VERSION ""

NS_ :

BS_:

BU_: R_STR IAVAS ADAS ADAS_GW ENM THM CHR BAT BEV BEV_GW LCT STA ABG EPS IPMS BST VDC C_ECU C_ECU_GW

BO_ 1370 MCA55A: 8 ADAS_GW
 SG_ MCA55A_0_0_NETWORK_STATUS : 0|64@1+ (1,0) [0|0] ""  C_ECU

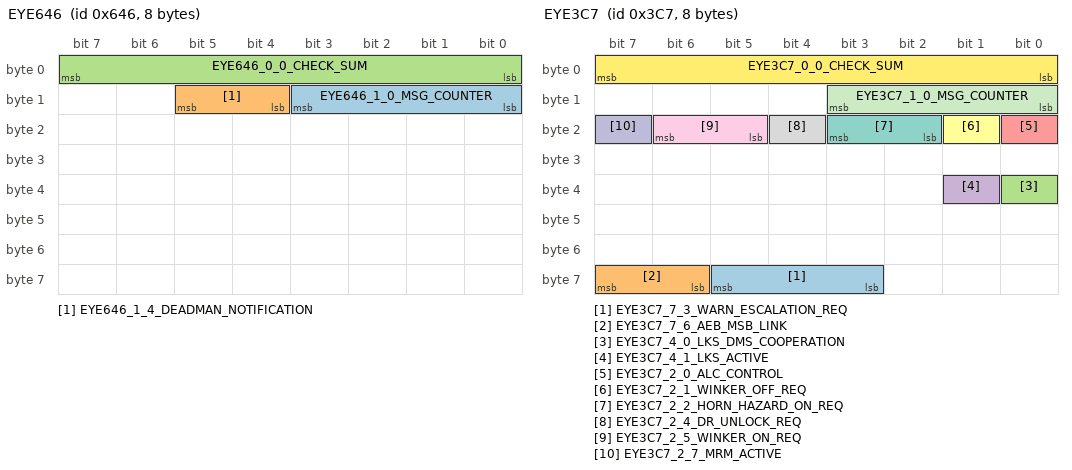
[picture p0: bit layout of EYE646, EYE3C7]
BO_ 1606 EYE646: 8 ADAS
 SG_ EYE646_1_0_MSG_COUNTER : 8|4@1+ (1,0) [0|15] ""  C_ECU_GW
 SG_ EYE646_1_4_DEADMAN_NOTIFICATION : 12|2@1+ (1,0) [0|3] ""  C_ECU_GW
 SG_ EYE646_0_0_CHECK_SUM : 0|8@1+ (1,0) [0|255] ""  C_ECU_GW

BO_ 967 EYE3C7: 8 ADAS
 SG_ EYE3C7_7_3_WARN_ESCALATION_REQ : 59|3@1+ (1,0) [0|7] ""  C_ECU_GW
 SG_ EYE3C7_7_6_AEB_MSB_LINK : 62|2@1+ (1,0) [0|3] ""  C_ECU_GW
 SG_ EYE3C7_4_0_LKS_DMS_COOPERATION : 32|1@1+ (1,0) [0|1] ""  IPMS,C_ECU_GW
 SG_ EYE3C7_4_1_LKS_ACTIVE : 33|1@1+ (1,0) [0|1] ""  IPMS,C_ECU_GW
 SG_ EYE3C7_2_0_ALC_CONTROL : 16|1@1+ (1,0) [0|1] ""  C_ECU_GW
 SG_ EYE3C7_2_1_WINKER_OFF_REQ : 17|1@1+ (1,0) [0|1] ""  C_ECU_GW
 SG_ EYE3C7_2_2_HORN_HAZARD_ON_REQ : 18|2@1+ (1,0) [0|3] ""  C_ECU_GW
 SG_ EYE3C7_2_4_DR_UNLOCK_REQ : 20|1@1+ (1,0) [0|1] ""  C_ECU_GW
 SG_ EYE3C7_2_5_WINKER_ON_REQ : 21|2@1+ (1,0) [0|3] ""  C_ECU_GW
 SG_ EYE3C7_2_7_MRM_ACTIVE : 23|1@1+ (1,0) [0|1] ""  C_ECU_GW
 SG_ EYE3C7_1_0_MSG_COUNTER : 8|4@1+ (1,0) [0|15] ""  IPMS,C_ECU_GW
 SG_ EYE3C7_0_0_CHECK_SUM : 0|8@1+ (1,0) [0|255] ""  IPMS,C_ECU_GW

BO_ 966 EYE3C6: 8 ADAS
 SG_ EYE3C6_7_0_VEHICLE_DIST_L_LANE1 : 56|7@1+ (1,0) [0|27] ""  C_ECU_GW
 SG_ EYE3C6_7_7_VEHICLE_L_LANE1 : 63|1@1+ (1,0) [0|1] ""  C_ECU_GW
 SG_ EYE3C6_6_0_VEHICLE_DIST_R_LANE1 : 48|7@1+ (1,0) [0|27] ""  C_ECU_GW
 SG_ EYE3C6_6_7_VEHICLE_R_LANE1 : 55|1@1+ (1,0) [0|1] ""  C_ECU_GW
 SG_ EYE3C6_5_0_VEHICLE_DIST_WY_WAY1 : 40|7@1+ (1,0) [0|27] ""  C_ECU_GW
 SG_ EYE3C6_5_7_VEHICLE_MY_WAY1 : 47|1@1+ (1,0) [0|1] ""  C_ECU_GW
 SG_ EYE3C6_4_0_SIDE_MOVEMENT : 32|8@1- (1,0) [-100|100] ""  C_ECU_GW
 SG_ EYE3C6_3_0_RADER_RR : 24|2@1+ (1,0) [0|3] ""  C_ECU_GW
 SG_ EYE3C6_3_2_RADER_RL : 26|2@1+ (1,0) [0|3] ""  C_ECU_GW
 SG_ EYE3C6_3_4_RADER_FR : 28|2@1+ (1,0) [0|3] ""  C_ECU_GW
 SG_ EYE3C6_3_6_RADER_FL : 30|2@1+ (1,0) [0|3] ""  C_ECU_GW
 SG_ EYE3C6_2_0_RADER_R : 16|2@1+ (1,0) [0|3] ""  C_ECU_GW
 SG_ EYE3C6_2_2_MY_WAY_LANE_CAR_COLOR : 18|2@1+ (1,0) [0|3] ""  C_ECU_GW
 SG_ EYE3C6_2_4_TARGET_CAR : 20|3@1+ (1,0) [0|7] ""  C_ECU_GW
 SG_ EYE3C6_2_7_ALC_STS : 23|1@1+ (1,0) [0|1] ""  C_ECU_GW
 SG_ EYE3C6_1_0_MSG_COUNTER : 8|4@1+ (1,0) [0|15] ""  C_ECU_GW
 SG_ EYE3C6_1_4_L_LANE_CAR_COLOR : 12|2@1+ (1,0) [0|3] ""  C_ECU_GW
 SG_ EYE3C6_1_6_R_LANE_CAR_COLOR : 14|2@1+ (1,0) [0|3] ""  C_ECU_GW
 SG_ EYE3C6_0_0_CHECK_SUM : 0|8@1+ (1,0) [0|255] ""  C_ECU_GW

BO_ 965 EYE3C5: 8 ADAS
 SG_ EYE3C5_7_0_GSR_AEBS_FUNC_INFO : 56|1@1+ (1,0) [0|1] ""  C_ECU_GW
 SG_ EYE3C5_7_1_CSTM_CRV_ADJUST : 57|2@1+ (1,0) [0|3] ""  C_ECU_GW
 SG_ EYE3C5_7_3_BRAKE_HAPTIC_CURR : 59|2@1+ (1,0) [0|3] ""  C_ECU_GW
 SG_ EYE3C5_7_5_SAFETY_MODE_FUNC_INFO : 61|1@1+ (1,0) [0|1] ""  C_ECU_GW
 SG_ EYE3C5_7_6_SAFETY_MODE_CURR : 62|1@1+ (1,0) [0|1] ""  C_ECU_GW
 SG_ EYE3C5_7_7_GSR_DDAW_FUNC_INFO : 63|1@1+ (1,0) [0|1] ""  C_ECU_GW
 SG_ EYE3C5_6_0_IND_SAFETY_MODE : 48|1@1+ (1,0) [0|1] ""  C_ECU_GW
 SG_ EYE3C5_6_1_ALC_ACTIVE_L : 49|1@1+ (1,0) [0|1] ""  C_ECU_GW
 SG_ EYE3C5_6_2_FLASHING_IND_SAFETY : 50|1@1+ (1,0) [0|1] ""  C_ECU_GW
 SG_ EYE3C5_6_3_OVERTAKE_FUNC_INFO : 51|1@1+ (1,0) [0|1] ""  C_ECU_GW
 SG_ EYE3C5_6_4_CRV_ADJUST_FUNC_INFO : 52|1@1+ (1,0) [0|1] ""  C_ECU_GW
 SG_ EYE3C5_6_5_STRG_TOUCHSENSOR_WRNG : 53|1@1+ (1,0) [0|1] ""  C_ECU_GW
 SG_ EYE3C5_6_6_ALC_ACTIVE_R : 54|1@1+ (1,0) [0|1] ""  C_ECU_GW
 SG_ EYE3C5_6_7_CSTM_GSR_ISA : 55|1@1+ (1,0) [0|1] ""  C_ECU_GW
 SG_ EYE3C5_5_0_LANE_COLOR_R : 40|2@1+ (1,0) [0|3] ""  C_ECU_GW
 SG_ EYE3C5_5_2_LINE_LANE_R : 42|2@1+ (1,0) [0|3] ""  C_ECU_GW
 SG_ EYE3C5_5_4_LANE_COLOR_L : 44|2@1+ (1,0) [0|3] ""  C_ECU_GW
 SG_ EYE3C5_5_6_LINE_LANE_L : 46|2@1+ (1,0) [0|3] ""  C_ECU_GW
 SG_ EYE3C5_4_0_ROAD_SHAPE_CURVE : 32|4@1+ (1,0) [0|15] ""  C_ECU_GW
 SG_ EYE3C5_4_4_ROAD_SHAPE_DIRECTION : 36|1@1+ (1,0) [0|1] ""  C_ECU_GW
 SG_ EYE3C5_4_5_CSTM_GSR_ELKS : 37|1@1+ (1,0) [0|1] ""  C_ECU_GW
 SG_ EYE3C5_4_6_MY_WAY_COLOR : 38|2@1+ (1,0) [0|3] ""  C_ECU_GW
 SG_ EYE3C5_3_0_AD_DRV_ICON : 24|2@1+ (1,0) [0|3] ""  C_ECU,C_ECU_GW
 SG_ EYE3C5_3_2_AUTO_HANDLE_ICON : 26|2@1+ (1,0) [0|3] ""  C_ECU_GW
 SG_ EYE3C5_3_4_WITH_HANDS_ICON : 28|1@1+ (1,0) [0|1] ""  C_ECU_GW
 SG_ EYE3C5_3_5_STRG_HAPTIC_WRNG : 29|1@1+ (1,0) [0|1] ""  C_ECU_GW
 SG_ EYE3C5_3_6_BRK_HPTC_FUNC_INFO : 30|1@1+ (1,0) [0|1] ""  C_ECU_GW
 SG_ EYE3C5_3_7_SPECIAL_DISP_INFO : 31|1@1+ (1,0) [0|1] ""  C_ECU_GW
 SG_ EYE3C5_2_0_SLOWDWN_CURVE_ICON : 16|3@1+ (1,0) [0|7] ""  C_ECU_GW
 SG_ EYE3C5_2_3_FLASHING_IND : 19|1@1+ (1,0) [0|1] ""  C_ECU_GW
 SG_ EYE3C5_2_4_ATTENTION_TOLLGATE : 20|2@1+ (1,0) [0|3] ""  C_ECU_GW
 SG_ EYE3C5_2_6_MAPLOCATOR_IND : 22|2@1+ (1,0) [0|3] ""  C_ECU_GW
 SG_ EYE3C5_1_0_MSG_COUNTER : 8|4@1+ (1,0) [0|15] ""  C_ECU_GW
 SG_ EYE3C5_1_4_ISA_FAIL_IND : 12|1@1+ (1,0) [0|1] ""  C_ECU_GW
 SG_ EYE3C5_1_5_SLWF_OFF_IND : 13|1@1+ (1,0) [0|1] ""  C_ECU_GW
 SG_ EYE3C5_1_6_CSTM_SLWF_SET : 14|1@1+ (1,0) [0|1] ""  C_ECU_GW
 SG_ EYE3C5_1_7_CSTM_TSR_SOUND_SET : 15|1@1+ (1,0) [0|1] ""  C_ECU_GW
 SG_ EYE3C5_0_0_CHECK_SUM : 0|8@1+ (1,0) [0|255] ""  C_ECU_GW

BO_ 964 EYE3C4: 8 ADAS
 SG_ EYE3C4_7_0_PCR_FAIL_OFF_IND : 56|2@1+ (1,0) [0|3] ""  C_ECU_GW
 SG_ EYE3C4_7_2_AES_FAIL_OFF_IND : 58|2@1+ (1,0) [0|3] ""  C_ECU_GW
 SG_ EYE3C4_7_4_LDP_FAIL_OFF_IND : 60|2@1+ (1,0) [0|3] ""  C_ECU_GW
 SG_ EYE3C4_7_6_ELK_FAIL_OFF_IND : 62|2@1+ (1,0) [0|3] ""  C_ECU_GW
 SG_ EYE3C4_6_0_MCAM_SYS_FAIL_HALT : 48|2@1+ (1,0) [0|3] ""  C_ECU_GW
 SG_ EYE3C4_6_2_MCAM_FUNC_INFO : 50|1@1+ (1,0) [0|1] ""  C_ECU_GW
 SG_ EYE3C4_6_3_EYE_DRV_ACTION_REQ : 51|3@1+ (1,0) [0|7] ""  C_ECU_GW
 SG_ EYE3C4_6_6_LDW_SND_OFF_FAIL_IND : 54|2@1+ (1,0) [0|3] ""  C_ECU_GW
 SG_ EYE3C4_5_0_EAM_GREEN : 40|2@1+ (1,0) [0|3] ""  C_ECU_GW
 SG_ EYE3C4_5_2_EAM_BLUE : 42|2@1+ (1,0) [0|3] ""  C_ECU_GW
 SG_ EYE3C4_5_4_EAM_GREEN_2 : 44|2@1+ (1,0) [0|3] ""  C_ECU_GW
 SG_ EYE3C4_5_6_FCW_SND_OFF_FAIL_IND : 46|2@1+ (1,0) [0|3] ""  C_ECU_GW
 SG_ EYE3C4_4_0_EAM_YELLOW : 32|4@1+ (1,0) [0|15] ""  C_ECU_GW
 SG_ EYE3C4_4_4_EAM_RED : 36|4@1+ (1,0) [0|15] ""  C_ECU_GW
 SG_ EYE3C4_3_0_CODE_NO_BUZZER : 24|8@1+ (1,0) [0|255] ""  C_ECU_GW
 SG_ EYE3C4_2_0_CODE_WARN : 16|8@1+ (1,0) [0|255] ""  C_ECU_GW
 SG_ EYE3C4_1_0_MSG_COUNTER : 8|4@1+ (1,0) [0|15] ""  C_ECU_GW
 SG_ EYE3C4_1_5_SNR_DRV_ACTION_REQ : 13|3@1+ (1,0) [0|7] ""  C_ECU_GW
 SG_ EYE3C4_0_0_CHECK_SUM : 0|8@1+ (1,0) [0|255] ""  C_ECU_GW

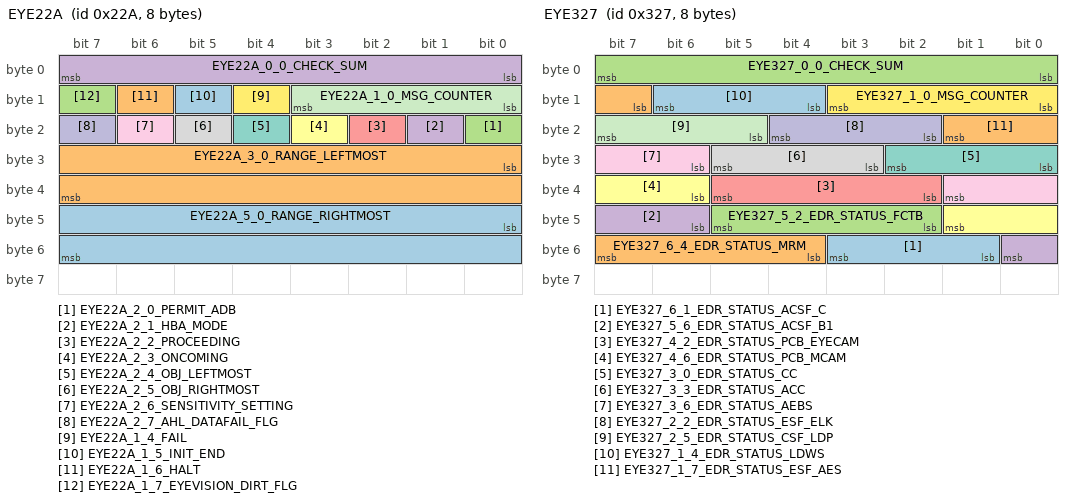
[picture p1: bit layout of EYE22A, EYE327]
BO_ 554 EYE22A: 8 ADAS
 SG_ EYE22A_5_0_RANGE_RIGHTMOST : 40|16@1- (0.1,0) [-3276.8|3276.7] "deg"  C_ECU_GW
 SG_ EYE22A_3_0_RANGE_LEFTMOST : 24|16@1- (0.1,0) [-3276.8|3276.7] "deg"  C_ECU_GW
 SG_ EYE22A_2_0_PERMIT_ADB : 16|1@1+ (1,0) [0|1] ""  C_ECU_GW
 SG_ EYE22A_2_1_HBA_MODE : 17|1@1+ (1,0) [0|1] ""  C_ECU,C_ECU_GW
 SG_ EYE22A_2_2_PROCEEDING : 18|1@1+ (1,0) [0|1] ""  C_ECU_GW
 SG_ EYE22A_2_3_ONCOMING : 19|1@1+ (1,0) [0|1] ""  C_ECU_GW
 SG_ EYE22A_2_4_OBJ_LEFTMOST : 20|1@1+ (1,0) [0|1] ""  C_ECU_GW
 SG_ EYE22A_2_5_OBJ_RIGHTMOST : 21|1@1+ (1,0) [0|1] ""  C_ECU_GW
 SG_ EYE22A_2_6_SENSITIVITY_SETTING : 22|1@1+ (1,0) [0|1] ""  C_ECU,C_ECU_GW
 SG_ EYE22A_2_7_AHL_DATAFAIL_FLG : 23|1@1+ (1,0) [0|1] ""  C_ECU_GW
 SG_ EYE22A_1_0_MSG_COUNTER : 8|4@1+ (1,0) [0|15] ""  C_ECU,C_ECU_GW
 SG_ EYE22A_1_4_FAIL : 12|1@1+ (1,0) [0|1] ""  C_ECU,C_ECU_GW
 SG_ EYE22A_1_5_INIT_END : 13|1@1+ (1,0) [0|1] ""  C_ECU,C_ECU_GW
 SG_ EYE22A_1_6_HALT : 14|1@1+ (1,0) [0|1] ""  C_ECU,C_ECU_GW
 SG_ EYE22A_1_7_EYEVISION_DIRT_FLG : 15|1@1+ (1,0) [0|1] ""  C_ECU_GW
 SG_ EYE22A_0_0_CHECK_SUM : 0|8@1+ (1,0) [0|255] ""  C_ECU,C_ECU_GW

BO_ 807 EYE327: 8 ADAS
 SG_ EYE327_6_1_EDR_STATUS_ACSF_C : 49|3@1+ (1,0) [0|7] ""  ABG
 SG_ EYE327_6_4_EDR_STATUS_MRM : 52|4@1+ (1,0) [0|15] ""  ABG
 SG_ EYE327_5_2_EDR_STATUS_FCTB : 42|4@1+ (1,0) [0|15] ""  ABG
 SG_ EYE327_5_6_EDR_STATUS_ACSF_B1 : 46|3@1+ (1,0) [0|7] ""  ABG
 SG_ EYE327_4_2_EDR_STATUS_PCB_EYECAM : 34|4@1+ (1,0) [0|15] ""  ABG
 SG_ EYE327_4_6_EDR_STATUS_PCB_MCAM : 38|4@1+ (1,0) [0|15] ""  ABG
 SG_ EYE327_3_0_EDR_STATUS_CC : 24|3@1+ (1,0) [0|7] ""  ABG
 SG_ EYE327_3_3_EDR_STATUS_ACC : 27|3@1+ (1,0) [0|7] ""  ABG
 SG_ EYE327_3_6_EDR_STATUS_AEBS : 30|4@1+ (1,0) [0|15] ""  ABG
 SG_ EYE327_2_2_EDR_STATUS_ESF_ELK : 18|3@1+ (1,0) [0|7] ""  ABG
 SG_ EYE327_2_5_EDR_STATUS_CSF_LDP : 21|3@1+ (1,0) [0|7] ""  ABG
 SG_ EYE327_1_0_MSG_COUNTER : 8|4@1+ (1,0) [0|15] ""  ABG
 SG_ EYE327_1_4_EDR_STATUS_LDWS : 12|3@1+ (1,0) [0|7] ""  ABG
 SG_ EYE327_1_7_EDR_STATUS_ESF_AES : 15|3@1+ (1,0) [0|7] ""  ABG
 SG_ EYE327_0_0_CHECK_SUM : 0|8@1+ (1,0) [0|255] ""  ABG

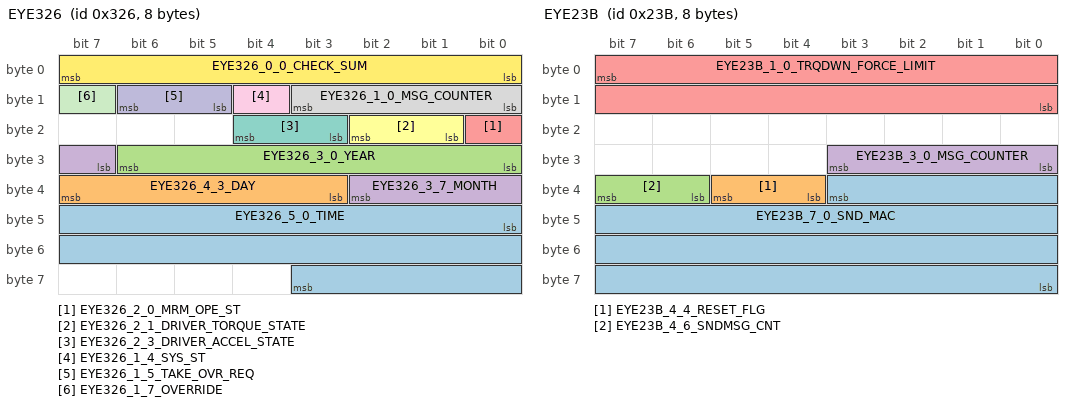
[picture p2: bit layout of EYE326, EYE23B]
BO_ 806 EYE326: 8 ADAS
 SG_ EYE326_5_0_TIME : 40|20@1+ (0.1,0) [0|86399.9] "sec"  C_ECU_GW
 SG_ EYE326_4_3_DAY : 35|5@1+ (1,0) [1|31] "日"  C_ECU_GW
 SG_ EYE326_3_0_YEAR : 24|7@1+ (1,2000) [2000|2126] "年"  C_ECU_GW
 SG_ EYE326_3_7_MONTH : 31|4@1+ (1,0) [1|12] "月"  C_ECU_GW
 SG_ EYE326_2_0_MRM_OPE_ST : 16|1@1+ (1,0) [0|1] ""  C_ECU_GW
 SG_ EYE326_2_1_DRIVER_TORQUE_STATE : 17|2@1+ (1,0) [0|3] ""  C_ECU_GW
 SG_ EYE326_2_3_DRIVER_ACCEL_STATE : 19|2@1+ (1,0) [0|3] ""  C_ECU_GW
 SG_ EYE326_1_0_MSG_COUNTER : 8|4@1+ (1,0) [0|15] ""  C_ECU_GW
 SG_ EYE326_1_4_SYS_ST : 12|1@1+ (1,0) [0|1] ""  C_ECU_GW
 SG_ EYE326_1_5_TAKE_OVR_REQ : 13|2@1+ (1,0) [0|3] ""  C_ECU_GW
 SG_ EYE326_1_7_OVERRIDE : 15|1@1+ (1,0) [0|1] ""  C_ECU_GW
 SG_ EYE326_0_0_CHECK_SUM : 0|8@1+ (1,0) [0|255] ""  C_ECU_GW

BO_ 805 EYE325: 8 ADAS
 SG_ EYE325_6_5_SONAR_DISP_INT : 53|1@1+ (1,0) [0|1] ""  C_ECU_GW
 SG_ EYE325_5_0_SONAR_R_L_CORNER_4LVL : 40|3@1+ (1,0) [0|7] ""  C_ECU_GW
 SG_ EYE325_5_3_SONAR_R_R_CORNER_4LVL : 43|3@1+ (1,0) [0|7] ""  C_ECU_GW
 SG_ EYE325_4_0_SONAR_R_CENTER : 32|3@1+ (1,0) [0|7] ""  C_ECU_GW
 SG_ EYE325_4_3_SONAR_LEVEL : 35|3@1+ (1,0) [0|7] ""  C_ECU_GW
 SG_ EYE325_4_6_RAB_WARNING : 38|2@1+ (1,0) [0|3] ""  C_ECU_GW
 SG_ EYE325_3_0_SONAR_R_L_CORNER : 24|2@1+ (1,0) [0|3] ""  C_ECU_GW
 SG_ EYE325_3_2_SONAR_R_R_CORNER : 26|2@1+ (1,0) [0|3] ""  C_ECU_GW
 SG_ EYE325_3_4_SONAR_R_L_SIDE : 28|2@1+ (1,0) [0|3] ""  C_ECU_GW
 SG_ EYE325_3_6_SONAR_R_R_SIDE : 30|2@1+ (1,0) [0|3] ""  C_ECU_GW
 SG_ EYE325_2_0_RAB_OFF : 16|1@1+ (1,0) [0|1] ""  C_ECU_GW
 SG_ EYE325_2_1_SONAR_OFF : 17|1@1+ (1,0) [0|1] ""  C_ECU_GW
 SG_ EYE325_2_2_SONAR_SYS_HALT : 18|2@1+ (1,0) [0|3] ""  C_ECU_GW
 SG_ EYE325_2_4_SONAR_SYS_FAIL : 20|2@1+ (1,0) [0|3] ""  C_ECU_GW
 SG_ EYE325_2_6_RAB_DISABLE : 22|1@1+ (1,0) [0|1] ""  C_ECU_GW
 SG_ EYE325_2_7_SONAR_DISABLE : 23|1@1+ (1,0) [0|1] ""  C_ECU_GW
 SG_ EYE325_1_0_MSG_COUNTER : 8|4@1+ (1,0) [0|15] ""  C_ECU_GW
 SG_ EYE325_1_4_CSTM_RAB_SET : 12|1@1+ (1,0) [0|1] ""  C_ECU_GW
 SG_ EYE325_1_5_CSTM_CLR_SNR_SET : 13|1@1+ (1,0) [0|1] ""  C_ECU_GW
 SG_ EYE325_1_6_RAB : 14|1@1+ (1,0) [0|1] ""  C_ECU_GW
 SG_ EYE325_1_7_SONAR_NO_DISP : 15|1@1+ (1,0) [0|1] ""  C_ECU_GW
 SG_ EYE325_0_0_CHECK_SUM : 0|8@1+ (1,0) [0|255] ""  C_ECU_GW

BO_ 804 EYE324: 8 ADAS
 SG_ EYE324_7_5_TSR_MODE_DISP : 61|2@1+ (1,0) [0|3] ""  C_ECU_GW
 SG_ EYE324_7_7_ICON_IND : 63|1@1+ (1,0) [0|1] ""  C_ECU_GW
 SG_ EYE324_6_0_COMPLEMENTARY_IND_C : 48|4@1+ (1,0) [0|15] ""  C_ECU_GW
 SG_ EYE324_6_4_COMPLEMENTARY_IND_D : 52|4@1+ (1,0) [0|15] ""  C_ECU_GW
 SG_ EYE324_5_0_SPEEDLIMIT_B : 40|8@1+ (1,0) [0|255] ""  C_ECU_GW
 SG_ EYE324_4_0_TRAFFIC_SIGN_B : 32|5@1+ (1,0) [0|31] ""  C_ECU_GW
 SG_ EYE324_4_5_FLASHING_IND_B : 37|1@1+ (1,0) [0|1] ""  C_ECU_GW
 SG_ EYE324_4_6_FRAME_COLOR_B : 38|2@1+ (1,0) [0|3] ""  C_ECU_GW
 SG_ EYE324_3_0_SPEEDLIMIT_A : 24|8@1+ (1,0) [0|255] ""  C_ECU_GW
 SG_ EYE324_2_0_TRAFFIC_SIGN_A : 16|5@1+ (1,0) [0|31] ""  C_ECU_GW
 SG_ EYE324_2_5_FLASHING_IND_A : 21|1@1+ (1,0) [0|1] ""  C_ECU_GW
 SG_ EYE324_2_6_FRAME_COLOR_A : 22|2@1+ (1,0) [0|3] ""  C_ECU_GW
 SG_ EYE324_1_0_MSG_COUNTER : 8|4@1+ (1,0) [0|15] ""  C_ECU_GW
 SG_ EYE324_1_4_FLASHING_IND_D : 12|1@1+ (1,0) [0|1] ""  C_ECU_GW
 SG_ EYE324_1_5_FLASHING_IND_C : 13|1@1+ (1,0) [0|1] ""  C_ECU_GW
 SG_ EYE324_1_6_ICON_COLOR : 14|2@1+ (1,0) [0|3] ""  C_ECU_GW
 SG_ EYE324_0_0_CHECK_SUM : 0|8@1+ (1,0) [0|255] ""  C_ECU_GW

BO_ 803 EYE323: 8 ADAS
 SG_ EYE323_7_0_ISA_OFFSET_CURR : 56|5@1+ (1,-10) [-10|10] ""  C_ECU_GW
 SG_ EYE323_7_5_SLIF_FUNC_INFO : 61|1@1+ (1,0) [0|1] ""  C_ECU_GW
 SG_ EYE323_7_6_ISA_FUNC_INFO : 62|1@1+ (1,0) [0|1] ""  C_ECU_GW
 SG_ EYE323_7_7_ISA_CUSTOMIZE_CURR : 63|1@1+ (1,0) [0|1] ""  C_ECU_GW
 SG_ EYE323_6_0_LDW_OFFSW_INFO : 48|1@1+ (1,0) [0|1] ""  C_ECU_GW
 SG_ EYE323_6_1_LDW_ON_OFF_SET : 49|1@1+ (1,0) [0|1] ""  C_ECU_GW
 SG_ EYE323_6_2_CSTM_DDAW_WARN_SET : 50|1@1+ (1,0) [0|1] ""  C_ECU_GW
 SG_ EYE323_6_3_IACC_FUNC_INFO : 51|1@1+ (1,0) [0|1] ""  C_ECU_GW
 SG_ EYE323_6_5_CSTM_LDW_TIMING_SET : 53|1@1+ (1,0) [0|1] ""  C_ECU_GW
 SG_ EYE323_6_6_CSTM_LDW_TIMING : 54|1@1+ (1,0) [0|1] ""  C_ECU_GW
 SG_ EYE323_6_7_SLOWDOWNL_FUNC_INFO : 55|1@1+ (1,0) [0|1] ""  C_ECU_GW
 SG_ EYE323_5_0_CNG_GRN_CONT_CURR : 40|1@1+ (1,0) [0|1] ""  C_ECU_GW
 SG_ EYE323_5_1_TRAFFIC_FUNC_INFO : 41|1@1+ (1,0) [0|1] ""  C_ECU_GW
 SG_ EYE323_5_2_FCW_OFFSW_INFO : 42|1@1+ (1,0) [0|1] ""  C_ECU_GW
 SG_ EYE323_5_3_FCW_ON_OFF_SET : 43|1@1+ (1,0) [0|1] ""  C_ECU_GW
 SG_ EYE323_5_4_WARNING_SEL_CURR : 44|1@1+ (1,0) [0|1] ""  C_ECU_GW
 SG_ EYE323_5_5_HAPT_FUNC_INFO : 45|1@1+ (1,0) [0|1] ""  C_ECU_GW
 SG_ EYE323_5_6_TOLLGATE_CONT_CURR : 46|1@1+ (1,0) [0|1] ""  C_ECU_GW
 SG_ EYE323_5_7_CURVE_CONT_CURR : 47|1@1+ (1,0) [0|1] ""  C_ECU_GW
 SG_ EYE323_4_0_FCTB_ICON_L : 32|2@1+ (1,0) [0|3] ""  C_ECU_GW
 SG_ EYE323_4_2_FCTB_ICON_R : 34|2@1+ (1,0) [0|3] ""  C_ECU_GW
 SG_ EYE323_4_4_FCW_CONT_CURR : 36|2@1+ (1,0) [0|3] ""  C_ECU_GW
 SG_ EYE323_4_6_FCW_DISPLAY_SEL : 38|2@1+ (1,0) [0|3] ""  C_ECU_GW
 SG_ EYE323_3_0_AES_FUNC_INFO : 24|1@1+ (1,0) [0|1] ""  C_ECU_GW
 SG_ EYE323_3_1_CSTM_TSR_NO_ENTRY_SET : 25|1@1+ (1,0) [0|1] ""  C_ECU_GW
 SG_ EYE323_3_2_CSTM_TSR_STOP_SET : 26|1@1+ (1,0) [0|1] ""  C_ECU_GW
 SG_ EYE323_3_3_CSTM_TSR_GIVE_WAY_SET : 27|1@1+ (1,0) [0|1] ""  C_ECU_GW
 SG_ EYE323_3_4_WILDERNESS : 28|1@1+ (1,0) [0|1] ""  C_ECU_GW
 SG_ EYE323_3_5_AES_OFF : 29|1@1+ (1,0) [0|1] ""  C_ECU_GW
 SG_ EYE323_3_6_FCTB_IND : 30|2@1+ (1,0) [0|3] ""  C_ECU_GW
 SG_ EYE323_2_0_CSTM_LDW_ALK_B : 16|2@1+ (1,0) [0|3] ""  C_ECU_GW
 SG_ EYE323_2_2_CSTM_P_CR : 18|1@1+ (1,0) [0|1] ""  C_ECU_GW
 SG_ EYE323_2_3_SLOWDOWN_FUNC_INFO2 : 19|1@1+ (1,0) [0|1] ""  C_ECU_GW
 SG_ EYE323_2_4_CID_CODE_WARN : 20|4@1+ (1,0) [0|15] ""  C_ECU_GW
 SG_ EYE323_1_0_MSG_COUNTER : 8|4@1+ (1,0) [0|15] ""  C_ECU_GW
 SG_ EYE323_1_4_DISP_FOLLOW_FORWARD : 12|1@1+ (1,0) [0|1] ""  C_ECU_GW
 SG_ EYE323_1_5_KEEP_LINE_SENTER_ACT : 13|1@1+ (1,0) [0|1] ""  C_ECU_GW
 SG_ EYE323_1_6_DDAW_FAIL_OFF : 14|2@1+ (1,0) [0|3] ""  C_ECU_GW
 SG_ EYE323_0_0_CHECK_SUM : 0|8@1+ (1,0) [0|255] ""  C_ECU_GW

BO_ 802 EYE322: 8 ADAS
 SG_ EYE322_7_0_CSTM_ACC_CONT_SET : 56|2@1+ (1,0) [0|3] ""  C_ECU_GW
 SG_ EYE322_7_2_ELK_OFF_IND : 58|1@1+ (1,0) [0|1] ""  C_ECU_GW
 SG_ EYE322_7_3_LIGHT_EAM_YELLOW : 59|2@1+ (1,0) [0|3] ""  C_ECU_GW
 SG_ EYE322_7_5_BROKEN_LINE_L : 61|1@1+ (1,0) [0|1] ""  C_ECU_GW
 SG_ EYE322_7_6_TJA_ACTIVE : 62|1@1+ (1,0) [0|1] ""  C_ECU_GW
 SG_ EYE322_7_7_BROKEN_LINE_R : 63|1@1+ (1,0) [0|1] ""  C_ECU_GW
 SG_ EYE322_6_0_CSTM_MIS_AT_START : 48|2@1+ (1,0) [0|3] ""  C_ECU_GW
 SG_ EYE322_6_2_CSTM_ALK_TJA_SET : 50|1@1+ (1,0) [0|1] ""  C_ECU_GW
 SG_ EYE322_6_3_CSTM_LANE_SET : 51|1@1+ (1,0) [0|1] ""  C_ECU_GW
 SG_ EYE322_6_4_LDP_OFF_IND : 52|1@1+ (1,0) [0|1] ""  C_ECU_GW
 SG_ EYE322_6_5_INDICATOR_MODE_L : 53|2@1+ (1,0) [0|3] ""  C_ECU_GW
 SG_ EYE322_6_7_CSTM_ELK_SET : 55|1@1+ (1,0) [0|1] ""  C_ECU_GW
 SG_ EYE322_5_0_CSTM_MIS_AT_BACK : 40|1@1+ (1,0) [0|1] ""  C_ECU_GW
 SG_ EYE322_5_1_CSTM_ALK_TJA : 41|1@1+ (1,0) [0|1] ""  C_ECU_GW
 SG_ EYE322_5_2_CSTM_SAS : 42|1@1+ (1,0) [0|1] ""  C_ECU_GW
 SG_ EYE322_5_3_CSTM_HBA : 43|1@1+ (1,0) [0|1] ""  C_ECU_GW
 SG_ EYE322_5_4_CSTM_ACC_CONT : 44|1@1+ (1,0) [0|1] ""  C_ECU_GW
 SG_ EYE322_5_5_CSTM_LANE : 45|1@1+ (1,0) [0|1] ""  C_ECU_GW
 SG_ EYE322_5_6_LDW_SOUND_OFF_IND : 46|1@1+ (1,0) [0|1] ""  C_ECU_GW
 SG_ EYE322_5_7_CSTM_ELK_SET : 47|1@1+ (1,0) [0|1] ""  C_ECU_GW
 SG_ EYE322_4_0_CODE_WARN : 32|5@1+ (1,0) [0|31] ""  C_ECU_GW
 SG_ EYE322_4_5_CSTM_GSR : 37|1@1+ (1,0) [0|1] ""  C_ECU_GW
 SG_ EYE322_3_0_LANE_L : 24|2@1+ (1,0) [0|3] ""  C_ECU_GW
 SG_ EYE322_3_2_LANE_R : 26|2@1+ (1,0) [0|3] ""  C_ECU_GW
 SG_ EYE322_3_4_LANE_L_COLOR : 28|2@1+ (1,0) [0|3] ""  C_ECU_GW
 SG_ EYE322_3_6_LANE_R_COLOR : 30|2@1+ (1,0) [0|3] ""  C_ECU_GW
 SG_ EYE322_2_0_FCW_OFF_IND : 16|1@1+ (1,0) [0|1] ""  C_ECU_GW
 SG_ EYE322_2_1_MOV_EYESIGHT_SCREEN : 17|1@1+ (1,0) [0|1] ""  C_ECU_GW
 SG_ EYE322_2_2_ALK_ICON : 18|2@1+ (1,0) [0|3] ""  C_ECU,C_ECU_GW
 SG_ EYE322_2_4_INDICATOR_CTRL_REQ : 20|1@1+ (1,0) [0|1] ""  C_ECU_GW
 SG_ EYE322_2_5_INDICATOR_MODE_R : 21|2@1+ (1,0) [0|3] ""  C_ECU_GW
 SG_ EYE322_2_7_LIMITER_BACK_SPEED : 23|1@1+ (1,0) [0|1] ""  C_ECU_GW
 SG_ EYE322_1_0_MSG_COUNTER : 8|4@1+ (1,0) [0|15] ""  IPMS,C_ECU_GW
 SG_ EYE322_1_4_CODE_NO_BUZZER : 12|3@1+ (1,0) [0|7] ""  C_ECU_GW
 SG_ EYE322_1_7_DISTWARN_DMS : 15|1@1+ (1,0) [0|1] ""  IPMS,C_ECU_GW
 SG_ EYE322_0_0_CHECK_SUM : 0|8@1+ (1,0) [0|255] ""  IPMS,C_ECU_GW

BO_ 801 EYE321: 8 ADAS
 SG_ EYE321_7_0_INFO_DIST_FORWARD : 56|4@1+ (1,0) [0|15] ""  C_ECU_GW
 SG_ EYE321_7_4_INFO_KEEP_STOP : 60|1@1+ (1,0) [0|1] ""  C_ECU_GW
 SG_ EYE321_7_5_INFO_READY : 61|1@1+ (1,0) [0|1] ""  C_ECU_GW
 SG_ EYE321_7_6_INFO_SET_CC : 62|1@1+ (1,0) [0|1] ""  C_ECU_GW
 SG_ EYE321_7_7_INFO_OFF : 63|1@1+ (1,0) [0|1] ""  C_ECU_GW
 SG_ EYE321_6_0_FAIL_EYESIGHT : 48|1@1+ (1,0) [0|1] ""  C_ECU_GW
 SG_ EYE321_6_1_MOV_EYESIGHT_SCREEN : 49|1@1+ (1,0) [0|1] ""  C_ECU_GW
 SG_ EYE321_6_2_IND_VEHICLE : 50|1@1+ (1,0) [0|1] ""  C_ECU_GW
 SG_ EYE321_6_3_BRAKELAMP_VEHICLE : 51|1@1+ (1,0) [0|1] ""  C_ECU_GW
 SG_ EYE321_6_4_IND_FORWARD_VECL : 52|1@1+ (1,0) [0|1] ""  C_ECU_GW
 SG_ EYE321_6_5_BRAKELAMP_FORWARD : 53|1@1+ (1,0) [0|1] ""  C_ECU_GW
 SG_ EYE321_6_6_CC_OR_LIM_SON : 54|1@1+ (1,0) [0|1] ""  C_ECU_GW
 SG_ EYE321_6_7_TEMP_OFF_STATE : 55|1@1+ (1,0) [0|1] ""  C_ECU_GW
 SG_ EYE321_5_0_INFO_SET_SPD : 40|8@1+ (1,0) [0|255] "km/h or MPH"  C_ECU_GW
 SG_ EYE321_4_0_ACC_MODE : 32|2@1+ (1,0) [0|3] ""  C_ECU,C_ECU_GW
 SG_ EYE321_4_2_SRVD_LASTMEM_ST_REQ : 34|1@1+ (1,0) [0|1] ""  C_ECU_GW
 SG_ EYE321_4_3_INFO_MAIN_CC : 35|2@1+ (1,0) [0|3] ""  C_ECU,C_ECU_GW
 SG_ EYE321_4_5_TRAFFIC_LIGHT : 37|3@1+ (1,0) [0|7] ""  C_ECU_GW
 SG_ EYE321_3_0_CODE_HALT : 24|3@1+ (1,0) [0|7] ""  C_ECU_GW
 SG_ EYE321_3_3_ELK_EQUIP : 27|1@1+ (1,0) [0|1] ""  C_ECU_GW
 SG_ EYE321_3_4_SET_DIST : 28|3@1+ (1,0) [0|7] ""  C_ECU_GW
 SG_ EYE321_3_7_TJA : 31|1@1+ (1,0) [0|1] ""  C_ECU_GW
 SG_ EYE321_2_0_ACC_CANCEL_OR_CSTM : 16|4@1+ (1,0) [0|15] ""  C_ECU_GW
 SG_ EYE321_2_4_ALK_CANCEL_OR_CSTM : 20|3@1+ (1,0) [0|7] ""  C_ECU_GW
 SG_ EYE321_2_7_ALK_CANCEL_DISP_TYPE : 23|1@1+ (1,0) [0|1] ""  C_ECU_GW
 SG_ EYE321_1_0_MSG_COUNTER : 8|4@1+ (1,0) [0|15] ""  C_ECU_GW
 SG_ EYE321_1_4_PRECRASH_BRAKE_OFF : 12|1@1+ (1,0) [0|1] ""  C_ECU_GW
 SG_ EYE321_1_5_LANE_DEPARTURE_OFF : 13|1@1+ (1,0) [0|1] ""  C_ECU_GW
 SG_ EYE321_1_6_MET_AD_DRV_ASS : 14|1@1+ (1,0) [0|1] ""  C_ECU_GW
 SG_ EYE321_1_7_ALC_EQUIP : 15|1@1+ (1,0) [0|1] ""  C_ECU_GW
 SG_ EYE321_0_0_CHECK_SUM : 0|8@1+ (1,0) [0|255] ""  C_ECU_GW

BO_ 571 EYE23B: 8 ADAS
 SG_ EYE23B_7_0_SND_MAC : 35|28@0+ (1,0) [0|268435455] "" Vector__XXX
 SG_ EYE23B_4_4_RESET_FLG : 37|2@0+ (1,0) [0|3] "" Vector__XXX
 SG_ EYE23B_4_6_SNDMSG_CNT : 39|2@0+ (1,0) [0|3] "" Vector__XXX
 SG_ EYE23B_3_0_MSG_COUNTER : 27|4@0+ (1,0) [0|15] "" Vector__XXX
 SG_ EYE23B_1_0_TRQDWN_FORCE_LIMIT : 7|16@0+ (1.6,0) [0|408] "Nm" Vector__XXX

BO_ 556 EYE22C: 8 ADAS
 SG_ EYE22C_7_0_COMMANDSW_CC : 56|3@1+ (1,0) [0|7] ""  C_ECU,C_ECU_GW
 SG_ EYE22C_7_3_MODE_CC : 59|1@1+ (1,0) [0|1] ""  C_ECU_GW
 SG_ EYE22C_7_4_CC_SETLAMP_INFO : 60|1@1+ (1,0) [0|1] ""  C_ECU_GW
 SG_ EYE22C_7_5_MSA_CNT_STS_EGI_HEV : 61|1@1+ (1,0) [0|1] ""  C_ECU_GW
 SG_ EYE22C_7_6_SET_MSA : 62|1@1+ (1,0) [0|1] ""  C_ECU_GW
 SG_ EYE22C_7_7_SET_CC : 63|1@1+ (1,0) [0|1] ""  C_ECU_GW
 SG_ EYE22C_5_0_TRQDWN_FORCE_LIMIT : 40|16@1+ (1.6,0) [0|408] "Nm"  C_ECU_GW
 SG_ EYE22C_4_0_BLIPPING_INHI : 32|1@1+ (1,0) [0|1] ""  C_ECU_GW
 SG_ EYE22C_4_4_ACTIVE_BRAKE_ACC : 36|1@1+ (1,0) [0|1] ""  C_ECU_GW
 SG_ EYE22C_4_5_REQ_FMW : 37|1@1+ (1,0) [0|1] ""  C_ECU_GW
 SG_ EYE22C_4_6_FLG_BEFORE_RESERVE : 38|1@1+ (1,0) [0|1] ""  C_ECU_GW
 SG_ EYE22C_4_7_REQ_TARGET_TORQUE : 39|1@1+ (1,0) [0|1] ""  C_ECU_GW
 SG_ EYE22C_2_0_TGT_SPD_TRQ_FORCE : 16|16@1+ (0.1,-1000) [-1000|5553.5] "Nm"  C_ECU_GW
 SG_ EYE22C_1_0_MSG_COUNTER : 8|4@1+ (1,0) [0|15] ""  C_ECU_GW
 SG_ EYE22C_1_4_FLG_ADAPTIVE_CC : 12|1@1+ (1,0) [0|1] ""  C_ECU_GW
 SG_ EYE22C_1_5_MAIN_CC : 13|1@1+ (1,0) [0|1] ""  C_ECU_GW
 SG_ EYE22C_1_6_FLG_EYESIGHT_VERSION : 14|1@1+ (1,0) [0|1] ""  C_ECU_GW
 SG_ EYE22C_1_7_FAIL_EYESIGHT : 15|1@1+ (1,0) [0|1] ""  C_ECU_GW
 SG_ EYE22C_0_0_CHECK_SUM : 0|8@1+ (1,0) [0|255] ""  C_ECU_GW

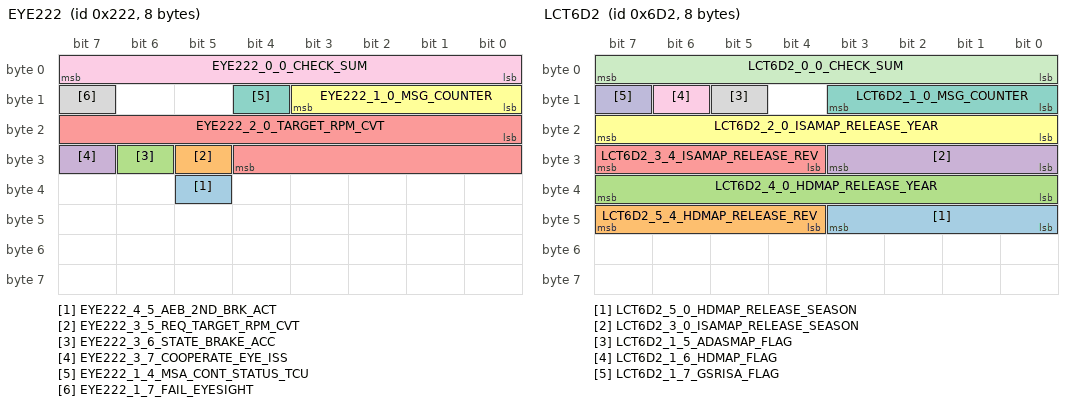
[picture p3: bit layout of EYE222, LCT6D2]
BO_ 546 EYE222: 8 ADAS
 SG_ EYE222_4_5_AEB_2ND_BRK_ACT : 37|1@1+ (1,0) [0|1] "" Vector__XXX
 SG_ EYE222_3_5_REQ_TARGET_RPM_CVT : 29|1@1+ (1,0) [0|1] "" Vector__XXX
 SG_ EYE222_3_6_STATE_BRAKE_ACC : 30|1@1+ (1,0) [0|1] "" Vector__XXX
 SG_ EYE222_3_7_COOPERATE_EYE_ISS : 31|1@1+ (1,0) [0|1] "" Vector__XXX
 SG_ EYE222_2_0_TARGET_RPM_CVT : 16|13@1+ (1,0) [0|8191] "rpm" Vector__XXX
 SG_ EYE222_1_0_MSG_COUNTER : 8|4@1+ (1,0) [0|15] "" Vector__XXX
 SG_ EYE222_1_4_MSA_CONT_STATUS_TCU : 12|1@1+ (1,0) [0|1] "" Vector__XXX
 SG_ EYE222_1_7_FAIL_EYESIGHT : 15|1@1+ (1,0) [0|1] "" Vector__XXX
 SG_ EYE222_0_0_CHECK_SUM : 0|8@1+ (1,0) [0|255] "" Vector__XXX

BO_ 545 EYE221: 8 ADAS
 SG_ EYE221_7_0_COMMANDSW_CC : 56|3@1+ (1,0) [0|7] ""  C_ECU,C_ECU_GW
 SG_ EYE221_7_3_MODE_CC : 59|1@1+ (1,0) [0|1] ""  C_ECU_GW
 SG_ EYE221_7_4_MSA_CNT_STS_EGI_HEV : 60|2@1+ (1,0) [0|2] ""  C_ECU_GW
 SG_ EYE221_7_6_EQUIP_MSA : 62|1@1+ (1,0) [0|1] ""  C_ECU_GW
 SG_ EYE221_7_7_INHIBIT_FUEL_CUT : 63|1@1+ (1,0) [0|1] ""  C_ECU_GW
 SG_ EYE221_5_0_TRQDWN_FORCE_LIMIT : 40|16@1+ (1.6,0) [0|408] "Nm"  C_ECU_GW
 SG_ EYE221_4_0_STATE_TRACKING : 32|1@1+ (1,0) [0|1] ""  C_ECU_GW
 SG_ EYE221_4_1_STATE_LSF : 33|1@1+ (1,0) [0|1] ""  C_ECU_GW
 SG_ EYE221_4_2_FORCED_CANCEL_ACC : 34|1@1+ (1,0) [0|1] ""  C_ECU_GW
 SG_ EYE221_4_3_BRAKE_TYPE : 35|1@1+ (1,0) [0|1] ""  C_ECU_GW
 SG_ EYE221_4_4_ACTIVE_BRAKE_ACC : 36|1@1+ (1,0) [0|1] ""  C_ECU_GW
 SG_ EYE221_4_5_REQ_FMW : 37|1@1+ (1,0) [0|1] ""  C_ECU_GW
 SG_ EYE221_4_6_FLG_BEFORE_RESERVE : 38|1@1+ (1,0) [0|1] ""  C_ECU_GW
 SG_ EYE221_4_7_REQ_TARGET_TORQUE : 39|1@1+ (1,0) [0|1] ""  C_ECU_GW
 SG_ EYE221_2_0_TGT_SPD_TRQ_FORCE : 16|16@1+ (0.1,-1000) [-1000|5553.5] "Nm"  C_ECU_GW
 SG_ EYE221_1_0_MSG_COUNTER : 8|4@1+ (1,0) [0|15] ""  C_ECU,C_ECU_GW
 SG_ EYE221_1_4_FLG_ADAPTIVE_CC : 12|1@1+ (1,0) [0|1] ""  C_ECU_GW
 SG_ EYE221_1_5_CANCEL_SW_INFO : 13|1@1+ (1,0) [0|1] ""  C_ECU_GW
 SG_ EYE221_1_6_FLG_EYESIGHT_VERSION : 14|1@1+ (1,0) [0|1] ""  C_ECU_GW
 SG_ EYE221_1_7_FAIL_EYESIGHT : 15|1@1+ (1,0) [0|1] ""  C_ECU_GW
 SG_ EYE221_0_0_CHECK_SUM : 0|8@1+ (1,0) [0|255] ""  C_ECU,C_ECU_GW

BO_ 1352 EYE548: 8 ADAS
 SG_ EYE548_7_0_NETWORK_STATUS : 7|64@0+ (1,0) [0|0] ""  C_ECU

BO_ 1746 LCT6D2: 8 LCT
 SG_ LCT6D2_5_0_HDMAP_RELEASE_SEASON : 40|4@1+ (1,0) [0|4] ""  C_ECU_GW
 SG_ LCT6D2_5_4_HDMAP_RELEASE_REV : 44|4@1+ (1,0) [1|14] ""  C_ECU_GW
 SG_ LCT6D2_4_0_HDMAP_RELEASE_YEAR : 32|8@1+ (1,2000) [2000|2099] "年"  C_ECU_GW
 SG_ LCT6D2_3_0_ISAMAP_RELEASE_SEASON : 24|4@1+ (1,0) [1|4] ""  C_ECU_GW
 SG_ LCT6D2_3_4_ISAMAP_RELEASE_REV : 28|4@1+ (1,0) [1|14] ""  C_ECU_GW
 SG_ LCT6D2_2_0_ISAMAP_RELEASE_YEAR : 16|8@1+ (1,2000) [0|99] "年"  C_ECU_GW
 SG_ LCT6D2_1_0_MSG_COUNTER : 8|4@1+ (1,0) [0|15] ""  C_ECU_GW
 SG_ LCT6D2_1_5_ADASMAP_FLAG : 13|1@1+ (1,0) [0|1] ""  C_ECU_GW
 SG_ LCT6D2_1_6_HDMAP_FLAG : 14|1@1+ (1,0) [0|1] ""  C_ECU_GW
 SG_ LCT6D2_1_7_GSRISA_FLAG : 15|1@1+ (1,0) [0|1] ""  C_ECU_GW
 SG_ LCT6D2_0_0_CHECK_SUM : 0|8@1+ (1,0) [0|255] ""  C_ECU_GW

BO_ 1369 LCT559: 8 LCT
 SG_ LCT559_0_0_NETWORK_STATUS : 0|64@1+ (1,0) [0|0] ""  C_ECU

BO_ 1375 FCRR55F: 8 ADAS_GW
 SG_ FCR55F_7_0_NETWORK_STATUS : 56|64@1+ (1,0) [0|0] ""  C_ECU

BO_ 1374 FCRL55E: 8 ADAS_GW
 SG_ FCR55E_7_0_NETWORK_STATUS : 56|64@1+ (1,0) [0|0] ""  C_ECU

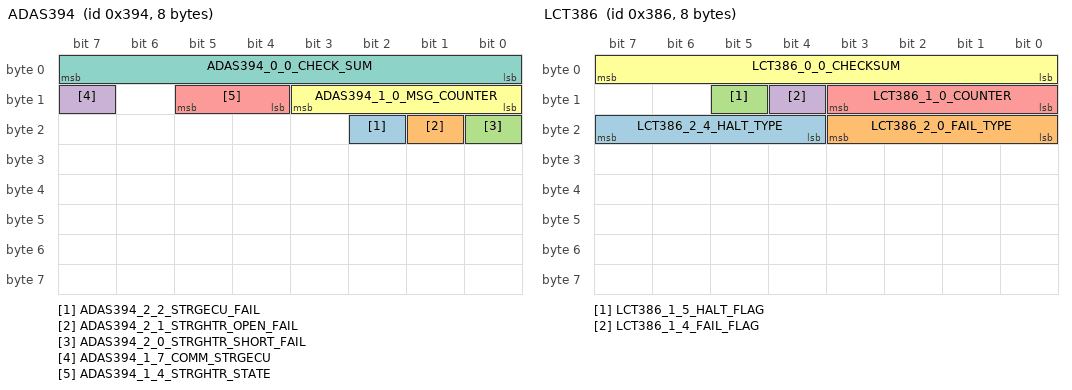
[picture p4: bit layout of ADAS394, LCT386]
BO_ 916 ADAS394: 8 ADAS
 SG_ ADAS394_2_2_STRGECU_FAIL : 18|1@1+ (1,0) [0|1] ""  C_ECU_GW
 SG_ ADAS394_2_1_STRGHTR_OPEN_FAIL : 17|1@1+ (1,0) [0|1] ""  C_ECU_GW
 SG_ ADAS394_2_0_STRGHTR_SHORT_FAIL : 16|1@1+ (1,0) [0|1] ""  C_ECU_GW
 SG_ ADAS394_1_7_COMM_STRGECU : 15|1@1+ (1,0) [0|1] ""  C_ECU_GW
 SG_ ADAS394_1_4_STRGHTR_STATE : 12|2@1+ (1,0) [0|3] ""  C_ECU_GW
 SG_ ADAS394_1_0_MSG_COUNTER : 8|4@1+ (1,0) [0|15] ""  C_ECU_GW
 SG_ ADAS394_0_0_CHECK_SUM : 0|8@1+ (1,0) [0|255] ""  C_ECU_GW

BO_ 911 LCT38F: 8 LCT

BO_ 910 LCT38E: 8 LCT

BO_ 909 LCT38D: 8 LCT

BO_ 908 LCT38C: 8 LCT

BO_ 905 LCT389: 8 LCT

BO_ 904 LCT388: 8 LCT

BO_ 903 LCT387: 8 LCT

BO_ 902 LCT386: 8 LCT
 SG_ LCT386_2_4_HALT_TYPE : 20|4@1+ (1,0) [0|0] ""  ADAS
 SG_ LCT386_2_0_FAIL_TYPE : 16|4@1+ (1,0) [0|0] ""  ADAS
 SG_ LCT386_1_5_HALT_FLAG : 13|1@1+ (1,0) [0|0] ""  ADAS
 SG_ LCT386_1_4_FAIL_FLAG : 12|1@1+ (1,0) [0|0] ""  ADAS
 SG_ LCT386_1_0_COUNTER : 8|4@1+ (1,0) [0|15] ""  ADAS
 SG_ LCT386_0_0_CHECKSUM : 0|8@1+ (1,0) [0|255] ""  ADAS

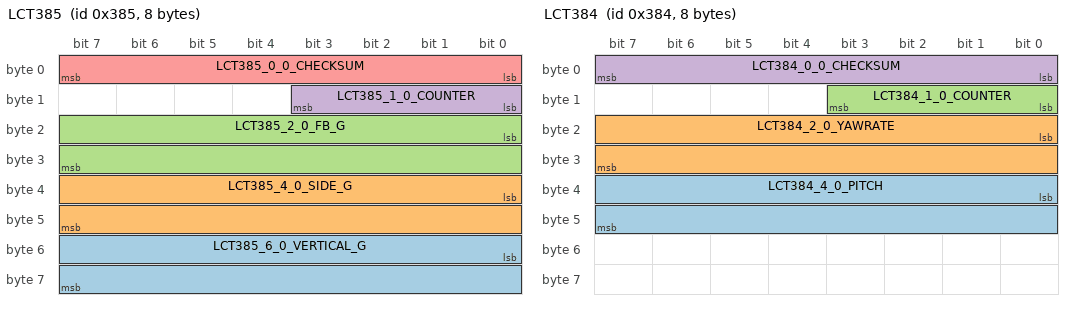
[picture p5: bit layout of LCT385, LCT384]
BO_ 901 LCT385: 8 LCT
 SG_ LCT385_6_0_VERTICAL_G : 48|16@1- (0.01,0) [0|0] "m/s^2"  ADAS
 SG_ LCT385_4_0_SIDE_G : 32|16@1- (0.01,0) [0|0] "m/s^2"  ADAS
 SG_ LCT385_2_0_FB_G : 16|16@1- (0.01,0) [0|0] "m/s^2"  ADAS
 SG_ LCT385_1_0_COUNTER : 8|4@1+ (1,0) [0|15] ""  ADAS
 SG_ LCT385_0_0_CHECKSUM : 0|8@1+ (1,0) [0|255] ""  ADAS

BO_ 900 LCT384: 8 LCT
 SG_ LCT384_4_0_PITCH : 32|16@1- (0.01,0) [0|0] "deg"  ADAS
 SG_ LCT384_2_0_YAWRATE : 16|16@1- (0.003,0) [0|0] "deg/s"  ADAS
 SG_ LCT384_1_0_COUNTER : 8|4@1+ (1,0) [0|15] ""  ADAS
 SG_ LCT384_0_0_CHECKSUM : 0|8@1+ (1,0) [0|255] ""  ADAS

BO_ 899 LCT383: 8 LCT
 SG_ LCT383_1_4_STOPSIGN : 12|1@1+ (1,0) [0|1] ""  ADAS
 SG_ LCT383_1_3_YIELDSIGN : 11|1@1+ (1,0) [0|1] ""  ADAS
 SG_ LCT383_1_2_NOENTRY : 10|1@1+ (1,0) [0|1] ""  ADAS
 SG_ LCT383_1_1_GIVEWAY : 9|1@1+ (1,0) [0|1] ""  ADAS
 SG_ LCT383_1_0_COUNTER : 8|4@1+ (1,0) [0|15] ""  ADAS
 SG_ LCT383_0_0_CHECKSUM : 0|8@1+ (1,0) [0|255] ""  ADAS

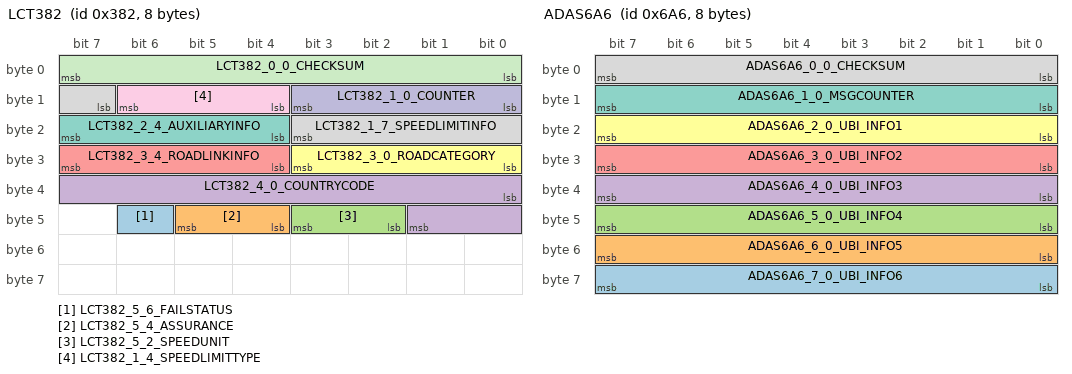
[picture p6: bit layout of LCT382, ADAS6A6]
BO_ 898 LCT382: 8 LCT
 SG_ LCT382_5_6_FAILSTATUS : 46|1@1+ (1,0) [0|1] ""  ADAS_GW,C_ECU_GW
 SG_ LCT382_5_4_ASSURANCE : 44|2@1+ (1,0) [0|3] ""  ADAS_GW,C_ECU_GW
 SG_ LCT382_5_2_SPEEDUNIT : 42|2@1+ (1,0) [0|3] ""  ADAS_GW,C_ECU_GW
 SG_ LCT382_4_0_COUNTRYCODE : 32|10@1+ (1,0) [0|1023] ""  ADAS_GW,C_ECU_GW
 SG_ LCT382_3_4_ROADLINKINFO : 28|4@1+ (1,0) [0|15] ""  ADAS_GW,C_ECU_GW
 SG_ LCT382_3_0_ROADCATEGORY : 24|4@1+ (1,0) [0|15] ""  ADAS_GW,C_ECU_GW
 SG_ LCT382_2_4_AUXILIARYINFO : 20|4@1+ (1,0) [0|15] ""  ADAS_GW,C_ECU_GW
 SG_ LCT382_1_7_SPEEDLIMITINFO : 15|5@1+ (1,0) [0|31] ""  ADAS_GW,C_ECU_GW
 SG_ LCT382_1_4_SPEEDLIMITTYPE : 12|3@1+ (1,0) [0|7] ""  ADAS_GW,C_ECU_GW
 SG_ LCT382_1_0_COUNTER : 8|4@1+ (1,0) [0|15] ""  ADAS_GW,C_ECU_GW
 SG_ LCT382_0_0_CHECKSUM : 0|8@1+ (1,0) [0|255] ""  ADAS_GW,C_ECU_GW

BO_ 2564481052 LCT18DAE01C: 8 LCT
 SG_ LCT18DAE01C_DIAG_DATA : 7|64@0+ (1,0) [0|1.844674407371E+19] ""  C_ECU_GW

BO_ 2564431072 DNT18DA1CE0: 8 C_ECU_GW
 SG_ DNT18DA1CE0_DIAG_DATA : 7|64@0+ (1,0) [0|1.844674407371E+19] ""  LCT

BO_ 1702 ADAS6A6: 8 ADAS
 SG_ ADAS6A6_7_0_UBI_INFO6 : 56|8@1+ (1,0) [0|255] ""  C_ECU
 SG_ ADAS6A6_6_0_UBI_INFO5 : 48|8@1+ (1,0) [0|255] ""  C_ECU
 SG_ ADAS6A6_5_0_UBI_INFO4 : 40|8@1+ (1,0) [0|255] ""  C_ECU
 SG_ ADAS6A6_4_0_UBI_INFO3 : 32|8@1+ (1,0) [0|255] ""  C_ECU
 SG_ ADAS6A6_3_0_UBI_INFO2 : 24|8@1+ (1,0) [0|255] ""  C_ECU
 SG_ ADAS6A6_2_0_UBI_INFO1 : 16|8@1+ (1,0) [0|255] ""  C_ECU
 SG_ ADAS6A6_1_0_MSGCOUNTER : 8|8@1+ (1,0) [0|255] ""  C_ECU
 SG_ ADAS6A6_0_0_CHECKSUM : 0|8@1+ (1,0) [0|255] ""  C_ECU

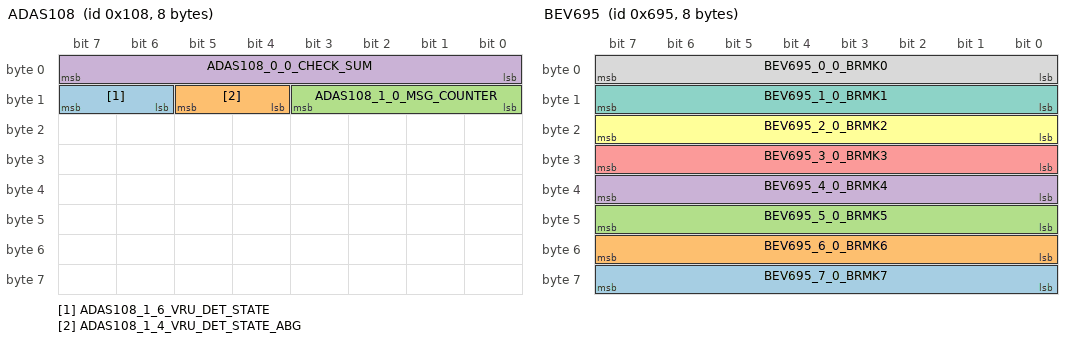
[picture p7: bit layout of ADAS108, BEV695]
BO_ 264 ADAS108: 8 ADAS
 SG_ ADAS108_1_6_VRU_DET_STATE : 14|2@1+ (1,0) [0|3] ""  ABG
 SG_ ADAS108_1_4_VRU_DET_STATE_ABG : 12|2@1+ (1,0) [0|3] "" Vector__XXX
 SG_ ADAS108_1_0_MSG_COUNTER : 8|4@1+ (1,0) [0|15] ""  ABG
 SG_ ADAS108_0_0_CHECK_SUM : 0|8@1+ (1,0) [0|255] ""  ABG

BO_ 2564481353 OBC18DAE149: 64 BEV_GW
 SG_ OBC18DAE149_DIAG_DATA_EXT7 : 455|64@0+ (1,0) [0|1.844674407371E+19] ""  C_ECU
 SG_ OBC18DAE149_DIAG_DATA_EXT6 : 391|64@0+ (1,0) [0|1.844674407371E+19] ""  C_ECU
 SG_ OBC18DAE149_DIAG_DATA_EXT5 : 327|64@0+ (1,0) [0|1.844674407371E+19] ""  C_ECU
 SG_ OBC18DAE149_DIAG_DATA_EXT4 : 263|64@0+ (1,0) [0|1.844674407371E+19] ""  C_ECU
 SG_ OBC18DAE149_DIAG_DATA_EXT3 : 199|64@0+ (1,0) [0|1.844674407371E+19] ""  C_ECU
 SG_ OBC18DAE149_DIAG_DATA_EXT2 : 135|64@0+ (1,0) [0|1.844674407371E+19] ""  C_ECU
 SG_ OBC18DAE149_DIAG_DATA_EXT1 : 71|64@0+ (1,0) [0|1.844674407371E+19] ""  C_ECU
 SG_ OBC18DAE149_DIAG_DATA : 7|64@0+ (1,0) [0|1.844674407371E+19] ""  C_ECU

BO_ 2564442593 CECU18DA49E1: 64 C_ECU
 SG_ CECU18DA49E1_DIAG_DATA_EXT7 : 455|64@0+ (1,0) [0|1.844674407371E+19] ""  BEV_GW
 SG_ CECU18DA49E1_DIAG_DATA_EXT6 : 391|64@0+ (1,0) [0|1.844674407371E+19] ""  BEV_GW
 SG_ CECU18DA49E1_DIAG_DATA_EXT5 : 327|64@0+ (1,0) [0|1.844674407371E+19] ""  BEV_GW
 SG_ CECU18DA49E1_DIAG_DATA_EXT4 : 263|64@0+ (1,0) [0|1.844674407371E+19] ""  BEV_GW
 SG_ CECU18DA49E1_DIAG_DATA_EXT3 : 199|64@0+ (1,0) [0|1.844674407371E+19] ""  BEV_GW
 SG_ CECU18DA49E1_DIAG_DATA_EXT2 : 135|64@0+ (1,0) [0|1.844674407371E+19] ""  BEV_GW
 SG_ CECU18DA49E1_DIAG_DATA_EXT1 : 71|64@0+ (1,0) [0|1.844674407371E+19] ""  BEV_GW
 SG_ CECU18DA49E1_DIAG_DATA : 7|64@0+ (1,0) [0|1.844674407371E+19] ""  BEV_GW

BO_ 1687 BEV697: 32 BEV
 SG_ BEV697_31_0_BRMK71 : 248|8@1+ (1,0) [0|255] "" Vector__XXX
 SG_ BEV697_30_0_BRMK70 : 240|8@1+ (1,0) [0|255] "" Vector__XXX
 SG_ BEV697_29_0_BRMK69 : 232|8@1+ (1,0) [0|255] "" Vector__XXX
 SG_ BEV697_28_0_BRMK68 : 224|8@1+ (1,0) [0|255] "" Vector__XXX
 SG_ BEV697_27_0_BRMK67 : 216|8@1+ (1,0) [0|255] "" Vector__XXX
 SG_ BEV697_26_0_BRMK66 : 208|8@1+ (1,0) [0|255] "" Vector__XXX
 SG_ BEV697_25_0_BRMK65 : 200|8@1+ (1,0) [0|255] "" Vector__XXX
 SG_ BEV697_24_0_BRMK64 : 192|8@1+ (1,0) [0|255] "" Vector__XXX
 SG_ BEV697_23_0_BRMK63 : 184|8@1+ (1,0) [0|255] "" Vector__XXX
 SG_ BEV697_22_0_BRMK62 : 176|8@1+ (1,0) [0|255] "" Vector__XXX
 SG_ BEV697_21_0_BRMK61 : 168|8@1+ (1,0) [0|255] "" Vector__XXX
 SG_ BEV697_20_0_BRMK60 : 160|8@1+ (1,0) [0|255] "" Vector__XXX
 SG_ BEV697_19_0_BRMK59 : 152|8@1+ (1,0) [0|255] "" Vector__XXX
 SG_ BEV697_18_0_BRMK58 : 144|8@1+ (1,0) [0|255] "" Vector__XXX
 SG_ BEV697_17_0_BRMK57 : 136|8@1+ (1,0) [0|255] "" Vector__XXX
 SG_ BEV697_16_0_BRMK56 : 128|8@1+ (1,0) [0|255] "" Vector__XXX
 SG_ BEV697_15_0_BRMK55 : 120|8@1+ (1,0) [0|255] "" Vector__XXX
 SG_ BEV697_14_0_BRMK54 : 112|8@1+ (1,0) [0|255] "" Vector__XXX
 SG_ BEV697_13_0_BRMK53 : 104|8@1+ (1,0) [0|255] "" Vector__XXX
 SG_ BEV697_12_0_BRMK52 : 96|8@1+ (1,0) [0|255] "" Vector__XXX
 SG_ BEV697_11_0_BRMK51 : 88|8@1+ (1,0) [0|255] "" Vector__XXX
 SG_ BEV697_10_0_BRMK50 : 80|8@1+ (1,0) [0|255] "" Vector__XXX
 SG_ BEV697_9_0_BRMK49 : 72|8@1+ (1,0) [0|255] "" Vector__XXX
 SG_ BEV697_8_0_BRMK48 : 64|8@1+ (1,0) [0|255] "" Vector__XXX
 SG_ BEV697_7_0_BRMK47 : 56|8@1+ (1,0) [0|255] "" Vector__XXX
 SG_ BEV697_6_0_BRMK46 : 48|8@1+ (1,0) [0|255] "" Vector__XXX
 SG_ BEV697_5_0_BRMK45 : 40|8@1+ (1,0) [0|255] "" Vector__XXX
 SG_ BEV697_4_0_BRMK44 : 32|8@1+ (1,0) [0|255] "" Vector__XXX
 SG_ BEV697_3_0_BRMK43 : 24|8@1+ (1,0) [0|255] "" Vector__XXX
 SG_ BEV697_2_0_BRMK42 : 16|8@1+ (1,0) [0|255] "" Vector__XXX
 SG_ BEV697_1_0_BRMK41 : 8|8@1+ (1,0) [0|255] "" Vector__XXX
 SG_ BEV697_0_0_BRMK40 : 0|8@1+ (1,0) [0|255] "" Vector__XXX

BO_ 1686 BEV696: 32 BEV
 SG_ BEV696_31_0_BRMK39 : 248|8@1+ (1,0) [0|255] "" Vector__XXX
 SG_ BEV696_30_0_BRMK38 : 240|8@1+ (1,0) [0|255] "" Vector__XXX
 SG_ BEV696_29_0_BRMK37 : 232|8@1+ (1,0) [0|255] "" Vector__XXX
 SG_ BEV696_28_0_BRMK36 : 224|8@1+ (1,0) [0|255] "" Vector__XXX
 SG_ BEV696_27_0_BRMK35 : 216|8@1+ (1,0) [0|255] "" Vector__XXX
 SG_ BEV696_26_0_BRMK34 : 208|8@1+ (1,0) [0|255] "" Vector__XXX
 SG_ BEV696_25_0_BRMK33 : 200|8@1+ (1,0) [0|255] "" Vector__XXX
 SG_ BEV696_24_0_BRMK32 : 192|8@1+ (1,0) [0|255] "" Vector__XXX
 SG_ BEV696_23_0_BRMK31 : 184|8@1+ (1,0) [0|255] "" Vector__XXX
 SG_ BEV696_22_0_BRMK30 : 176|8@1+ (1,0) [0|255] "" Vector__XXX
 SG_ BEV696_21_0_BRMK29 : 168|8@1+ (1,0) [0|255] "" Vector__XXX
 SG_ BEV696_20_0_BRMK28 : 160|8@1+ (1,0) [0|255] "" Vector__XXX
 SG_ BEV696_19_0_BRMK27 : 152|8@1+ (1,0) [0|255] "" Vector__XXX
 SG_ BEV696_18_0_BRMK26 : 144|8@1+ (1,0) [0|255] "" Vector__XXX
 SG_ BEV696_17_0_BRMK25 : 136|8@1+ (1,0) [0|255] "" Vector__XXX
 SG_ BEV696_16_0_BRMK24 : 128|8@1+ (1,0) [0|255] "" Vector__XXX
 SG_ BEV696_15_0_BRMK23 : 120|8@1+ (1,0) [0|255] "" Vector__XXX
 SG_ BEV696_14_0_BRMK22 : 112|8@1+ (1,0) [0|255] "" Vector__XXX
 SG_ BEV696_13_0_BRMK21 : 104|8@1+ (1,0) [0|255] "" Vector__XXX
 SG_ BEV696_12_0_BRMK20 : 96|8@1+ (1,0) [0|255] "" Vector__XXX
 SG_ BEV696_11_0_BRMK19 : 88|8@1+ (1,0) [0|255] "" Vector__XXX
 SG_ BEV696_10_0_BRMK18 : 80|8@1+ (1,0) [0|255] "" Vector__XXX
 SG_ BEV696_9_0_BRMK17 : 72|8@1+ (1,0) [0|255] "" Vector__XXX
 SG_ BEV696_8_0_BRMK16 : 64|8@1+ (1,0) [0|255] "" Vector__XXX
 SG_ BEV696_7_0_BRMK15 : 56|8@1+ (1,0) [0|255] "" Vector__XXX
 SG_ BEV696_6_0_BRMK14 : 48|8@1+ (1,0) [0|255] "" Vector__XXX
 SG_ BEV696_5_0_BRMK13 : 40|8@1+ (1,0) [0|255] "" Vector__XXX
 SG_ BEV696_4_0_BRMK12 : 32|8@1+ (1,0) [0|255] "" Vector__XXX
 SG_ BEV696_3_0_BRMK11 : 24|8@1+ (1,0) [0|255] "" Vector__XXX
 SG_ BEV696_2_0_BRMK10 : 16|8@1+ (1,0) [0|255] "" Vector__XXX
 SG_ BEV696_1_0_BRMK9 : 8|8@1+ (1,0) [0|255] "" Vector__XXX
 SG_ BEV696_0_0_BRMK8 : 0|8@1+ (1,0) [0|255] "" Vector__XXX

BO_ 1685 BEV695: 8 BEV
 SG_ BEV695_7_0_BRMK7 : 56|8@1+ (1,0) [0|255] ""  C_ECU_GW
 SG_ BEV695_6_0_BRMK6 : 48|8@1+ (1,0) [0|255] ""  C_ECU_GW
 SG_ BEV695_5_0_BRMK5 : 40|8@1+ (1,0) [0|255] ""  C_ECU_GW
 SG_ BEV695_4_0_BRMK4 : 32|8@1+ (1,0) [0|255] ""  C_ECU_GW
 SG_ BEV695_3_0_BRMK3 : 24|8@1+ (1,0) [0|255] ""  C_ECU_GW
 SG_ BEV695_2_0_BRMK2 : 16|8@1+ (1,0) [0|255] ""  C_ECU_GW
 SG_ BEV695_1_0_BRMK1 : 8|8@1+ (1,0) [0|255] ""  C_ECU_GW
 SG_ BEV695_0_0_BRMK0 : 0|8@1+ (1,0) [0|255] ""  C_ECU_GW

BO_ 1304 BEV518: 8 BEV
 SG_ BEV518_1_4_ActiveWakeUpBit : 12|1@1+ (1,0) [0|1] ""  BST,VDC,C_ECU
 SG_ BEV518_0_0_SourceNodeID : 0|8@1+ (1,0) [0|255] ""  BST,VDC,C_ECU

BO_ 1541 BEV605: 32 BEV
 SG_ BEV605_3_0_IGBHLDRQ : 24|1@1+ (1,0) [0|1] ""  C_ECU
 SG_ BEV605_3_2_ILK : 26|1@1+ (1,0) [0|1] ""  C_ECU
 SG_ BEV605_3_3_HVSYSNG : 27|1@1+ (1,0) [0|1] ""  C_ECU
 SG_ BEV605_2_0_E2E_COUNTER : 16|8@1+ (1,0) [0|255] ""  C_ECU
 SG_ BEV605_0_0_E2E_CRC : 0|16@1+ (1,0) [0|65535] ""  C_ECU

BO_ 1540 BEV604: 32 BEV
 SG_ BEV604_2_0_E2E_COUNTER : 16|8@1+ (1,0) [0|255] "" Vector__XXX
 SG_ BEV604_0_0_E2E_CRC : 0|16@1+ (1,0) [0|65535] "" Vector__XXX

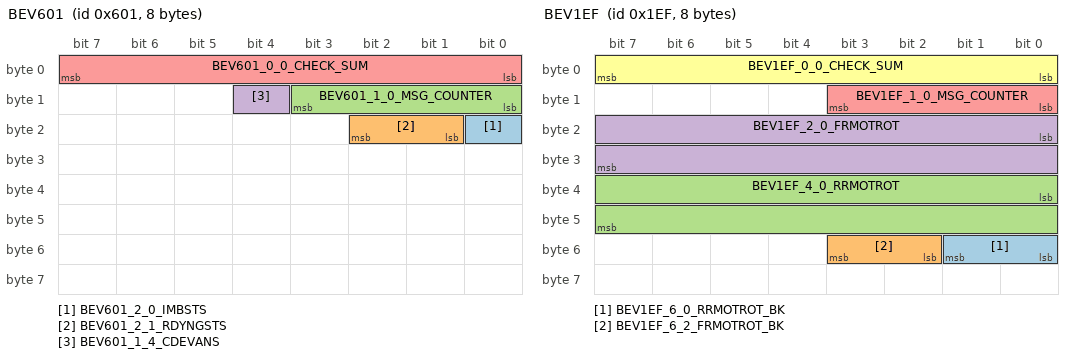
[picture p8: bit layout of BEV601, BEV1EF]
BO_ 1537 BEV601: 8 BEV
 SG_ BEV601_2_0_IMBSTS : 16|1@1+ (1,0) [0|1] ""  C_ECU_GW
 SG_ BEV601_2_1_RDYNGSTS : 17|2@1+ (1,0) [0|3] ""  C_ECU,C_ECU_GW
 SG_ BEV601_1_0_MSG_COUNTER : 8|4@1+ (1,0) [0|15] ""  ABG,C_ECU,C_ECU_GW
 SG_ BEV601_1_4_CDEVANS : 12|1@1+ (1,0) [0|1] ""  ABG,C_ECU_GW
 SG_ BEV601_0_0_CHECK_SUM : 0|8@1+ (1,0) [0|255] ""  ABG,C_ECU,C_ECU_GW

BO_ 543 BEV21F: 32 BEV
 SG_ BEV21F_2_0_E2E_COUNTER : 16|8@1+ (1,0) [0|255] "" Vector__XXX
 SG_ BEV21F_0_0_E2E_CRC : 0|16@1+ (1,0) [0|65535] "" Vector__XXX

BO_ 495 BEV1EF: 8 C_ECU_GW
 SG_ BEV1EF_6_0_RRMOTROT_BK : 48|2@1+ (1,0) [0|3] ""  ABG
 SG_ BEV1EF_6_2_FRMOTROT_BK : 50|2@1+ (1,0) [0|3] ""  ABG
 SG_ BEV1EF_4_0_RRMOTROT : 32|16@1- (1,0) [-32768|32767] "rpm"  ABG
 SG_ BEV1EF_2_0_FRMOTROT : 16|16@1- (1,0) [-32768|32767] "rpm"  ABG
 SG_ BEV1EF_1_0_MSG_COUNTER : 8|4@1+ (1,0) [0|15] ""  ABG
 SG_ BEV1EF_0_0_CHECK_SUM : 0|8@1+ (1,0) [0|255] ""  ABG

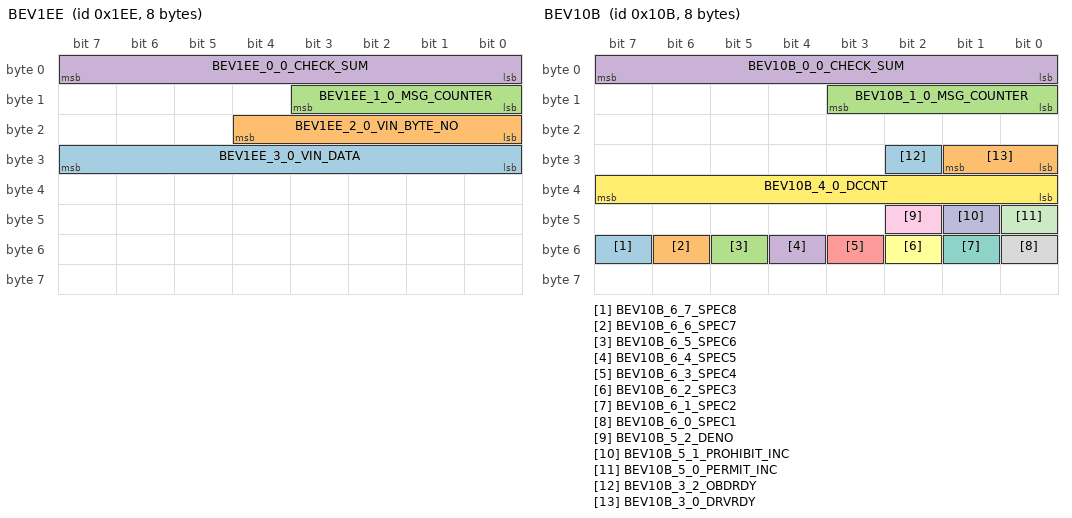
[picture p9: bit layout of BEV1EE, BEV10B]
BO_ 494 BEV1EE: 8 C_ECU_GW
 SG_ BEV1EE_3_0_VIN_DATA : 24|8@1+ (1,0) [0|255] "" Vector__XXX
 SG_ BEV1EE_2_0_VIN_BYTE_NO : 16|5@1+ (1,0) [0|17] "" Vector__XXX
 SG_ BEV1EE_1_0_MSG_COUNTER : 8|4@1+ (1,0) [0|15] "" Vector__XXX
 SG_ BEV1EE_0_0_CHECK_SUM : 0|8@1+ (1,0) [0|255] "" Vector__XXX

BO_ 267 BEV10B: 8 C_ECU_GW
 SG_ BEV10B_6_7_SPEC8 : 55|1@1+ (1,0) [0|1] "" Vector__XXX
 SG_ BEV10B_6_6_SPEC7 : 54|1@1+ (1,0) [0|1] "" Vector__XXX
 SG_ BEV10B_6_5_SPEC6 : 53|1@1+ (1,0) [0|1] "" Vector__XXX
 SG_ BEV10B_6_4_SPEC5 : 52|1@1+ (1,0) [0|1] "" Vector__XXX
 SG_ BEV10B_6_3_SPEC4 : 51|1@1+ (1,0) [0|1] "" Vector__XXX
 SG_ BEV10B_6_2_SPEC3 : 50|1@1+ (1,0) [0|1] "" Vector__XXX
 SG_ BEV10B_6_1_SPEC2 : 49|1@1+ (1,0) [0|1] "" Vector__XXX
 SG_ BEV10B_6_0_SPEC1 : 48|1@1+ (1,0) [0|1] "" Vector__XXX
 SG_ BEV10B_5_2_DENO : 42|1@1+ (1,0) [0|1] "" Vector__XXX
 SG_ BEV10B_5_1_PROHIBIT_INC : 41|1@1+ (1,0) [0|1] "" Vector__XXX
 SG_ BEV10B_5_0_PERMIT_INC : 40|1@1+ (1,0) [0|1] "" Vector__XXX
 SG_ BEV10B_4_0_DCCNT : 32|8@1+ (1,0) [0|255] ""  BST,VDC
 SG_ BEV10B_3_2_OBDRDY : 26|1@1+ (1,0) [0|1] "" Vector__XXX
 SG_ BEV10B_3_0_DRVRDY : 24|2@1+ (1,0) [0|3] "" Vector__XXX
 SG_ BEV10B_1_0_MSG_COUNTER : 8|4@1+ (1,0) [0|15] ""  BST,VDC
 SG_ BEV10B_0_0_CHECK_SUM : 0|8@1+ (1,0) [0|255] ""  BST,VDC

BO_ 117 BEV075: 8 C_ECU_GW
 SG_ BEV075_1_0_MSG_COUNTER : 8|4@1+ (1,0) [0|15] "" Vector__XXX
 SG_ BEV075_0_0_CHECK_SUM : 0|8@1+ (1,0) [0|255] "" Vector__XXX

BO_ 116 BEV074: 8 C_ECU_GW
 SG_ BEV074_7_0_LVPWRDWN : 56|6@1+ (1,0) [0|3] ""  ADAS_GW
 SG_ BEV074_7_6_CHRCONSTA : 62|1@1+ (1,0) [0|1] ""  ADAS_GW
 SG_ BEV074_7_7_VEHICLE_IGN : 63|1@1+ (1,0) [0|1] ""  ADAS_GW,ABG,VDC
 SG_ BEV074_6_0_EV_CAU : 48|2@1+ (1,0) [0|3] ""  ADAS_GW
 SG_ BEV074_6_2_BEV_OBD_CAU : 50|3@1+ (1,0) [0|7] ""  ADAS_GW
 SG_ BEV074_6_5_SIDRIVE_DISP : 53|3@1+ (1,0) [0|7] ""  ADAS_GW
 SG_ BEV074_5_0_ACCHG_STATE : 40|1@1+ (1,0) [0|1] ""  ADAS_GW
 SG_ BEV074_5_1_DCCHG_STATE : 41|1@1+ (1,0) [0|1] ""  ADAS_GW
 SG_ BEV074_5_2_RANGE_DG : 42|1@1+ (1,0) [0|1] ""  ADAS_GW,LCT,ABG
 SG_ BEV074_5_3_ACCP_DG : 43|1@1+ (1,0) [0|1] ""  ADAS_GW,ABG
 SG_ BEV074_5_4_REZ_SPD_BK : 44|2@1+ (1,0) [0|3] ""  ADAS_GW
 SG_ BEV074_5_6_OBDRDY : 46|1@1+ (1,0) [0|1] ""  ADAS_GW
 SG_ BEV074_5_7_FHVB : 47|1@1+ (1,0) [0|1] ""  ADAS_GW
 SG_ BEV074_3_0_RANGE_POS : 24|3@1+ (1,0) [0|7] ""  IAVAS,ADAS_GW,LCT,ABG,IPMS
 SG_ BEV074_3_3_DRVRDY : 27|2@1+ (1,0) [0|3] ""  ADAS_GW,ABG,EPS
 SG_ BEV074_3_5_HVSYSTS : 29|2@1+ (1,0) [0|3] ""  ADAS_GW
 SG_ BEV074_3_7_REZ_SPD_GL : 31|9@1- (1,0) [-256|255] "km/h"  ADAS_GW
 SG_ BEV074_2_0_ACCP_USR : 16|8@1+ (0.5,0) [0|127.5] "%"  ADAS_GW,ABG
 SG_ BEV074_1_0_MSG_COUNTER : 8|4@1+ (1,0) [0|15] ""  IAVAS,ADAS_GW,LCT,ABG,EPS
 SG_ BEV074_1_4_RANGE_DG2 : 12|1@1+ (1,0) [0|1] ""  ADAS_GW
 SG_ BEV074_1_5_REZ_SPD_BK : 13|3@1+ (1,0) [0|5] ""  ADAS_GW
 SG_ BEV074_0_0_CHECK_SUM : 0|8@1+ (1,0) [0|255] ""  IAVAS,ADAS_GW,LCT,ABG,EPS

BO_ 2041 ABG7F9: 8 ABG
 SG_ ABG7F9_7_0_DATA : 7|64@0+ (1,0) [0|1.844674407371E+19] ""  C_ECU_GW

BO_ 2033 ABG7F1: 8 C_ECU_GW
 SG_ ABG7F1_7_0_DATA : 7|64@0+ (1,0) [0|1.844674407371E+19] ""  ABG

BO_ 1803 VDC70B: 8 VDC
 SG_ VDC70B_7_0_DATA : 7|64@0+ (1,0) [0|1.844674407371E+19] ""  C_ECU_GW

BO_ 1802 VDC70A: 8 VDC
 SG_ VDC70A_7_0_DATA : 7|64@0+ (1,0) [0|1.844674407371E+19] ""  C_ECU_GW

BO_ 2564481410 FCRL18DAE182: 64 ADAS_GW
 SG_ FCRL18DAE182_DIAG_DATA_EXT7 : 455|64@0+ (1,0) [0|1.844674407371E+19] ""  C_ECU
 SG_ FCRL18DAE182_DIAG_DATA_EXT6 : 391|64@0+ (1,0) [0|1.844674407371E+19] ""  C_ECU
 SG_ FCRL18DAE182_DIAG_DATA_EXT5 : 327|64@0+ (1,0) [0|1.844674407371E+19] ""  C_ECU
 SG_ FCRL18DAE182_DIAG_DATA_EXT4 : 263|64@0+ (1,0) [0|1.844674407371E+19] ""  C_ECU
 SG_ FCRL18DAE182_DIAG_DATA_EXT3 : 199|64@0+ (1,0) [0|1.844674407371E+19] ""  C_ECU
 SG_ FCRL18DAE182_DIAG_DATA_EXT2 : 135|64@0+ (1,0) [0|1.844674407371E+19] ""  C_ECU
 SG_ FCRL18DAE182_DIAG_DATA_EXT1 : 71|64@0+ (1,0) [0|1.844674407371E+19] ""  C_ECU
 SG_ FCRL18DAE182_DIAG_DATA : 7|64@0+ (1,0) [0|1.844674407371E+19] ""  C_ECU

BO_ 2564457185 CECU18DA82E1: 64 C_ECU
 SG_ CECU18DA82E1_DIAG_DATA_EXT7 : 455|64@0+ (1,0) [0|1.844674407371E+19] ""  ADAS_GW
 SG_ CECU18DA82E1_DIAG_DATA_EXT6 : 391|64@0+ (1,0) [0|1.844674407371E+19] ""  ADAS_GW
 SG_ CECU18DA82E1_DIAG_DATA_EXT5 : 327|64@0+ (1,0) [0|1.844674407371E+19] ""  ADAS_GW
 SG_ CECU18DA82E1_DIAG_DATA_EXT4 : 263|64@0+ (1,0) [0|1.844674407371E+19] ""  ADAS_GW
 SG_ CECU18DA82E1_DIAG_DATA_EXT3 : 199|64@0+ (1,0) [0|1.844674407371E+19] ""  ADAS_GW
 SG_ CECU18DA82E1_DIAG_DATA_EXT2 : 135|64@0+ (1,0) [0|1.844674407371E+19] ""  ADAS_GW
 SG_ CECU18DA82E1_DIAG_DATA_EXT1 : 71|64@0+ (1,0) [0|1.844674407371E+19] ""  ADAS_GW
 SG_ CECU18DA82E1_DIAG_DATA : 7|64@0+ (1,0) [0|1.844674407371E+19] ""  ADAS_GW

BO_ 2564481411 FCRR18DAE183: 64 ADAS_GW
 SG_ FCRR18DAE183_DIAG_DATA_EXT7 : 455|64@0+ (1,0) [0|1.844674407371E+19] ""  C_ECU
 SG_ FCRR18DAE183_DIAG_DATA_EXT6 : 391|64@0+ (1,0) [0|1.844674407371E+19] ""  C_ECU
 SG_ FCRR18DAE183_DIAG_DATA_EXT5 : 327|64@0+ (1,0) [0|1.844674407371E+19] ""  C_ECU
 SG_ FCRR18DAE183_DIAG_DATA_EXT4 : 263|64@0+ (1,0) [0|1.844674407371E+19] ""  C_ECU
 SG_ FCRR18DAE183_DIAG_DATA_EXT3 : 199|64@0+ (1,0) [0|1.844674407371E+19] ""  C_ECU
 SG_ FCRR18DAE183_DIAG_DATA_EXT2 : 135|64@0+ (1,0) [0|1.844674407371E+19] ""  C_ECU
 SG_ FCRR18DAE183_DIAG_DATA_EXT1 : 71|64@0+ (1,0) [0|1.844674407371E+19] ""  C_ECU
 SG_ FCRR18DAE183_DIAG_DATA : 7|64@0+ (1,0) [0|1.844674407371E+19] ""  C_ECU

BO_ 2564457441 CECU18DA83E1: 64 C_ECU
 SG_ CECU18DA83E1_DIAG_DATA_EXT7 : 455|64@0+ (1,0) [0|1.844674407371E+19] ""  ADAS_GW
 SG_ CECU18DA83E1_DIAG_DATA_EXT6 : 391|64@0+ (1,0) [0|1.844674407371E+19] ""  ADAS_GW
 SG_ CECU18DA83E1_DIAG_DATA_EXT5 : 327|64@0+ (1,0) [0|1.844674407371E+19] ""  ADAS_GW
 SG_ CECU18DA83E1_DIAG_DATA_EXT4 : 263|64@0+ (1,0) [0|1.844674407371E+19] ""  ADAS_GW
 SG_ CECU18DA83E1_DIAG_DATA_EXT3 : 199|64@0+ (1,0) [0|1.844674407371E+19] ""  ADAS_GW
 SG_ CECU18DA83E1_DIAG_DATA_EXT2 : 135|64@0+ (1,0) [0|1.844674407371E+19] ""  ADAS_GW
 SG_ CECU18DA83E1_DIAG_DATA_EXT1 : 71|64@0+ (1,0) [0|1.844674407371E+19] ""  ADAS_GW
 SG_ CECU18DA83E1_DIAG_DATA : 7|64@0+ (1,0) [0|1.844674407371E+19] ""  ADAS_GW

BO_ 2564481286 PBW18DAE106: 64 BEV_GW
 SG_ PBW18DAE106_DIAG_DATA_EXT7 : 455|64@0+ (1,0) [0|1.844674407371E+19] ""  C_ECU
 SG_ PBW18DAE106_DIAG_DATA_EXT6 : 391|64@0+ (1,0) [0|1.844674407371E+19] ""  C_ECU
 SG_ PBW18DAE106_DIAG_DATA_EXT5 : 327|64@0+ (1,0) [0|1.844674407371E+19] ""  C_ECU
 SG_ PBW18DAE106_DIAG_DATA_EXT4 : 263|64@0+ (1,0) [0|1.844674407371E+19] ""  C_ECU
 SG_ PBW18DAE106_DIAG_DATA_EXT3 : 199|64@0+ (1,0) [0|1.844674407371E+19] ""  C_ECU
 SG_ PBW18DAE106_DIAG_DATA_EXT2 : 135|64@0+ (1,0) [0|1.844674407371E+19] ""  C_ECU
 SG_ PBW18DAE106_DIAG_DATA_EXT1 : 71|64@0+ (1,0) [0|1.844674407371E+19] ""  C_ECU
 SG_ PBW18DAE106_DIAG_DATA : 7|64@0+ (1,0) [0|1.844674407371E+19] ""  C_ECU

BO_ 2564425441 CECU18DA06E1: 64 C_ECU
 SG_ CECU18DA06E1_DIAG_DATA_EXT7 : 455|64@0+ (1,0) [0|1.844674407371E+19] ""  BEV_GW
 SG_ CECU18DA06E1_DIAG_DATA_EXT6 : 391|64@0+ (1,0) [0|1.844674407371E+19] ""  BEV_GW
 SG_ CECU18DA06E1_DIAG_DATA_EXT5 : 327|64@0+ (1,0) [0|1.844674407371E+19] ""  BEV_GW
 SG_ CECU18DA06E1_DIAG_DATA_EXT4 : 263|64@0+ (1,0) [0|1.844674407371E+19] ""  BEV_GW
 SG_ CECU18DA06E1_DIAG_DATA_EXT3 : 199|64@0+ (1,0) [0|1.844674407371E+19] ""  BEV_GW
 SG_ CECU18DA06E1_DIAG_DATA_EXT2 : 135|64@0+ (1,0) [0|1.844674407371E+19] ""  BEV_GW
 SG_ CECU18DA06E1_DIAG_DATA_EXT1 : 71|64@0+ (1,0) [0|1.844674407371E+19] ""  BEV_GW
 SG_ CECU18DA06E1_DIAG_DATA : 7|64@0+ (1,0) [0|1.844674407371E+19] ""  BEV_GW

BO_ 2564481285 SFT18DAE105: 64 BEV_GW
 SG_ SFT18DAE105_DIAG_DATA_EXT7 : 455|64@0+ (1,0) [0|1.844674407371E+19] ""  C_ECU
 SG_ SFT18DAE105_DIAG_DATA_EXT6 : 391|64@0+ (1,0) [0|1.844674407371E+19] ""  C_ECU
 SG_ SFT18DAE105_DIAG_DATA_EXT5 : 327|64@0+ (1,0) [0|1.844674407371E+19] ""  C_ECU
 SG_ SFT18DAE105_DIAG_DATA_EXT4 : 263|64@0+ (1,0) [0|1.844674407371E+19] ""  C_ECU
 SG_ SFT18DAE105_DIAG_DATA_EXT3 : 199|64@0+ (1,0) [0|1.844674407371E+19] ""  C_ECU
 SG_ SFT18DAE105_DIAG_DATA_EXT2 : 135|64@0+ (1,0) [0|1.844674407371E+19] ""  C_ECU
 SG_ SFT18DAE105_DIAG_DATA_EXT1 : 71|64@0+ (1,0) [0|1.844674407371E+19] ""  C_ECU
 SG_ SFT18DAE105_DIAG_DATA : 7|64@0+ (1,0) [0|1.844674407371E+19] ""  C_ECU

BO_ 2564425185 CECU18DA05E1: 64 C_ECU
 SG_ CECU18DA05E1_DIAG_DATA_EXT7 : 455|64@0+ (1,0) [0|1.844674407371E+19] ""  BEV_GW
 SG_ CECU18DA05E1_DIAG_DATA_EXT6 : 391|64@0+ (1,0) [0|1.844674407371E+19] ""  BEV_GW
 SG_ CECU18DA05E1_DIAG_DATA_EXT5 : 327|64@0+ (1,0) [0|1.844674407371E+19] ""  BEV_GW
 SG_ CECU18DA05E1_DIAG_DATA_EXT4 : 263|64@0+ (1,0) [0|1.844674407371E+19] ""  BEV_GW
 SG_ CECU18DA05E1_DIAG_DATA_EXT3 : 199|64@0+ (1,0) [0|1.844674407371E+19] ""  BEV_GW
 SG_ CECU18DA05E1_DIAG_DATA_EXT2 : 135|64@0+ (1,0) [0|1.844674407371E+19] ""  BEV_GW
 SG_ CECU18DA05E1_DIAG_DATA_EXT1 : 71|64@0+ (1,0) [0|1.844674407371E+19] ""  BEV_GW
 SG_ CECU18DA05E1_DIAG_DATA : 7|64@0+ (1,0) [0|1.844674407371E+19] ""  BEV_GW

BO_ 2564481372 MGR18DAE15C: 64 BEV_GW
 SG_ MGR18DAE15C_DIAG_DATA_EXT7 : 455|64@0+ (1,0) [0|1.844674407371E+19] ""  C_ECU
 SG_ MGR18DAE15C_DIAG_DATA_EXT6 : 391|64@0+ (1,0) [0|1.844674407371E+19] ""  C_ECU
 SG_ MGR18DAE15C_DIAG_DATA_EXT5 : 327|64@0+ (1,0) [0|1.844674407371E+19] ""  C_ECU
 SG_ MGR18DAE15C_DIAG_DATA_EXT4 : 263|64@0+ (1,0) [0|1.844674407371E+19] ""  C_ECU
 SG_ MGR18DAE15C_DIAG_DATA_EXT3 : 199|64@0+ (1,0) [0|1.844674407371E+19] ""  C_ECU
 SG_ MGR18DAE15C_DIAG_DATA_EXT2 : 135|64@0+ (1,0) [0|1.844674407371E+19] ""  C_ECU
 SG_ MGR18DAE15C_DIAG_DATA_EXT1 : 71|64@0+ (1,0) [0|1.844674407371E+19] ""  C_ECU
 SG_ MGR18DAE15C_DIAG_DATA : 7|64@0+ (1,0) [0|1.844674407371E+19] ""  C_ECU

BO_ 2564447457 CECU18DA5CE1: 64 C_ECU
 SG_ CECU18DA5CE1_DIAG_DATA_EXT7 : 455|64@0+ (1,0) [0|1.844674407371E+19] ""  BEV_GW
 SG_ CECU18DA5CE1_DIAG_DATA_EXT6 : 391|64@0+ (1,0) [0|1.844674407371E+19] ""  BEV_GW
 SG_ CECU18DA5CE1_DIAG_DATA_EXT5 : 327|64@0+ (1,0) [0|1.844674407371E+19] ""  BEV_GW
 SG_ CECU18DA5CE1_DIAG_DATA_EXT4 : 263|64@0+ (1,0) [0|1.844674407371E+19] ""  BEV_GW
 SG_ CECU18DA5CE1_DIAG_DATA_EXT3 : 199|64@0+ (1,0) [0|1.844674407371E+19] ""  BEV_GW
 SG_ CECU18DA5CE1_DIAG_DATA_EXT2 : 135|64@0+ (1,0) [0|1.844674407371E+19] ""  BEV_GW
 SG_ CECU18DA5CE1_DIAG_DATA_EXT1 : 71|64@0+ (1,0) [0|1.844674407371E+19] ""  BEV_GW
 SG_ CECU18DA5CE1_DIAG_DATA : 7|64@0+ (1,0) [0|1.844674407371E+19] ""  BEV_GW

BO_ 2564481371 MGF18DAE15B: 64 BEV_GW
 SG_ MGF18DAE15B_DIAG_DATA_EXT7 : 455|64@0+ (1,0) [0|1.844674407371E+19] ""  C_ECU
 SG_ MGF18DAE15B_DIAG_DATA_EXT6 : 391|64@0+ (1,0) [0|1.844674407371E+19] ""  C_ECU
 SG_ MGF18DAE15B_DIAG_DATA_EXT5 : 327|64@0+ (1,0) [0|1.844674407371E+19] ""  C_ECU
 SG_ MGF18DAE15B_DIAG_DATA_EXT4 : 263|64@0+ (1,0) [0|1.844674407371E+19] ""  C_ECU
 SG_ MGF18DAE15B_DIAG_DATA_EXT3 : 199|64@0+ (1,0) [0|1.844674407371E+19] ""  C_ECU
 SG_ MGF18DAE15B_DIAG_DATA_EXT2 : 135|64@0+ (1,0) [0|1.844674407371E+19] ""  C_ECU
 SG_ MGF18DAE15B_DIAG_DATA_EXT1 : 71|64@0+ (1,0) [0|1.844674407371E+19] ""  C_ECU
 SG_ MGF18DAE15B_DIAG_DATA : 7|64@0+ (1,0) [0|1.844674407371E+19] ""  C_ECU

BO_ 2564447201 CECU18DA5BE1: 64 C_ECU
 SG_ CECU18DA5BE1_DIAG_DATA_EXT7 : 455|64@0+ (1,0) [0|1.844674407371E+19] ""  BEV_GW
 SG_ CECU18DA5BE1_DIAG_DATA_EXT6 : 391|64@0+ (1,0) [0|1.844674407371E+19] ""  BEV_GW
 SG_ CECU18DA5BE1_DIAG_DATA_EXT5 : 327|64@0+ (1,0) [0|1.844674407371E+19] ""  BEV_GW
 SG_ CECU18DA5BE1_DIAG_DATA_EXT4 : 263|64@0+ (1,0) [0|1.844674407371E+19] ""  BEV_GW
 SG_ CECU18DA5BE1_DIAG_DATA_EXT3 : 199|64@0+ (1,0) [0|1.844674407371E+19] ""  BEV_GW
 SG_ CECU18DA5BE1_DIAG_DATA_EXT2 : 135|64@0+ (1,0) [0|1.844674407371E+19] ""  BEV_GW
 SG_ CECU18DA5BE1_DIAG_DATA_EXT1 : 71|64@0+ (1,0) [0|1.844674407371E+19] ""  BEV_GW
 SG_ CECU18DA5BE1_DIAG_DATA : 7|64@0+ (1,0) [0|1.844674407371E+19] ""  BEV_GW

BO_ 2564481476 BMU18DAE1C4: 64 BEV_GW
 SG_ BMU18DAE1C4_DIAG_DATA_EXT7 : 455|64@0+ (1,0) [0|1.844674407371E+19] ""  C_ECU
 SG_ BMU18DAE1C4_DIAG_DATA_EXT6 : 391|64@0+ (1,0) [0|1.844674407371E+19] ""  C_ECU
 SG_ BMU18DAE1C4_DIAG_DATA_EXT5 : 327|64@0+ (1,0) [0|1.844674407371E+19] ""  C_ECU
 SG_ BMU18DAE1C4_DIAG_DATA_EXT4 : 263|64@0+ (1,0) [0|1.844674407371E+19] ""  C_ECU
 SG_ BMU18DAE1C4_DIAG_DATA_EXT3 : 199|64@0+ (1,0) [0|1.844674407371E+19] ""  C_ECU
 SG_ BMU18DAE1C4_DIAG_DATA_EXT2 : 135|64@0+ (1,0) [0|1.844674407371E+19] ""  C_ECU
 SG_ BMU18DAE1C4_DIAG_DATA_EXT1 : 71|64@0+ (1,0) [0|1.844674407371E+19] ""  C_ECU
 SG_ BMU18DAE1C4_DIAG_DATA : 7|64@0+ (1,0) [0|1.844674407371E+19] ""  C_ECU

BO_ 2564474081 CECU18DAC4E1: 64 C_ECU
 SG_ CECU18DAC4E1_DIAG_DATA_EXT7 : 455|64@0+ (1,0) [0|1.844674407371E+19] ""  BEV_GW
 SG_ CECU18DAC4E1_DIAG_DATA_EXT6 : 391|64@0+ (1,0) [0|1.844674407371E+19] ""  BEV_GW
 SG_ CECU18DAC4E1_DIAG_DATA_EXT5 : 327|64@0+ (1,0) [0|1.844674407371E+19] ""  BEV_GW
 SG_ CECU18DAC4E1_DIAG_DATA_EXT4 : 263|64@0+ (1,0) [0|1.844674407371E+19] ""  BEV_GW
 SG_ CECU18DAC4E1_DIAG_DATA_EXT3 : 199|64@0+ (1,0) [0|1.844674407371E+19] ""  BEV_GW
 SG_ CECU18DAC4E1_DIAG_DATA_EXT2 : 135|64@0+ (1,0) [0|1.844674407371E+19] ""  BEV_GW
 SG_ CECU18DAC4E1_DIAG_DATA_EXT1 : 71|64@0+ (1,0) [0|1.844674407371E+19] ""  BEV_GW
 SG_ CECU18DAC4E1_DIAG_DATA : 7|64@0+ (1,0) [0|1.844674407371E+19] ""  BEV_GW

BO_ 2564481215 SCA18DAE0BF: 64 ADAS_GW
 SG_ SCA18DAE0BF_DIAG_DATA_EXT7 : 455|64@0+ (1,0) [0|1.844674407371E+19] ""  C_ECU_GW
 SG_ SCA18DAE0BF_DIAG_DATA_EXT6 : 391|64@0+ (1,0) [0|1.844674407371E+19] ""  C_ECU_GW
 SG_ SCA18DAE0BF_DIAG_DATA_EXT5 : 327|64@0+ (1,0) [0|1.844674407371E+19] ""  C_ECU_GW
 SG_ SCA18DAE0BF_DIAG_DATA_EXT4 : 263|64@0+ (1,0) [0|1.844674407371E+19] ""  C_ECU_GW
 SG_ SCA18DAE0BF_DIAG_DATA_EXT3 : 199|64@0+ (1,0) [0|1.844674407371E+19] ""  C_ECU_GW
 SG_ SCA18DAE0BF_DIAG_DATA_EXT2 : 135|64@0+ (1,0) [0|1.844674407371E+19] ""  C_ECU_GW
 SG_ SCA18DAE0BF_DIAG_DATA_EXT1 : 71|64@0+ (1,0) [0|1.844674407371E+19] ""  C_ECU_GW
 SG_ SCA18DAE0BF_DIAG_DATA : 7|64@0+ (1,0) [0|1.844674407371E+19] ""  C_ECU_GW

BO_ 2564472800 DNT18DABFE0: 64 C_ECU_GW
 SG_ DNT18DABFE0_DIAG_DATA_EXT7 : 455|64@0+ (1,0) [0|1.844674407371E+19] ""  ADAS_GW
 SG_ DNT18DABFE0_DIAG_DATA_EXT6 : 391|64@0+ (1,0) [0|1.844674407371E+19] ""  ADAS_GW
 SG_ DNT18DABFE0_DIAG_DATA_EXT5 : 327|64@0+ (1,0) [0|1.844674407371E+19] ""  ADAS_GW
 SG_ DNT18DABFE0_DIAG_DATA_EXT4 : 263|64@0+ (1,0) [0|1.844674407371E+19] ""  ADAS_GW
 SG_ DNT18DABFE0_DIAG_DATA_EXT3 : 199|64@0+ (1,0) [0|1.844674407371E+19] ""  ADAS_GW
 SG_ DNT18DABFE0_DIAG_DATA_EXT2 : 135|64@0+ (1,0) [0|1.844674407371E+19] ""  ADAS_GW
 SG_ DNT18DABFE0_DIAG_DATA_EXT1 : 71|64@0+ (1,0) [0|1.844674407371E+19] ""  ADAS_GW
 SG_ DNT18DABFE0_DIAG_DATA : 7|64@0+ (1,0) [0|1.844674407371E+19] ""  ADAS_GW

BO_ 2564481216 ADAS18DAE0C0: 64 ADAS
 SG_ ADAS18DAE0C0_DIAG_DATA_EXT7 : 455|64@0+ (1,0) [0|1.844674407371E+19] ""  C_ECU_GW
 SG_ ADAS18DAE0C0_DIAG_DATA_EXT6 : 391|64@0+ (1,0) [0|1.844674407371E+19] ""  C_ECU_GW
 SG_ ADAS18DAE0C0_DIAG_DATA_EXT5 : 327|64@0+ (1,0) [0|1.844674407371E+19] ""  C_ECU_GW
 SG_ ADAS18DAE0C0_DIAG_DATA_EXT4 : 263|64@0+ (1,0) [0|1.844674407371E+19] ""  C_ECU_GW
 SG_ ADAS18DAE0C0_DIAG_DATA_EXT3 : 199|64@0+ (1,0) [0|1.844674407371E+19] ""  C_ECU_GW
 SG_ ADAS18DAE0C0_DIAG_DATA_EXT2 : 135|64@0+ (1,0) [0|1.844674407371E+19] ""  C_ECU_GW
 SG_ ADAS18DAE0C0_DIAG_DATA_EXT1 : 71|64@0+ (1,0) [0|1.844674407371E+19] ""  C_ECU_GW
 SG_ ADAS18DAE0C0_DIAG_DATA : 7|64@0+ (1,0) [0|1.844674407371E+19] ""  C_ECU_GW

BO_ 2564473056 DNT18DAC0E0: 64 C_ECU_GW
 SG_ DNT18DAC0E0_DIAG_DATA_EXT7 : 455|64@0+ (1,0) [0|1.844674407371E+19] ""  ADAS
 SG_ DNT18DAC0E0_DIAG_DATA_EXT6 : 391|64@0+ (1,0) [0|1.844674407371E+19] ""  ADAS
 SG_ DNT18DAC0E0_DIAG_DATA_EXT5 : 327|64@0+ (1,0) [0|1.844674407371E+19] ""  ADAS
 SG_ DNT18DAC0E0_DIAG_DATA_EXT4 : 263|64@0+ (1,0) [0|1.844674407371E+19] ""  ADAS
 SG_ DNT18DAC0E0_DIAG_DATA_EXT3 : 199|64@0+ (1,0) [0|1.844674407371E+19] ""  ADAS
 SG_ DNT18DAC0E0_DIAG_DATA_EXT2 : 135|64@0+ (1,0) [0|1.844674407371E+19] ""  ADAS
 SG_ DNT18DAC0E0_DIAG_DATA_EXT1 : 71|64@0+ (1,0) [0|1.844674407371E+19] ""  ADAS
 SG_ DNT18DAC0E0_DIAG_DATA : 7|64@0+ (1,0) [0|1.844674407371E+19] ""  ADAS

BO_ 2564481472 ADAS18DAE1C0: 64 ADAS
 SG_ ADAS18DAE1C0_DIAG_DATA_EXT7 : 455|64@0+ (1,0) [0|1.844674407371E+19] ""  C_ECU
 SG_ ADAS18DAE1C0_DIAG_DATA_EXT6 : 391|64@0+ (1,0) [0|1.844674407371E+19] ""  C_ECU
 SG_ ADAS18DAE1C0_DIAG_DATA_EXT5 : 327|64@0+ (1,0) [0|1.844674407371E+19] ""  C_ECU
 SG_ ADAS18DAE1C0_DIAG_DATA_EXT4 : 263|64@0+ (1,0) [0|1.844674407371E+19] ""  C_ECU
 SG_ ADAS18DAE1C0_DIAG_DATA_EXT3 : 199|64@0+ (1,0) [0|1.844674407371E+19] ""  C_ECU
 SG_ ADAS18DAE1C0_DIAG_DATA_EXT2 : 135|64@0+ (1,0) [0|1.844674407371E+19] ""  C_ECU
 SG_ ADAS18DAE1C0_DIAG_DATA_EXT1 : 71|64@0+ (1,0) [0|1.844674407371E+19] ""  C_ECU
 SG_ ADAS18DAE1C0_DIAG_DATA : 7|64@0+ (1,0) [0|1.844674407371E+19] ""  C_ECU

BO_ 2564473057 CECU18DAC0E1: 64 C_ECU
 SG_ CECU18DAC0E1_DIAG_DATA_EXT7 : 455|64@0+ (1,0) [0|1.844674407371E+19] ""  ADAS
 SG_ CECU18DAC0E1_DIAG_DATA_EXT6 : 391|64@0+ (1,0) [0|1.844674407371E+19] ""  ADAS
 SG_ CECU18DAC0E1_DIAG_DATA_EXT5 : 327|64@0+ (1,0) [0|1.844674407371E+19] ""  ADAS
 SG_ CECU18DAC0E1_DIAG_DATA_EXT4 : 263|64@0+ (1,0) [0|1.844674407371E+19] ""  ADAS
 SG_ CECU18DAC0E1_DIAG_DATA_EXT3 : 199|64@0+ (1,0) [0|1.844674407371E+19] ""  ADAS
 SG_ CECU18DAC0E1_DIAG_DATA_EXT2 : 135|64@0+ (1,0) [0|1.844674407371E+19] ""  ADAS
 SG_ CECU18DAC0E1_DIAG_DATA_EXT1 : 71|64@0+ (1,0) [0|1.844674407371E+19] ""  ADAS
 SG_ CECU18DAC0E1_DIAG_DATA : 7|64@0+ (1,0) [0|1.844674407371E+19] ""  ADAS

BO_ 2564487618 IAVAS18DAF9C2: 8 IAVAS
 SG_ IAVAS18DAF9C2_DIAG_DATA : 7|64@0+ (1,0) [0|1.844674407371E+19] "" Vector__XXX

BO_ 2564473593 ePTI18DAC2F9: 8 Vector__XXX

BO_ 2564481474 IAVAS18DAE1C2: 64 IAVAS
 SG_ IAVAS18DAE1C2_DIAG_DATA_EXT7 : 455|64@0+ (1,0) [0|1.844674407371E+19] ""  C_ECU
 SG_ IAVAS18DAE1C2_DIAG_DATA_EXT6 : 391|64@0+ (1,0) [0|1.844674407371E+19] ""  C_ECU
 SG_ IAVAS18DAE1C2_DIAG_DATA_EXT5 : 327|64@0+ (1,0) [0|1.844674407371E+19] ""  C_ECU
 SG_ IAVAS18DAE1C2_DIAG_DATA_EXT4 : 263|64@0+ (1,0) [0|1.844674407371E+19] ""  C_ECU
 SG_ IAVAS18DAE1C2_DIAG_DATA_EXT3 : 199|64@0+ (1,0) [0|1.844674407371E+19] ""  C_ECU
 SG_ IAVAS18DAE1C2_DIAG_DATA_EXT2 : 135|64@0+ (1,0) [0|1.844674407371E+19] ""  C_ECU
 SG_ IAVAS18DAE1C2_DIAG_DATA_EXT1 : 71|64@0+ (1,0) [0|1.844674407371E+19] ""  C_ECU
 SG_ IAVAS18DAE1C2_DIAG_DATA : 7|64@0+ (1,0) [0|1.844674407371E+19] ""  C_ECU

BO_ 2564473569 CECU18DAC2E1: 64 C_ECU
 SG_ CECU18DAC2E1_DIAG_DATA_EXT7 : 455|64@0+ (1,0) [0|1.844674407371E+19] ""  IAVAS
 SG_ CECU18DAC2E1_DIAG_DATA_EXT6 : 391|64@0+ (1,0) [0|1.844674407371E+19] ""  IAVAS
 SG_ CECU18DAC2E1_DIAG_DATA_EXT5 : 327|64@0+ (1,0) [0|1.844674407371E+19] ""  IAVAS
 SG_ CECU18DAC2E1_DIAG_DATA_EXT4 : 263|64@0+ (1,0) [0|1.844674407371E+19] ""  IAVAS
 SG_ CECU18DAC2E1_DIAG_DATA_EXT3 : 199|64@0+ (1,0) [0|1.844674407371E+19] ""  IAVAS
 SG_ CECU18DAC2E1_DIAG_DATA_EXT2 : 135|64@0+ (1,0) [0|1.844674407371E+19] ""  IAVAS
 SG_ CECU18DAC2E1_DIAG_DATA_EXT1 : 71|64@0+ (1,0) [0|1.844674407371E+19] ""  IAVAS
 SG_ CECU18DAC2E1_DIAG_DATA : 7|64@0+ (1,0) [0|1.844674407371E+19] ""  IAVAS

BO_ 2564481218 IAVAS18DAE0C2: 8 IAVAS
 SG_ IAVAS18DAE0C2_DIAG_DATA : 7|64@0+ (1,0) [0|1.844674407371E+19] ""  C_ECU_GW

BO_ 2564473568 DNT18DAC2E0: 8 C_ECU_GW
 SG_ DNT18DAC2E0_DIAG_DATA : 7|64@0+ (1,0) [0|1.844674407371E+19] ""  IAVAS

BO_TX_BU_ 267 : BEV,C_ECU_GW;

CM_ SG_ 1370 MCA55A_0_0_NETWORK_STATUS "ﾈｯﾄﾜｰｸｽﾃｰﾀｽ
";
CM_ SG_ 1606 EYE646_1_0_MSG_COUNTER "ﾒｯｾｰｼﾞｶｳﾝﾀ
";
CM_ SG_ 1606 EYE646_1_4_DEADMAN_NOTIFICATION "DN要求
";
CM_ SG_ 1606 EYE646_0_0_CHECK_SUM "ﾁｪｯｸｻﾑ
";
CM_ SG_ 967 EYE3C7_7_3_WARN_ESCALATION_REQ "警報エスカレーション連動
";
CM_ SG_ 967 EYE3C7_7_6_AEB_MSB_LINK "AEB連動信号
";
CM_ SG_ 967 EYE3C7_4_0_LKS_DMS_COOPERATION "LKS_DMS連携有無
";
CM_ SG_ 967 EYE3C7_4_1_LKS_ACTIVE "LKSアクティブ状態
";
CM_ SG_ 967 EYE3C7_2_0_ALC_CONTROL "ALC制御状態
";
CM_ SG_ 967 EYE3C7_2_1_WINKER_OFF_REQ "ウィンカー消灯要求
";
CM_ SG_ 967 EYE3C7_2_2_HORN_HAZARD_ON_REQ "ホーンハザード駆動要求
";
CM_ SG_ 967 EYE3C7_2_4_DR_UNLOCK_REQ "ドアアンロック要求
";
CM_ SG_ 967 EYE3C7_2_5_WINKER_ON_REQ "ウィンカー点灯要求
";
CM_ SG_ 967 EYE3C7_2_7_MRM_ACTIVE "MRMアクティブ状態
";
CM_ SG_ 967 EYE3C7_1_0_MSG_COUNTER "ﾒｯｾｰｼﾞｶｳﾝﾀ
";
CM_ SG_ 967 EYE3C7_0_0_CHECK_SUM "ﾁｪｯｸｻﾑ
";
CM_ SG_ 966 EYE3C6_7_0_VEHICLE_DIST_L_LANE1 "左車線先行車１縦位置
";
CM_ SG_ 966 EYE3C6_7_7_VEHICLE_L_LANE1 "左車線先行車１
";
CM_ SG_ 966 EYE3C6_6_0_VEHICLE_DIST_R_LANE1 "右車線先行車１縦位置
";
CM_ SG_ 966 EYE3C6_6_7_VEHICLE_R_LANE1 "右車線先行車１
";
CM_ SG_ 966 EYE3C6_5_0_VEHICLE_DIST_WY_WAY1 "自車線先行車１縦位置
";
CM_ SG_ 966 EYE3C6_5_7_VEHICLE_MY_WAY1 "自車線先行車１
";
CM_ SG_ 966 EYE3C6_4_0_SIDE_MOVEMENT "自車表示_位置
";
CM_ SG_ 966 EYE3C6_3_0_RADER_RR "後側方レーダ-_右
";
CM_ SG_ 966 EYE3C6_3_2_RADER_RL "後側方レーダ-_左
";
CM_ SG_ 966 EYE3C6_3_4_RADER_FR "前側方レーダ-_右
";
CM_ SG_ 966 EYE3C6_3_6_RADER_FL "前側方レーダ-_左
";
CM_ SG_ 966 EYE3C6_2_0_RADER_R "後方レーダ-
";
CM_ SG_ 966 EYE3C6_2_2_MY_WAY_LANE_CAR_COLOR "自車線車両色
";
CM_ SG_ 966 EYE3C6_2_4_TARGET_CAR "先行車ターゲット
";
CM_ SG_ 966 EYE3C6_2_7_ALC_STS "ALC状態
";
CM_ SG_ 966 EYE3C6_1_0_MSG_COUNTER "ﾒｯｾｰｼﾞｶｳﾝﾀ
";
CM_ SG_ 966 EYE3C6_1_4_L_LANE_CAR_COLOR "左車線車両色
";
CM_ SG_ 966 EYE3C6_1_6_R_LANE_CAR_COLOR "右車線車両色
";
CM_ SG_ 966 EYE3C6_0_0_CHECK_SUM "ﾁｪｯｸｻﾑ
";
CM_ SG_ 965 EYE3C5_7_0_GSR_AEBS_FUNC_INFO "GSR-AEBS機能有無フラグ
";
CM_ SG_ 965 EYE3C5_7_1_CSTM_CRV_ADJUST "カスタマイズ現在値(カーブ前減速度調整機能)
";
CM_ SG_ 965 EYE3C5_7_3_BRAKE_HAPTIC_CURR "カスタマイズ現在値設定(ブレーキハプティック)
";
CM_ SG_ 965 EYE3C5_7_5_SAFETY_MODE_FUNC_INFO "障害物なし加速抑制機能有無フラグ
";
CM_ SG_ 965 EYE3C5_7_6_SAFETY_MODE_CURR "カスタマイズ現在値設定(障害物なし加速抑制)
";
CM_ SG_ 965 EYE3C5_7_7_GSR_DDAW_FUNC_INFO "GSR-DDAW機能有無フラグ
";
CM_ SG_ 965 EYE3C5_6_0_IND_SAFETY_MODE "アクセル急踏み加速抑制機能ON灯
";
CM_ SG_ 965 EYE3C5_6_1_ALC_ACTIVE_L "ALC制御中表示_左
";
CM_ SG_ 965 EYE3C5_6_2_FLASHING_IND_SAFETY "安全重視モード点滅表示指示
";
CM_ SG_ 965 EYE3C5_6_3_OVERTAKE_FUNC_INFO "追い抜き抑制制御有無フラグ
";
CM_ SG_ 965 EYE3C5_6_4_CRV_ADJUST_FUNC_INFO "カーブ前減速度調整機能有無フラグ
";
CM_ SG_ 965 EYE3C5_6_5_STRG_TOUCHSENSOR_WRNG "ステアリングタッチセンサ故障灯
";
CM_ SG_ 965 EYE3C5_6_6_ALC_ACTIVE_R "ALC制御中表示_右
";
CM_ SG_ 965 EYE3C5_6_7_CSTM_GSR_ISA "GSR-ISA有無フラグ
";
CM_ SG_ 965 EYE3C5_5_0_LANE_COLOR_R "隣レーン色_右
";
CM_ SG_ 965 EYE3C5_5_2_LINE_LANE_R "隣外側車線表示_右
";
CM_ SG_ 965 EYE3C5_5_4_LANE_COLOR_L "隣レーン色_左
";
CM_ SG_ 965 EYE3C5_5_6_LINE_LANE_L "隣外側車線表示_左
";
CM_ SG_ 965 EYE3C5_4_0_ROAD_SHAPE_CURVE "道路形状_湾曲
";
CM_ SG_ 965 EYE3C5_4_4_ROAD_SHAPE_DIRECTION "道路形状_方向
";
CM_ SG_ 965 EYE3C5_4_5_CSTM_GSR_ELKS "GSR-ELKS有無フラグ
";
CM_ SG_ 965 EYE3C5_4_6_MY_WAY_COLOR "自レーンの色
";
CM_ SG_ 965 EYE3C5_3_0_AD_DRV_ICON "高度運転支援アイコン
";
CM_ SG_ 965 EYE3C5_3_2_AUTO_HANDLE_ICON "AUTOハンドルアイコン
";
CM_ SG_ 965 EYE3C5_3_4_WITH_HANDS_ICON "ハンズオン/ハンズオフ表示
";
CM_ SG_ 965 EYE3C5_3_5_STRG_HAPTIC_WRNG "ステアリングハプティック故障灯
";
CM_ SG_ 965 EYE3C5_3_6_BRK_HPTC_FUNC_INFO "ブレーキハプティック機能有無フラグ
";
CM_ SG_ 965 EYE3C5_3_7_SPECIAL_DISP_INFO "特殊標識表示機能有無フラグ
";
CM_ SG_ 965 EYE3C5_2_0_SLOWDWN_CURVE_ICON "カーブ前減速アイコン
";
CM_ SG_ 965 EYE3C5_2_3_FLASHING_IND "自車点滅指示
";
CM_ SG_ 965 EYE3C5_2_4_ATTENTION_TOLLGATE "料金所注意アイコン
";
CM_ SG_ 965 EYE3C5_2_6_MAPLOCATOR_IND "ロケータインジケータ
";
CM_ SG_ 965 EYE3C5_1_0_MSG_COUNTER "ﾒｯｾｰｼﾞｶｳﾝﾀ
";
CM_ SG_ 965 EYE3C5_1_4_ISA_FAIL_IND "ISA故障灯
";
CM_ SG_ 965 EYE3C5_1_5_SLWF_OFF_IND "SLWFOFF灯
";
CM_ SG_ 965 EYE3C5_1_6_CSTM_SLWF_SET "カスタマイズ現在値(SLWF)
";
CM_ SG_ 965 EYE3C5_1_7_CSTM_TSR_SOUND_SET "カスタマイズ現在値(標識切り替わり警報音)
";
CM_ SG_ 965 EYE3C5_0_0_CHECK_SUM "ﾁｪｯｸｻﾑ
";
CM_ SG_ 964 EYE3C4_7_0_PCR_FAIL_OFF_IND "プリクラ故障/OFF灯指示
";
CM_ SG_ 964 EYE3C4_7_2_AES_FAIL_OFF_IND "AES故障/OFF灯指示
";
CM_ SG_ 964 EYE3C4_7_4_LDP_FAIL_OFF_IND "LDP故障/OFF灯指示
";
CM_ SG_ 964 EYE3C4_7_6_ELK_FAIL_OFF_IND "ELK故障/OFF灯指示
";
CM_ SG_ 964 EYE3C4_6_0_MCAM_SYS_FAIL_HALT "単眼故障状態通知(HALT/FAIL)
";
CM_ SG_ 964 EYE3C4_6_2_MCAM_FUNC_INFO "単眼機能有無フラグ
";
CM_ SG_ 964 EYE3C4_6_3_EYE_DRV_ACTION_REQ "アイサイトドライバアクション要求
";
CM_ SG_ 964 EYE3C4_6_6_LDW_SND_OFF_FAIL_IND "LDW音OFF灯/SW故障警告表示
";
CM_ SG_ 964 EYE3C4_5_0_EAM_GREEN "EAM点灯指示　緑
";
CM_ SG_ 964 EYE3C4_5_2_EAM_BLUE "EAM点灯指示　青
";
CM_ SG_ 964 EYE3C4_5_4_EAM_GREEN_2 "EAM点灯指示_緑2
";
CM_ SG_ 964 EYE3C4_5_6_FCW_SND_OFF_FAIL_IND "FCW音OFF灯/SW故障警告表示
";
CM_ SG_ 964 EYE3C4_4_0_EAM_YELLOW "EAM点灯指示　黄
";
CM_ SG_ 964 EYE3C4_4_4_EAM_RED "EAM点灯指示　赤
";
CM_ SG_ 964 EYE3C4_3_0_CODE_NO_BUZZER "警報コード（表示のみ）
";
CM_ SG_ 964 EYE3C4_2_0_CODE_WARN "警報コード（音有）
";
CM_ SG_ 964 EYE3C4_1_0_MSG_COUNTER "ﾒｯｾｰｼﾞｶｳﾝﾀ
";
CM_ SG_ 964 EYE3C4_1_5_SNR_DRV_ACTION_REQ "ソナードライバアクション要求
";
CM_ SG_ 964 EYE3C4_0_0_CHECK_SUM "ﾁｪｯｸｻﾑ
";
CM_ SG_ 554 EYE22A_5_0_RANGE_RIGHTMOST "検出範囲最右端
";
CM_ SG_ 554 EYE22A_3_0_RANGE_LEFTMOST "検出範囲最左端
";
CM_ SG_ 554 EYE22A_2_0_PERMIT_ADB "ADB許可ﾌﾗｸﾞ
";
CM_ SG_ 554 EYE22A_2_1_HBA_MODE "HBA許可ﾌﾗｸﾞ
";
CM_ SG_ 554 EYE22A_2_2_PROCEEDING "先行車有無ﾌﾗｸﾞ
";
CM_ SG_ 554 EYE22A_2_3_ONCOMING "対向車有無ﾌﾗｸﾞ
";
CM_ SG_ 554 EYE22A_2_4_OBJ_LEFTMOST "最左端対象種別
";
CM_ SG_ 554 EYE22A_2_5_OBJ_RIGHTMOST "最右端対象種別
";
CM_ SG_ 554 EYE22A_2_6_SENSITIVITY_SETTING "感度調整ﾌﾗｸﾞ
";
CM_ SG_ 554 EYE22A_2_7_AHL_DATAFAIL_FLG "AHL通信データ異常フラグ
";
CM_ SG_ 554 EYE22A_1_0_MSG_COUNTER "ﾒｯｾｰｼﾞｶｳﾝﾀ
";
CM_ SG_ 554 EYE22A_1_4_FAIL "ｱｲｻｲﾄﾌｪｰﾙ
";
CM_ SG_ 554 EYE22A_1_5_INIT_END "ｱｲｻｲﾄｶﾒﾗ初期化完了ﾌﾗｸﾞ
";
CM_ SG_ 554 EYE22A_1_6_HALT "ｱｲｻｲﾄHALT
";
CM_ SG_ 554 EYE22A_1_7_EYEVISION_DIRT_FLG "アイサイト汚れ状態フラグ
";
CM_ SG_ 554 EYE22A_0_0_CHECK_SUM "ﾁｪｯｸｻﾑ
";
CM_ SG_ 807 EYE327_6_1_EDR_STATUS_ACSF_C "ACSF category C　EDR用 ステータス
";
CM_ SG_ 807 EYE327_6_4_EDR_STATUS_MRM "MRM EDR用ステータス
";
CM_ SG_ 807 EYE327_5_2_EDR_STATUS_FCTB "FCTB_EDR用ステータス
";
CM_ SG_ 807 EYE327_5_6_EDR_STATUS_ACSF_B1 "ACSF category B1　EDR用 ステータス
";
CM_ SG_ 807 EYE327_4_2_EDR_STATUS_PCB_EYECAM "PCB(EYECAM)_EDR用ステータス
";
CM_ SG_ 807 EYE327_4_6_EDR_STATUS_PCB_MCAM "PCB(MCAM)_EDR用ステータス
";
CM_ SG_ 807 EYE327_3_0_EDR_STATUS_CC "CC  EDR用ステータス
";
CM_ SG_ 807 EYE327_3_3_EDR_STATUS_ACC "ACC EDR用ステータス
";
CM_ SG_ 807 EYE327_3_6_EDR_STATUS_AEBS "AEBS_EDR用ステータス
";
CM_ SG_ 807 EYE327_2_2_EDR_STATUS_ESF_ELK "ELK EDR用ステータス
";
CM_ SG_ 807 EYE327_2_5_EDR_STATUS_CSF_LDP "LDP・RE　EDR用ステータス
";
CM_ SG_ 807 EYE327_1_0_MSG_COUNTER "ﾒｯｾｰｼﾞｶｳﾝﾀ
";
CM_ SG_ 807 EYE327_1_4_EDR_STATUS_LDWS "LDW EDR用ステータス
";
CM_ SG_ 807 EYE327_1_7_EDR_STATUS_ESF_AES "AES EDR用ステータス
";
CM_ SG_ 807 EYE327_0_0_CHECK_SUM "ﾁｪｯｸｻﾑ
";
CM_ SG_ 806 EYE326_5_0_TIME "時刻情報
";
CM_ SG_ 806 EYE326_4_3_DAY "日付情報：日
";
CM_ SG_ 806 EYE326_3_0_YEAR "日付情報：年
";
CM_ SG_ 806 EYE326_3_7_MONTH "日付情報：月
";
CM_ SG_ 806 EYE326_2_0_MRM_OPE_ST "MRM動作状態
";
CM_ SG_ 806 EYE326_2_1_DRIVER_TORQUE_STATE "ドライバートルク状態
";
CM_ SG_ 806 EYE326_2_3_DRIVER_ACCEL_STATE "ドライバーアクセル状態
";
CM_ SG_ 806 EYE326_1_0_MSG_COUNTER "ﾒｯｾｰｼﾞｶｳﾝﾀ
";
CM_ SG_ 806 EYE326_1_4_SYS_ST "システム状態
";
CM_ SG_ 806 EYE326_1_5_TAKE_OVR_REQ "引継要求
";
CM_ SG_ 806 EYE326_1_7_OVERRIDE "オーバライド
";
CM_ SG_ 806 EYE326_0_0_CHECK_SUM "ﾁｪｯｸｻﾑ
";
CM_ SG_ 805 EYE325_6_5_SONAR_DISP_INT "ｸﾘｿﾅ割り込み表示ﾌﾗｸﾞ
";
CM_ SG_ 805 EYE325_5_0_SONAR_R_L_CORNER_4LVL "リアソナー距離警報情報(左コーナー4段階)
";
CM_ SG_ 805 EYE325_5_3_SONAR_R_R_CORNER_4LVL "リアソナー距離警報情報(右コーナー4段階)
";
CM_ SG_ 805 EYE325_4_0_SONAR_R_CENTER "ﾘｱｿﾅｰ距離警報情報：Rcenter（中央4段階）
";
CM_ SG_ 805 EYE325_4_3_SONAR_LEVEL "RAB/ｸﾘｿﾅ警報音ﾚﾍﾞﾙ
";
CM_ SG_ 805 EYE325_4_6_RAB_WARNING "RAB警報割込み表示指示
";
CM_ SG_ 805 EYE325_3_0_SONAR_R_L_CORNER "ﾘｱｿﾅｰ距離警報情報：RLConner（左ｺｰﾅ3段階）
";
CM_ SG_ 805 EYE325_3_2_SONAR_R_R_CORNER "ﾘｱｿﾅｰ距離警報情報：RRConner（右ｺｰﾅ3段階）
";
CM_ SG_ 805 EYE325_3_4_SONAR_R_L_SIDE "ﾘｱｿﾅｰ距離警報情報：RLSide（左ｻｲﾄﾞ3段階：予約）
";
CM_ SG_ 805 EYE325_3_6_SONAR_R_R_SIDE "ﾘｱｿﾅｰ距離警報情報：RRSide（右ｻｲﾄﾞ3段階：予約）
";
CM_ SG_ 805 EYE325_2_0_RAB_OFF "RAB 機能OFF状態通知
";
CM_ SG_ 805 EYE325_2_1_SONAR_OFF "警報音機能OFF状態通知
";
CM_ SG_ 805 EYE325_2_2_SONAR_SYS_HALT "ｿﾅｰｼｽﾃﾑ一時停止状態通知 (Fault)
";
CM_ SG_ 805 EYE325_2_4_SONAR_SYS_FAIL "ｿﾅｰｼｽﾃﾑ故障状態通知 (Fail)
";
CM_ SG_ 805 EYE325_2_6_RAB_DISABLE "RAB機能一時OFF操作不可
";
CM_ SG_ 805 EYE325_2_7_SONAR_DISABLE "警報音一時OFF操作不可
";
CM_ SG_ 805 EYE325_1_0_MSG_COUNTER "ﾒｯｾｰｼﾞｶｳﾝﾀ
";
CM_ SG_ 805 EYE325_1_4_CSTM_RAB_SET "SNRｶｽﾀﾏｲｽﾞ現在値設定(RAB機能)
";
CM_ SG_ 805 EYE325_1_5_CSTM_CLR_SNR_SET "SNRｶｽﾀﾏｲｽﾞ現在値設定(ｸﾘｱﾗﾝｽｿﾅｰ機能)
";
CM_ SG_ 805 EYE325_1_6_RAB "RAB機能設定ﾌﾗｸﾞ
";
CM_ SG_ 805 EYE325_1_7_SONAR_NO_DISP "ｿﾅｰｼｽﾃﾑ画面非表示ﾌﾗｸﾞ
";
CM_ SG_ 805 EYE325_0_0_CHECK_SUM "ﾁｪｯｸｻﾑ
";
CM_ SG_ 804 EYE324_7_5_TSR_MODE_DISP "標識連動表示
";
CM_ SG_ 804 EYE324_7_7_ICON_IND "標識アイコン表示指示
";
CM_ SG_ 804 EYE324_6_0_COMPLEMENTARY_IND_C "補助標識情報表示指示（エリアC）
";
CM_ SG_ 804 EYE324_6_4_COMPLEMENTARY_IND_D "補助標識情報表示指示（エリアD）
";
CM_ SG_ 804 EYE324_5_0_SPEEDLIMIT_B "制限車速表示（エリアB）
";
CM_ SG_ 804 EYE324_4_0_TRAFFIC_SIGN_B "制限車速背景意匠&規制標識情報表示指示（エリアB）
";
CM_ SG_ 804 EYE324_4_5_FLASHING_IND_B "点滅表示指示（エリアB）
";
CM_ SG_ 804 EYE324_4_6_FRAME_COLOR_B "標識枠色（エリアB）
";
CM_ SG_ 804 EYE324_3_0_SPEEDLIMIT_A "制限車速表示（エリアA）
";
CM_ SG_ 804 EYE324_2_0_TRAFFIC_SIGN_A "制限車速背景意匠&規制標識情報表示指示（エリアA）
";
CM_ SG_ 804 EYE324_2_5_FLASHING_IND_A "点滅表示指示（エリアA）
";
CM_ SG_ 804 EYE324_2_6_FRAME_COLOR_A "標識枠色（エリアA）
";
CM_ SG_ 804 EYE324_1_0_MSG_COUNTER "ﾒｯｾｰｼﾞｶｳﾝﾀ
";
CM_ SG_ 804 EYE324_1_4_FLASHING_IND_D "点滅表示指示（エリアD）
";
CM_ SG_ 804 EYE324_1_5_FLASHING_IND_C "点滅表示指示（エリアC）
";
CM_ SG_ 804 EYE324_1_6_ICON_COLOR "標識アイコン色
";
CM_ SG_ 804 EYE324_0_0_CHECK_SUM "ﾁｪｯｸｻﾑ
";
CM_ SG_ 803 EYE323_7_0_ISA_OFFSET_CURR "ISA制限車速オフセット値
";
CM_ SG_ 803 EYE323_7_5_SLIF_FUNC_INFO "標識認識機能有無情報
";
CM_ SG_ 803 EYE323_7_6_ISA_FUNC_INFO "ISA機能有無情報
";
CM_ SG_ 803 EYE323_7_7_ISA_CUSTOMIZE_CURR "ｱｲｻｲﾄｶｽﾀﾏｲｽﾞ現在設定値(ISA)
";
CM_ SG_ 803 EYE323_6_0_LDW_OFFSW_INFO "LDW音　OFFスイッチ有無
";
CM_ SG_ 803 EYE323_6_1_LDW_ON_OFF_SET "LDW音 ON/OFF現在設定値
";
CM_ SG_ 803 EYE323_6_2_CSTM_DDAW_WARN_SET "カスタマイズ現在値(DDAW警報)
";
CM_ SG_ 803 EYE323_6_3_IACC_FUNC_INFO "iACC機能有無フラグ
";
CM_ SG_ 803 EYE323_6_5_CSTM_LDW_TIMING_SET "LDWタイミングカスタマイズ現在設定値
";
CM_ SG_ 803 EYE323_6_6_CSTM_LDW_TIMING "LDWタイミングカスタマイズ有無
";
CM_ SG_ 803 EYE323_6_7_SLOWDOWNL_FUNC_INFO "カーブ前減速機能有無
";
CM_ SG_ 803 EYE323_5_0_CNG_GRN_CONT_CURR "カスタマイズ現在値（青信号切り替わりお知らせ）
";
CM_ SG_ 803 EYE323_5_1_TRAFFIC_FUNC_INFO "信号制御機能有無
";
CM_ SG_ 803 EYE323_5_2_FCW_OFFSW_INFO "FCW OFFスイッチ有無
";
CM_ SG_ 803 EYE323_5_3_FCW_ON_OFF_SET "FCW ON/OFF現在設定値
";
CM_ SG_ 803 EYE323_5_4_WARNING_SEL_CURR "カスタマイズ現在値（警報方法）
";
CM_ SG_ 803 EYE323_5_5_HAPT_FUNC_INFO "ステア振動（警報方法）機能有無
";
CM_ SG_ 803 EYE323_5_6_TOLLGATE_CONT_CURR "カスタマイズ現在値（料金所減速 ）
";
CM_ SG_ 803 EYE323_5_7_CURVE_CONT_CURR "カスタマイズ現在値（カーブ減速 ）
";
CM_ SG_ 803 EYE323_4_0_FCTB_ICON_L "FCTBお知らせアイコン_左
";
CM_ SG_ 803 EYE323_4_2_FCTB_ICON_R "FCTBお知らせアイコン_右
";
CM_ SG_ 803 EYE323_4_4_FCW_CONT_CURR "カスタマイズ現在値（FCW)
";
CM_ SG_ 803 EYE323_4_6_FCW_DISPLAY_SEL "FCWカスタマイズ項目表示指示
";
CM_ SG_ 803 EYE323_3_0_AES_FUNC_INFO "AES機能有無
";
CM_ SG_ 803 EYE323_3_1_CSTM_TSR_NO_ENTRY_SET "カスタマイズ現在値(進入禁止標識)
";
CM_ SG_ 803 EYE323_3_2_CSTM_TSR_STOP_SET "カスタマイズ現在値(一時停止標識)
";
CM_ SG_ 803 EYE323_3_3_CSTM_TSR_GIVE_WAY_SET "カスタマイズ現在値(前方優先道路標識)
";
CM_ SG_ 803 EYE323_3_4_WILDERNESS "Wilderness識別情報
";
CM_ SG_ 803 EYE323_3_5_AES_OFF "AES  OFFｲﾝｼﾞｹｰﾀ信号
";
CM_ SG_ 803 EYE323_3_6_FCTB_IND "FCTBインジケータ
";
CM_ SG_ 803 EYE323_2_0_CSTM_LDW_ALK_B "ｱｲｻｲﾄｶｽﾀﾏｲｽﾞ現在値設定（LDW/ALK-B）
";
CM_ SG_ 803 EYE323_2_2_CSTM_P_CR "ｱｲｻｲﾄｶｽﾀﾏｲｽﾞ現在値設定（P-CR）
";
CM_ SG_ 803 EYE323_2_3_SLOWDOWN_FUNC_INFO2 "料金所前減速機能有無
";
CM_ SG_ 803 EYE323_2_4_CID_CODE_WARN "CID警報ｺｰﾄﾞ
";
CM_ SG_ 803 EYE323_1_0_MSG_COUNTER "ﾒｯｾｰｼﾞｶｳﾝﾀ
";
CM_ SG_ 803 EYE323_1_4_DISP_FOLLOW_FORWARD "先行車追従表示フラグ
";
CM_ SG_ 803 EYE323_1_5_KEEP_LINE_SENTER_ACT "白線中央維持制御中フラグ
";
CM_ SG_ 803 EYE323_1_6_DDAW_FAIL_OFF "DDAW故障/OFF灯
";
CM_ SG_ 803 EYE323_0_0_CHECK_SUM "ﾁｪｯｸｻﾑ
";
CM_ SG_ 802 EYE322_7_0_CSTM_ACC_CONT_SET "ｱｲｻｲﾄｶｽﾀﾏｲｽﾞ現在値設定（ACC加速特性）
";
CM_ SG_ 802 EYE322_7_2_ELK_OFF_IND "ELK OFF灯表示
";
CM_ SG_ 802 EYE322_7_3_LIGHT_EAM_YELLOW "EAM(黄)点灯指示
";
CM_ SG_ 802 EYE322_7_5_BROKEN_LINE_L "車線表示切替_左
";
CM_ SG_ 802 EYE322_7_6_TJA_ACTIVE "TJA作動中フラグ
";
CM_ SG_ 802 EYE322_7_7_BROKEN_LINE_R "車線表示切替_右
";
CM_ SG_ 802 EYE322_6_0_CSTM_MIS_AT_START "ｱｲｻｲﾄｶｽﾀﾏｲｽﾞ現在設定値(AT誤後進抑制制御)
";
CM_ SG_ 802 EYE322_6_2_CSTM_ALK_TJA_SET "ｱｲｻｲﾄｶｽﾀﾏｲｽﾞ現在値設定(車線中央維持・TJA)
";
CM_ SG_ 802 EYE322_6_3_CSTM_LANE_SET "ｱｲｻｲﾄｶｽﾀﾏｲｽﾞ現在設定値（通行車線）
";
CM_ SG_ 802 EYE322_6_4_LDP_OFF_IND "LDP OFF灯表示
";
CM_ SG_ 802 EYE322_6_5_INDICATOR_MODE_L "左側ミラーインジケータ制御指示フラグ
";
CM_ SG_ 802 EYE322_6_7_CSTM_ELK_SET "ｱｲｻｲﾄｶｽﾀﾏｲｽﾞ現在設定値（ELK)
";
CM_ SG_ 802 EYE322_5_0_CSTM_MIS_AT_BACK "ｱｲｻｲﾄ機能有無情報(AT誤後進抑制制御)
";
CM_ SG_ 802 EYE322_5_1_CSTM_ALK_TJA "ｱｲｻｲﾄ機能有無情報(車線中央維持・TJA)
";
CM_ SG_ 802 EYE322_5_2_CSTM_SAS "ｱｲｻｲﾄ機能有無情報(SAS)
";
CM_ SG_ 802 EYE322_5_3_CSTM_HBA "ｱｲｻｲﾄ機能有無情報(HBA)
";
CM_ SG_ 802 EYE322_5_4_CSTM_ACC_CONT "ｱｲｻｲﾄ機能有無情報(ACC加速特性)
";
CM_ SG_ 802 EYE322_5_5_CSTM_LANE "ｱｲｻｲﾄ機能有無情報（通行車線）
";
CM_ SG_ 802 EYE322_5_6_LDW_SOUND_OFF_IND "LDW音 OFF灯表示
";
CM_ SG_ 802 EYE322_5_7_CSTM_ELK_SET "ｱｲｻｲﾄ機能有無情報（ELK）
";
CM_ SG_ 802 EYE322_4_0_CODE_WARN "警報ｺｰﾄﾞ（音有り）
";
CM_ SG_ 802 EYE322_4_5_CSTM_GSR "GSR対応有無フラグ
";
CM_ SG_ 802 EYE322_3_0_LANE_L "車線左表示
";
CM_ SG_ 802 EYE322_3_2_LANE_R "車線右表示
";
CM_ SG_ 802 EYE322_3_4_LANE_L_COLOR "車線左色
";
CM_ SG_ 802 EYE322_3_6_LANE_R_COLOR "車線右色
";
CM_ SG_ 802 EYE322_2_0_FCW_OFF_IND "FCW OFF灯表示
";
CM_ SG_ 802 EYE322_2_1_MOV_EYESIGHT_SCREEN "ｱｲｻｲﾄ画面移行ﾌﾗｸﾞ(ID322)
";
CM_ SG_ 802 EYE322_2_2_ALK_ICON "ALK表示
";
CM_ SG_ 802 EYE322_2_4_INDICATOR_CTRL_REQ "ミラーインジケータ制御フラグ
";
CM_ SG_ 802 EYE322_2_5_INDICATOR_MODE_R "右側ミラーインジケータ制御指示フラグ
";
CM_ SG_ 802 EYE322_2_7_LIMITER_BACK_SPEED "後退速度ﾘﾐｯﾀｰ設定値表示
";
CM_ SG_ 802 EYE322_1_0_MSG_COUNTER "ﾒｯｾｰｼﾞｶｳﾝﾀ
";
CM_ SG_ 802 EYE322_1_4_CODE_NO_BUZZER "警報ｺｰﾄﾞ（表示のみ）
";
CM_ SG_ 802 EYE322_1_7_DISTWARN_DMS "車間距離警報早鳴りﾌﾗｸﾞ
";
CM_ SG_ 802 EYE322_0_0_CHECK_SUM "ﾁｪｯｸｻﾑ
";
CM_ SG_ 801 EYE321_7_0_INFO_DIST_FORWARD "先行車距離
";
CM_ SG_ 801 EYE321_7_4_INFO_KEEP_STOP "停止保持中(HOLD)表示
";
CM_ SG_ 801 EYE321_7_5_INFO_READY "READY表示
";
CM_ SG_ 801 EYE321_7_6_INFO_SET_CC "ｸﾙｺﾝSET表示
";
CM_ SG_ 801 EYE321_7_7_INFO_OFF "OFF表示
";
CM_ SG_ 801 EYE321_6_0_FAIL_EYESIGHT "ｱｲｻｲﾄﾌｪｰﾙﾌﾗｸﾞ
";
CM_ SG_ 801 EYE321_6_1_MOV_EYESIGHT_SCREEN "ｱｲｻｲﾄ画面移行ﾌﾗｸﾞ(ID321)
";
CM_ SG_ 801 EYE321_6_2_IND_VEHICLE "自車表示
";
CM_ SG_ 801 EYE321_6_3_BRAKELAMP_VEHICLE "自車ﾌﾞﾚｰｷﾗﾝﾌﾟ点灯状態
";
CM_ SG_ 801 EYE321_6_4_IND_FORWARD_VECL "先行車表示
";
CM_ SG_ 801 EYE321_6_5_BRAKELAMP_FORWARD "先行車ﾌﾞﾚｰｷﾗﾝﾌﾟ点灯状態
";
CM_ SG_ 801 EYE321_6_6_CC_OR_LIM_SON "ｸﾙｺﾝ・ﾘﾐｯﾀｾｯﾄ状態
";
CM_ SG_ 801 EYE321_6_7_TEMP_OFF_STATE "一括一時OFF状態
";
CM_ SG_ 801 EYE321_5_0_INFO_SET_SPD "ｾｯﾄ車速表示
";
CM_ SG_ 801 EYE321_4_0_ACC_MODE "ACC/CC/SASﾓｰﾄﾞﾌﾗｸﾞ
";
CM_ SG_ 801 EYE321_4_2_SRVD_LASTMEM_ST_REQ "SRVDラストメモリ起動要求フラグ
";
CM_ SG_ 801 EYE321_4_3_INFO_MAIN_CC "ｸﾙｺﾝﾒｲﾝ表示
";
CM_ SG_ 801 EYE321_4_5_TRAFFIC_LIGHT "信号表示
";
CM_ SG_ 801 EYE321_3_0_CODE_HALT "ＨＡＬＴｺｰﾄﾞ
";
CM_ SG_ 801 EYE321_3_3_ELK_EQUIP "ELK機能有無
";
CM_ SG_ 801 EYE321_3_4_SET_DIST "車間距離設定表示
";
CM_ SG_ 801 EYE321_3_7_TJA "TJA機能有無
";
CM_ SG_ 801 EYE321_2_0_ACC_CANCEL_OR_CSTM "ｸﾙｺﾝｷｬﾝｾﾙ理由表示
";
CM_ SG_ 801 EYE321_2_4_ALK_CANCEL_OR_CSTM "ALKｷｬﾝｾﾙ理由表示
";
CM_ SG_ 801 EYE321_2_7_ALK_CANCEL_DISP_TYPE "ALKｷｬﾝｾﾙ表示種別
";
CM_ SG_ 801 EYE321_1_0_MSG_COUNTER "ﾒｯｾｰｼﾞｶｳﾝﾀ
";
CM_ SG_ 801 EYE321_1_4_PRECRASH_BRAKE_OFF "ﾌﾟﾘｸﾗｯｼｭﾌﾞﾚｰｷOFFｲﾝｼﾞｹｰﾀON flg
";
CM_ SG_ 801 EYE321_1_5_LANE_DEPARTURE_OFF "車線逸脱警報OFFｲﾝｼﾞｹｰﾀON flg
";
CM_ SG_ 801 EYE321_1_6_MET_AD_DRV_ASS "MET用高度運転支援有無ﾌﾗｸﾞ
";
CM_ SG_ 801 EYE321_1_7_ALC_EQUIP "ALC機能有無フラグ
";
CM_ SG_ 801 EYE321_0_0_CHECK_SUM "ﾁｪｯｸｻﾑ
";
CM_ SG_ 571 EYE23B_7_0_SND_MAC "送信用MAC
";
CM_ SG_ 571 EYE23B_4_4_RESET_FLG "ﾘｾｯﾄﾌﾗｸﾞ
";
CM_ SG_ 571 EYE23B_4_6_SNDMSG_CNT "送信用ﾒｯｾｰｼﾞｶｳﾝﾀ
";
CM_ SG_ 571 EYE23B_3_0_MSG_COUNTER "ﾒｯｾｰｼﾞｶｳﾝﾀ
";
CM_ SG_ 571 EYE23B_1_0_TRQDWN_FORCE_LIMIT "FMWｴﾝｼﾞﾝﾄﾙｸﾀﾞｳﾝ指示
";
CM_ SG_ 556 EYE22C_7_0_COMMANDSW_CC "ｸﾙｺﾝｽｲｯﾁ情報
";
CM_ SG_ 556 EYE22C_7_3_MODE_CC "ｸﾙｺﾝﾓｰﾄﾞﾌﾗｸﾞ
";
CM_ SG_ 556 EYE22C_7_4_CC_SETLAMP_INFO "ｸﾙｺﾝｾｯﾄﾗﾝﾌﾟ情報
";
CM_ SG_ 556 EYE22C_7_5_MSA_CNT_STS_EGI_HEV "MSA制御状態(EGI)
";
CM_ SG_ 556 EYE22C_7_6_SET_MSA "MSAｾｯﾄ状態(xCCSONLIM)
";
CM_ SG_ 556 EYE22C_7_7_SET_CC "ｸﾙｺﾝｾｯﾄ状態(xCCSON)
";
CM_ SG_ 556 EYE22C_5_0_TRQDWN_FORCE_LIMIT "FMWｴﾝｼﾞﾝﾄﾙｸﾀﾞｳﾝ指示 or 駆動力制限値
";
CM_ SG_ 556 EYE22C_4_0_BLIPPING_INHI "ﾌﾞﾘｯﾋﾟﾝｸﾞ禁止ﾌﾗｸﾞ
";
CM_ SG_ 556 EYE22C_4_4_ACTIVE_BRAKE_ACC "ﾌﾞﾚｰｷ制御実施ﾌﾗｸﾞ(ACCﾌﾞﾚｰｷ中のみ)
";
CM_ SG_ 556 EYE22C_4_5_REQ_FMW "FMW指示ﾌﾗｸﾞ
";
CM_ SG_ 556 EYE22C_4_6_FLG_BEFORE_RESERVE "停止保持予約前ﾌﾗｸﾞ
";
CM_ SG_ 556 EYE22C_4_7_REQ_TARGET_TORQUE "目標ﾄﾙｸ指示情報
";
CM_ SG_ 556 EYE22C_2_0_TGT_SPD_TRQ_FORCE "目標ﾄﾙｸ or 目標駆動力
";
CM_ SG_ 556 EYE22C_1_0_MSG_COUNTER "ﾒｯｾｰｼﾞｶｳﾝﾀ
";
CM_ SG_ 556 EYE22C_1_4_FLG_ADAPTIVE_CC "追従ｸﾙｺﾝﾌﾗｸﾞ
";
CM_ SG_ 556 EYE22C_1_5_MAIN_CC "ｸﾙｺﾝﾒｲﾝSW状態
";
CM_ SG_ 556 EYE22C_1_6_FLG_EYESIGHT_VERSION "ｱｲｻｲﾄﾊﾞｰｼﾞｮﾝﾌﾗｸﾞ
";
CM_ SG_ 556 EYE22C_1_7_FAIL_EYESIGHT "ｱｲｻｲﾄﾌｪｰﾙﾌﾗｸﾞ
";
CM_ SG_ 556 EYE22C_0_0_CHECK_SUM "ﾁｪｯｸｻﾑ
";
CM_ SG_ 546 EYE222_4_5_AEB_2ND_BRK_ACT "プリクラ 2次ブレーキ作動フラグ
";
CM_ SG_ 546 EYE222_3_5_REQ_TARGET_RPM_CVT "CVT目標回転数指示ﾌﾗｸﾞ
";
CM_ SG_ 546 EYE222_3_6_STATE_BRAKE_ACC "ACCﾌﾞﾚｰｷ中(ﾄﾞﾗｲﾊﾞOR制御)ﾌﾗｸﾞ(CVT用)
";
CM_ SG_ 546 EYE222_3_7_COOPERATE_EYE_ISS "ｱｲｻｲﾄ･ISS協調ﾌﾗｸﾞ
";
CM_ SG_ 546 EYE222_2_0_TARGET_RPM_CVT "CVT目標回転数
";
CM_ SG_ 546 EYE222_1_0_MSG_COUNTER "ﾒｯｾｰｼﾞｶｳﾝﾀ
";
CM_ SG_ 546 EYE222_1_4_MSA_CONT_STATUS_TCU "MSA制御状態(TCU)
";
CM_ SG_ 546 EYE222_1_7_FAIL_EYESIGHT "ｱｲｻｲﾄﾌｪｰﾙﾌﾗｸﾞ
";
CM_ SG_ 546 EYE222_0_0_CHECK_SUM "ﾁｪｯｸｻﾑ
";
CM_ SG_ 545 EYE221_7_0_COMMANDSW_CC "ｸﾙｺﾝｽｲｯﾁ情報
";
CM_ SG_ 545 EYE221_7_3_MODE_CC "ｸﾙｺﾝﾓｰﾄﾞﾌﾗｸﾞ
";
CM_ SG_ 545 EYE221_7_4_MSA_CNT_STS_EGI_HEV "MSA制御状態(EGI・HEV)
";
CM_ SG_ 545 EYE221_7_6_EQUIP_MSA "MSA有無フラグ
";
CM_ SG_ 545 EYE221_7_7_INHIBIT_FUEL_CUT "燃料ｶｯﾄ禁止要求ﾌﾗｸﾞ
";
CM_ SG_ 545 EYE221_5_0_TRQDWN_FORCE_LIMIT "FMWｴﾝｼﾞﾝﾄﾙｸﾀﾞｳﾝ指示 or 駆動力制限値
";
CM_ SG_ 545 EYE221_4_0_STATE_TRACKING "追尾ﾌﾗｸﾞ
";
CM_ SG_ 545 EYE221_4_1_STATE_LSF "LSFﾌﾗｸﾞ
";
CM_ SG_ 545 EYE221_4_2_FORCED_CANCEL_ACC "ACC強制ｷｬﾝｾﾙﾌﾗｸﾞ
";
CM_ SG_ 545 EYE221_4_3_BRAKE_TYPE "ﾌﾞﾚｰｷｼｽﾃﾑﾌﾗｸﾞ
";
CM_ SG_ 545 EYE221_4_4_ACTIVE_BRAKE_ACC "ﾌﾞﾚｰｷ制御実施ﾌﾗｸﾞ(ACCﾌﾞﾚｰｷ中のみ)
";
CM_ SG_ 545 EYE221_4_5_REQ_FMW "FMW指示ﾌﾗｸﾞ
";
CM_ SG_ 545 EYE221_4_6_FLG_BEFORE_RESERVE "停止保持予約前ﾌﾗｸﾞ
";
CM_ SG_ 545 EYE221_4_7_REQ_TARGET_TORQUE "目標ﾄﾙｸ指示情報
";
CM_ SG_ 545 EYE221_2_0_TGT_SPD_TRQ_FORCE "目標ﾄﾙｸ or 目標駆動力
";
CM_ SG_ 545 EYE221_1_0_MSG_COUNTER "ﾒｯｾｰｼﾞｶｳﾝﾀ
";
CM_ SG_ 545 EYE221_1_4_FLG_ADAPTIVE_CC "追従ｸﾙｺﾝﾌﾗｸﾞ
";
CM_ SG_ 545 EYE221_1_5_CANCEL_SW_INFO "ｸﾙｺﾝｷｬﾝｾﾙSW有無情報
";
CM_ SG_ 545 EYE221_1_6_FLG_EYESIGHT_VERSION "ｱｲｻｲﾄﾊﾞｰｼﾞｮﾝﾌﾗｸﾞ
";
CM_ SG_ 545 EYE221_1_7_FAIL_EYESIGHT "ｱｲｻｲﾄﾌｪｰﾙﾌﾗｸﾞ
";
CM_ SG_ 545 EYE221_0_0_CHECK_SUM "ﾁｪｯｸｻﾑ
";
CM_ SG_ 1352 EYE548_7_0_NETWORK_STATUS "ﾈｯﾄﾜｰｸｽﾃｰﾀｽ
";
CM_ SG_ 1746 LCT6D2_5_0_HDMAP_RELEASE_SEASON "3D高精度地図データリリース時期_季節
";
CM_ SG_ 1746 LCT6D2_5_4_HDMAP_RELEASE_REV "3D高精度地図データ改訂番号
";
CM_ SG_ 1746 LCT6D2_4_0_HDMAP_RELEASE_YEAR "3D高精度地図データリリース時期_西暦
";
CM_ SG_ 1746 LCT6D2_3_0_ISAMAP_RELEASE_SEASON "ISA地図データリリース時期（季節）
";
CM_ SG_ 1746 LCT6D2_3_4_ISAMAP_RELEASE_REV "ISA地図データリリース改定番号
";
CM_ SG_ 1746 LCT6D2_2_0_ISAMAP_RELEASE_YEAR "ISA地図データリリース時期（西暦）
";
CM_ SG_ 1746 LCT6D2_1_0_MSG_COUNTER "ﾒｯｾｰｼﾞｶｳﾝﾀ
";
CM_ SG_ 1746 LCT6D2_1_5_ADASMAP_FLAG "ADAS地図装備対象判定フラグ
";
CM_ SG_ 1746 LCT6D2_1_6_HDMAP_FLAG "3D高精度地図装備対象判定フラグ
";
CM_ SG_ 1746 LCT6D2_1_7_GSRISA_FLAG "GSRISA適用対象判定フラグ
";
CM_ SG_ 1746 LCT6D2_0_0_CHECK_SUM "ﾁｪｯｸｻﾑ
";
CM_ SG_ 1369 LCT559_0_0_NETWORK_STATUS "ﾈｯﾄﾜｰｸｽﾃｰﾀｽ
";
CM_ SG_ 1375 FCR55F_7_0_NETWORK_STATUS "ﾈｯﾄﾜｰｸｽﾃｰﾀｽ
";
CM_ SG_ 1374 FCR55E_7_0_NETWORK_STATUS "ﾈｯﾄﾜｰｸｽﾃｰﾀｽ
";
CM_ SG_ 916 ADAS394_2_2_STRGECU_FAIL "ステアリングヒータ 内部素子異常
";
CM_ SG_ 916 ADAS394_2_1_STRGHTR_OPEN_FAIL "ステアリングヒータ サーミスタ断線
";
CM_ SG_ 916 ADAS394_2_0_STRGHTR_SHORT_FAIL "ステアリングヒータ サーミスタ短絡
";
CM_ SG_ 916 ADAS394_1_7_COMM_STRGECU "統合ECU⇔STRG ECU通信状態
";
CM_ SG_ 916 ADAS394_1_4_STRGHTR_STATE "ステアリングヒータ作動状態
";
CM_ SG_ 916 ADAS394_1_0_MSG_COUNTER "ﾒｯｾｰｼﾞｶｳﾝﾀ
";
CM_ SG_ 916 ADAS394_0_0_CHECK_SUM "ﾁｪｯｸｻﾑ
";
CM_ SG_ 902 LCT386_2_4_HALT_TYPE "HALT要因コード
";
CM_ SG_ 902 LCT386_2_0_FAIL_TYPE "FAIL要因コード
";
CM_ SG_ 902 LCT386_1_5_HALT_FLAG "HALT（一時停止）フラグ
";
CM_ SG_ 902 LCT386_1_4_FAIL_FLAG "FAIL（故障）フラグ
";
CM_ SG_ 902 LCT386_1_0_COUNTER "メッセージカウンタ
";
CM_ SG_ 902 LCT386_0_0_CHECKSUM "チェックサム
";
CM_ SG_ 901 LCT385_6_0_VERTICAL_G "垂直G
";
CM_ SG_ 901 LCT385_4_0_SIDE_G "横G
";
CM_ SG_ 901 LCT385_2_0_FB_G "前後G
";
CM_ SG_ 901 LCT385_1_0_COUNTER "メッセージカウンタ
";
CM_ SG_ 901 LCT385_0_0_CHECKSUM "チェックサム
";
CM_ SG_ 900 LCT384_4_0_PITCH "ピッチ角
";
CM_ SG_ 900 LCT384_2_0_YAWRATE "ヨーレート
";
CM_ SG_ 900 LCT384_1_0_COUNTER "メッセージカウンタ
";
CM_ SG_ 900 LCT384_0_0_CHECKSUM "チェックサム
";
CM_ SG_ 899 LCT383_1_4_STOPSIGN "STOP標識フラグ
";
CM_ SG_ 899 LCT383_1_3_YIELDSIGN "YIELD標識フラグ
";
CM_ SG_ 899 LCT383_1_2_NOENTRY "NoEntryフラグ
";
CM_ SG_ 899 LCT383_1_1_GIVEWAY "GiveWay標識フラグ
";
CM_ SG_ 899 LCT383_1_0_COUNTER "メッセージカウンタ
";
CM_ SG_ 899 LCT383_0_0_CHECKSUM "チェックサム
";
CM_ SG_ 898 LCT382_5_6_FAILSTATUS "ナビの作動状態
";
CM_ SG_ 898 LCT382_5_4_ASSURANCE "自車位置信頼度
";
CM_ SG_ 898 LCT382_5_2_SPEEDUNIT "国速度単位
";
CM_ SG_ 898 LCT382_4_0_COUNTRYCODE "国情報
";
CM_ SG_ 898 LCT382_3_4_ROADLINKINFO "道路リンク情報
";
CM_ SG_ 898 LCT382_3_0_ROADCATEGORY "道路種別
";
CM_ SG_ 898 LCT382_2_4_AUXILIARYINFO "補助標識情報
";
CM_ SG_ 898 LCT382_1_7_SPEEDLIMITINFO "制限速度情報
";
CM_ SG_ 898 LCT382_1_4_SPEEDLIMITTYPE "制限速度タイプ
";
CM_ SG_ 898 LCT382_1_0_COUNTER "メッセージカウンタ
";
CM_ SG_ 898 LCT382_0_0_CHECKSUM "チェックサム
";
CM_ SG_ 2564481052 LCT18DAE01C_DIAG_DATA "ﾃﾞｰﾀ
";
CM_ SG_ 2564431072 DNT18DA1CE0_DIAG_DATA "ﾃﾞｰﾀ
";
CM_ SG_ 1702 ADAS6A6_7_0_UBI_INFO6 "テレマ保険情報6
";
CM_ SG_ 1702 ADAS6A6_6_0_UBI_INFO5 "テレマ保険情報5
";
CM_ SG_ 1702 ADAS6A6_5_0_UBI_INFO4 "テレマ保険情報4
";
CM_ SG_ 1702 ADAS6A6_4_0_UBI_INFO3 "テレマ保険情報3
";
CM_ SG_ 1702 ADAS6A6_3_0_UBI_INFO2 "テレマ保険情報2
";
CM_ SG_ 1702 ADAS6A6_2_0_UBI_INFO1 "テレマ保険情報1
";
CM_ SG_ 1702 ADAS6A6_1_0_MSGCOUNTER "メッセージカウンタ
";
CM_ SG_ 1702 ADAS6A6_0_0_CHECKSUM "チェックサム
";
CM_ SG_ 264 ADAS108_1_6_VRU_DET_STATE "VRU検知状態（歩行者ABG以外用)
";
CM_ SG_ 264 ADAS108_1_4_VRU_DET_STATE_ABG "VRU検知状態(歩行者ABG連携用）
";
CM_ SG_ 264 ADAS108_1_0_MSG_COUNTER "ﾒｯｾｰｼﾞｶｳﾝﾀ
";
CM_ SG_ 264 ADAS108_0_0_CHECK_SUM "ﾁｪｯｸｻﾑ
";
CM_ SG_ 2564481353 OBC18DAE149_DIAG_DATA_EXT7 "ﾃﾞｰﾀ
";
CM_ SG_ 2564481353 OBC18DAE149_DIAG_DATA_EXT6 "ﾃﾞｰﾀ
";
CM_ SG_ 2564481353 OBC18DAE149_DIAG_DATA_EXT5 "ﾃﾞｰﾀ
";
CM_ SG_ 2564481353 OBC18DAE149_DIAG_DATA_EXT4 "ﾃﾞｰﾀ
";
CM_ SG_ 2564481353 OBC18DAE149_DIAG_DATA_EXT3 "ﾃﾞｰﾀ
";
CM_ SG_ 2564481353 OBC18DAE149_DIAG_DATA_EXT2 "ﾃﾞｰﾀ
";
CM_ SG_ 2564481353 OBC18DAE149_DIAG_DATA_EXT1 "ﾃﾞｰﾀ
";
CM_ SG_ 2564481353 OBC18DAE149_DIAG_DATA "ﾃﾞｰﾀ
";
CM_ SG_ 2564442593 CECU18DA49E1_DIAG_DATA_EXT7 "ﾃﾞｰﾀ
";
CM_ SG_ 2564442593 CECU18DA49E1_DIAG_DATA_EXT6 "ﾃﾞｰﾀ
";
CM_ SG_ 2564442593 CECU18DA49E1_DIAG_DATA_EXT5 "ﾃﾞｰﾀ
";
CM_ SG_ 2564442593 CECU18DA49E1_DIAG_DATA_EXT4 "ﾃﾞｰﾀ
";
CM_ SG_ 2564442593 CECU18DA49E1_DIAG_DATA_EXT3 "ﾃﾞｰﾀ
";
CM_ SG_ 2564442593 CECU18DA49E1_DIAG_DATA_EXT2 "ﾃﾞｰﾀ
";
CM_ SG_ 2564442593 CECU18DA49E1_DIAG_DATA_EXT1 "ﾃﾞｰﾀ
";
CM_ SG_ 2564442593 CECU18DA49E1_DIAG_DATA "ﾃﾞｰﾀ
";
CM_ SG_ 1687 BEV697_31_0_BRMK71 "トラシュ用データ71
";
CM_ SG_ 1687 BEV697_30_0_BRMK70 "トラシュ用データ70
";
CM_ SG_ 1687 BEV697_29_0_BRMK69 "トラシュ用データ69
";
CM_ SG_ 1687 BEV697_28_0_BRMK68 "トラシュ用データ68
";
CM_ SG_ 1687 BEV697_27_0_BRMK67 "トラシュ用データ67
";
CM_ SG_ 1687 BEV697_26_0_BRMK66 "トラシュ用データ66
";
CM_ SG_ 1687 BEV697_25_0_BRMK65 "トラシュ用データ65
";
CM_ SG_ 1687 BEV697_24_0_BRMK64 "トラシュ用データ64
";
CM_ SG_ 1687 BEV697_23_0_BRMK63 "トラシュ用データ63
";
CM_ SG_ 1687 BEV697_22_0_BRMK62 "トラシュ用データ62
";
CM_ SG_ 1687 BEV697_21_0_BRMK61 "トラシュ用データ61
";
CM_ SG_ 1687 BEV697_20_0_BRMK60 "トラシュ用データ60
";
CM_ SG_ 1687 BEV697_19_0_BRMK59 "トラシュ用データ59
";
CM_ SG_ 1687 BEV697_18_0_BRMK58 "トラシュ用データ58
";
CM_ SG_ 1687 BEV697_17_0_BRMK57 "トラシュ用データ57
";
CM_ SG_ 1687 BEV697_16_0_BRMK56 "トラシュ用データ56
";
CM_ SG_ 1687 BEV697_15_0_BRMK55 "トラシュ用データ55
";
CM_ SG_ 1687 BEV697_14_0_BRMK54 "トラシュ用データ54
";
CM_ SG_ 1687 BEV697_13_0_BRMK53 "トラシュ用データ53
";
CM_ SG_ 1687 BEV697_12_0_BRMK52 "トラシュ用データ52
";
CM_ SG_ 1687 BEV697_11_0_BRMK51 "トラシュ用データ51
";
CM_ SG_ 1687 BEV697_10_0_BRMK50 "トラシュ用データ50
";
CM_ SG_ 1687 BEV697_9_0_BRMK49 "トラシュ用データ49
";
CM_ SG_ 1687 BEV697_8_0_BRMK48 "トラシュ用データ48
";
CM_ SG_ 1687 BEV697_7_0_BRMK47 "トラシュ用データ47
";
CM_ SG_ 1687 BEV697_6_0_BRMK46 "トラシュ用データ46
";
CM_ SG_ 1687 BEV697_5_0_BRMK45 "トラシュ用データ45
";
CM_ SG_ 1687 BEV697_4_0_BRMK44 "トラシュ用データ44
";
CM_ SG_ 1687 BEV697_3_0_BRMK43 "トラシュ用データ43
";
CM_ SG_ 1687 BEV697_2_0_BRMK42 "トラシュ用データ42
";
CM_ SG_ 1687 BEV697_1_0_BRMK41 "トラシュ用データ41
";
CM_ SG_ 1687 BEV697_0_0_BRMK40 "トラシュ用データ40
";
CM_ SG_ 1686 BEV696_31_0_BRMK39 "トラシュ用データ39
";
CM_ SG_ 1686 BEV696_30_0_BRMK38 "トラシュ用データ38
";
CM_ SG_ 1686 BEV696_29_0_BRMK37 "トラシュ用データ37
";
CM_ SG_ 1686 BEV696_28_0_BRMK36 "トラシュ用データ36
";
CM_ SG_ 1686 BEV696_27_0_BRMK35 "トラシュ用データ35
";
CM_ SG_ 1686 BEV696_26_0_BRMK34 "トラシュ用データ34
";
CM_ SG_ 1686 BEV696_25_0_BRMK33 "トラシュ用データ33
";
CM_ SG_ 1686 BEV696_24_0_BRMK32 "トラシュ用データ32
";
CM_ SG_ 1686 BEV696_23_0_BRMK31 "トラシュ用データ31
";
CM_ SG_ 1686 BEV696_22_0_BRMK30 "トラシュ用データ30
";
CM_ SG_ 1686 BEV696_21_0_BRMK29 "トラシュ用データ29
";
CM_ SG_ 1686 BEV696_20_0_BRMK28 "トラシュ用データ28
";
CM_ SG_ 1686 BEV696_19_0_BRMK27 "トラシュ用データ27
";
CM_ SG_ 1686 BEV696_18_0_BRMK26 "トラシュ用データ26
";
CM_ SG_ 1686 BEV696_17_0_BRMK25 "トラシュ用データ25
";
CM_ SG_ 1686 BEV696_16_0_BRMK24 "トラシュ用データ24
";
CM_ SG_ 1686 BEV696_15_0_BRMK23 "トラシュ用データ23
";
CM_ SG_ 1686 BEV696_14_0_BRMK22 "トラシュ用データ22
";
CM_ SG_ 1686 BEV696_13_0_BRMK21 "トラシュ用データ21
";
CM_ SG_ 1686 BEV696_12_0_BRMK20 "トラシュ用データ20
";
CM_ SG_ 1686 BEV696_11_0_BRMK19 "トラシュ用データ19
";
CM_ SG_ 1686 BEV696_10_0_BRMK18 "トラシュ用データ18
";
CM_ SG_ 1686 BEV696_9_0_BRMK17 "トラシュ用データ17
";
CM_ SG_ 1686 BEV696_8_0_BRMK16 "トラシュ用データ16
";
CM_ SG_ 1686 BEV696_7_0_BRMK15 "トラシュ用データ15
";
CM_ SG_ 1686 BEV696_6_0_BRMK14 "トラシュ用データ14
";
CM_ SG_ 1686 BEV696_5_0_BRMK13 "トラシュ用データ13
";
CM_ SG_ 1686 BEV696_4_0_BRMK12 "トラシュ用データ12
";
CM_ SG_ 1686 BEV696_3_0_BRMK11 "トラシュ用データ11
";
CM_ SG_ 1686 BEV696_2_0_BRMK10 "トラシュ用データ10
";
CM_ SG_ 1686 BEV696_1_0_BRMK9 "トラシュ用データ9
";
CM_ SG_ 1686 BEV696_0_0_BRMK8 "トラシュ用データ8
";
CM_ SG_ 1685 BEV695_7_0_BRMK7 "トラシュ用データ7
";
CM_ SG_ 1685 BEV695_6_0_BRMK6 "トラシュ用データ6
";
CM_ SG_ 1685 BEV695_5_0_BRMK5 "トラシュ用データ5
";
CM_ SG_ 1685 BEV695_4_0_BRMK4 "トラシュ用データ4
";
CM_ SG_ 1685 BEV695_3_0_BRMK3 "トラシュ用データ3
";
CM_ SG_ 1685 BEV695_2_0_BRMK2 "トラシュ用データ2
";
CM_ SG_ 1685 BEV695_1_0_BRMK1 "トラシュ用データ1
";
CM_ SG_ 1685 BEV695_0_0_BRMK0 "トラシュ用データ0
";
CM_ SG_ 1304 BEV518_1_4_ActiveWakeUpBit "Active Wakeup ﾌﾗｸﾞ
";
CM_ SG_ 1304 BEV518_0_0_SourceNodeID "送信元ID
";
CM_ SG_ 1541 BEV605_3_0_IGBHLDRQ "IGb保持要求
";
CM_ SG_ 1541 BEV605_3_2_ILK "インターロック検知信号
";
CM_ SG_ 1541 BEV605_3_3_HVSYSNG "高電圧システム使用不可
";
CM_ SG_ 1541 BEV605_2_0_E2E_COUNTER "E2Eカウンタ
";
CM_ SG_ 1541 BEV605_0_0_E2E_CRC "CRC
";
CM_ SG_ 1540 BEV604_2_0_E2E_COUNTER "E2Eカウンタ
";
CM_ SG_ 1540 BEV604_0_0_E2E_CRC "CRC
";
CM_ SG_ 1537 BEV601_2_0_IMBSTS "イモビ状態
";
CM_ SG_ 1537 BEV601_2_1_RDYNGSTS "ReadyON不可
";
CM_ SG_ 1537 BEV601_1_0_MSG_COUNTER "ﾒｯｾｰｼﾞｶｳﾝﾀ
";
CM_ SG_ 1537 BEV601_1_4_CDEVANS "衝突検知信号(EV用)アンサーバック
";
CM_ SG_ 1537 BEV601_0_0_CHECK_SUM "ﾁｪｯｸｻﾑ
";
CM_ SG_ 543 BEV21F_2_0_E2E_COUNTER "E2Eカウンタ
";
CM_ SG_ 543 BEV21F_0_0_E2E_CRC "CRC
";
CM_ SG_ 495 BEV1EF_6_0_RRMOTROT_BK "リアモータ回転数バックアップ状態
";
CM_ SG_ 495 BEV1EF_6_2_FRMOTROT_BK "フロントモータ回転数バックアップ状態
";
CM_ SG_ 495 BEV1EF_4_0_RRMOTROT "リアモータ回転数
";
CM_ SG_ 495 BEV1EF_2_0_FRMOTROT "フロントモータ回転数
";
CM_ SG_ 495 BEV1EF_1_0_MSG_COUNTER "ﾒｯｾｰｼﾞｶｳﾝﾀ
";
CM_ SG_ 495 BEV1EF_0_0_CHECK_SUM "ﾁｪｯｸｻﾑ
";
CM_ SG_ 494 BEV1EE_3_0_VIN_DATA "VIN Data
";
CM_ SG_ 494 BEV1EE_2_0_VIN_BYTE_NO "VIN ByteNo
";
CM_ SG_ 494 BEV1EE_1_0_MSG_COUNTER "ﾒｯｾｰｼﾞｶｳﾝﾀ
";
CM_ SG_ 494 BEV1EE_0_0_CHECK_SUM "ﾁｪｯｸｻﾑ
";
CM_ SG_ 267 BEV10B_6_7_SPEC8 "特殊分母8
";
CM_ SG_ 267 BEV10B_6_6_SPEC7 "特殊分母7
";
CM_ SG_ 267 BEV10B_6_5_SPEC6 "特殊分母6
";
CM_ SG_ 267 BEV10B_6_4_SPEC5 "特殊分母5
";
CM_ SG_ 267 BEV10B_6_3_SPEC4 "特殊分母4
";
CM_ SG_ 267 BEV10B_6_2_SPEC3 "特殊分母3
";
CM_ SG_ 267 BEV10B_6_1_SPEC2 "特殊分母2
";
CM_ SG_ 267 BEV10B_6_0_SPEC1 "特殊分母1
";
CM_ SG_ 267 BEV10B_5_2_DENO "一般分母
";
CM_ SG_ 267 BEV10B_5_1_PROHIBIT_INC "分子分母インクリメント禁止フラグ
";
CM_ SG_ 267 BEV10B_5_0_PERMIT_INC "一般分母インクリメント許可フラグ
";
CM_ SG_ 267 BEV10B_4_0_DCCNT "ドライビングサイクルカウンタ
";
CM_ SG_ 267 BEV10B_3_2_OBDRDY "OBD Ready状態
";
CM_ SG_ 267 BEV10B_3_0_DRVRDY "運転可能表示状態
";
CM_ SG_ 267 BEV10B_1_0_MSG_COUNTER "ﾒｯｾｰｼﾞｶｳﾝﾀ
";
CM_ SG_ 267 BEV10B_0_0_CHECK_SUM "ﾁｪｯｸｻﾑ
";
CM_ SG_ 117 BEV075_1_0_MSG_COUNTER "ﾒｯｾｰｼﾞｶｳﾝﾀ
";
CM_ SG_ 117 BEV075_0_0_CHECK_SUM "ﾁｪｯｸｻﾑ
";
CM_ SG_ 116 BEV074_7_0_LVPWRDWN "12V電力抑制信号
";
CM_ SG_ 116 BEV074_7_6_CHRCONSTA "充電コネクタ接続状態
";
CM_ SG_ 116 BEV074_7_7_VEHICLE_IGN "車両イグニッション情報
";
CM_ SG_ 116 BEV074_6_0_EV_CAU "EVコーション点灯要求
";
CM_ SG_ 116 BEV074_6_2_BEV_OBD_CAU "BEV_OBD警告灯点灯要求
";
CM_ SG_ 116 BEV074_6_5_SIDRIVE_DISP "SIドライブモード表示情報
";
CM_ SG_ 116 BEV074_5_0_ACCHG_STATE "AC充電状態
";
CM_ SG_ 116 BEV074_5_1_DCCHG_STATE "DC充電状態
";
CM_ SG_ 116 BEV074_5_2_RANGE_DG "シフト故障状態
";
CM_ SG_ 116 BEV074_5_3_ACCP_DG "アクセル故障状態
";
CM_ SG_ 116 BEV074_5_4_REZ_SPD_BK "レゾルバ車速バックアップ状態
";
CM_ SG_ 116 BEV074_5_6_OBDRDY "OBD Ready状態
";
CM_ SG_ 116 BEV074_5_7_FHVB "高電圧バッテリ異常
";
CM_ SG_ 116 BEV074_3_0_RANGE_POS "現在レンジ位置情報
";
CM_ SG_ 116 BEV074_3_3_DRVRDY "運転可能表示状態
";
CM_ SG_ 116 BEV074_3_5_HVSYSTS "高電圧システムステータス
";
CM_ SG_ 116 BEV074_3_7_REZ_SPD_GL "レゾルバ車速_GL
";
CM_ SG_ 116 BEV074_2_0_ACCP_USR "アクセル開度(ユーザー)
";
CM_ SG_ 116 BEV074_1_0_MSG_COUNTER "ﾒｯｾｰｼﾞｶｳﾝﾀ
";
CM_ SG_ 116 BEV074_1_4_RANGE_DG2 "シフト故障状態2
";
CM_ SG_ 116 BEV074_1_5_REZ_SPD_BK "レゾルバ車速バックアップ状態
";
CM_ SG_ 116 BEV074_0_0_CHECK_SUM "ﾁｪｯｸｻﾑ
";
CM_ SG_ 2041 ABG7F9_7_0_DATA "ﾃﾞｰﾀ
";
CM_ SG_ 2033 ABG7F1_7_0_DATA "ﾃﾞｰﾀ
";
CM_ SG_ 1803 VDC70B_7_0_DATA "ﾃﾞｰﾀ
";
CM_ SG_ 1802 VDC70A_7_0_DATA "ﾃﾞｰﾀ
";
CM_ SG_ 2564481410 FCRL18DAE182_DIAG_DATA_EXT7 "ﾃﾞｰﾀ
";
CM_ SG_ 2564481410 FCRL18DAE182_DIAG_DATA_EXT6 "ﾃﾞｰﾀ
";
CM_ SG_ 2564481410 FCRL18DAE182_DIAG_DATA_EXT5 "ﾃﾞｰﾀ
";
CM_ SG_ 2564481410 FCRL18DAE182_DIAG_DATA_EXT4 "ﾃﾞｰﾀ
";
CM_ SG_ 2564481410 FCRL18DAE182_DIAG_DATA_EXT3 "ﾃﾞｰﾀ
";
CM_ SG_ 2564481410 FCRL18DAE182_DIAG_DATA_EXT2 "ﾃﾞｰﾀ
";
CM_ SG_ 2564481410 FCRL18DAE182_DIAG_DATA_EXT1 "ﾃﾞｰﾀ
";
CM_ SG_ 2564481410 FCRL18DAE182_DIAG_DATA "ﾃﾞｰﾀ
";
CM_ SG_ 2564457185 CECU18DA82E1_DIAG_DATA_EXT7 "ﾃﾞｰﾀ
";
CM_ SG_ 2564457185 CECU18DA82E1_DIAG_DATA_EXT6 "ﾃﾞｰﾀ
";
CM_ SG_ 2564457185 CECU18DA82E1_DIAG_DATA_EXT5 "ﾃﾞｰﾀ
";
CM_ SG_ 2564457185 CECU18DA82E1_DIAG_DATA_EXT4 "ﾃﾞｰﾀ
";
CM_ SG_ 2564457185 CECU18DA82E1_DIAG_DATA_EXT3 "ﾃﾞｰﾀ
";
CM_ SG_ 2564457185 CECU18DA82E1_DIAG_DATA_EXT2 "ﾃﾞｰﾀ
";
CM_ SG_ 2564457185 CECU18DA82E1_DIAG_DATA_EXT1 "ﾃﾞｰﾀ
";
CM_ SG_ 2564457185 CECU18DA82E1_DIAG_DATA "ﾃﾞｰﾀ
";
CM_ SG_ 2564481411 FCRR18DAE183_DIAG_DATA_EXT7 "ﾃﾞｰﾀ
";
CM_ SG_ 2564481411 FCRR18DAE183_DIAG_DATA_EXT6 "ﾃﾞｰﾀ
";
CM_ SG_ 2564481411 FCRR18DAE183_DIAG_DATA_EXT5 "ﾃﾞｰﾀ
";
CM_ SG_ 2564481411 FCRR18DAE183_DIAG_DATA_EXT4 "ﾃﾞｰﾀ
";
CM_ SG_ 2564481411 FCRR18DAE183_DIAG_DATA_EXT3 "ﾃﾞｰﾀ
";
CM_ SG_ 2564481411 FCRR18DAE183_DIAG_DATA_EXT2 "ﾃﾞｰﾀ
";
CM_ SG_ 2564481411 FCRR18DAE183_DIAG_DATA_EXT1 "ﾃﾞｰﾀ
";
CM_ SG_ 2564481411 FCRR18DAE183_DIAG_DATA "ﾃﾞｰﾀ
";
CM_ SG_ 2564457441 CECU18DA83E1_DIAG_DATA_EXT7 "ﾃﾞｰﾀ
";
CM_ SG_ 2564457441 CECU18DA83E1_DIAG_DATA_EXT6 "ﾃﾞｰﾀ
";
CM_ SG_ 2564457441 CECU18DA83E1_DIAG_DATA_EXT5 "ﾃﾞｰﾀ
";
CM_ SG_ 2564457441 CECU18DA83E1_DIAG_DATA_EXT4 "ﾃﾞｰﾀ
";
CM_ SG_ 2564457441 CECU18DA83E1_DIAG_DATA_EXT3 "ﾃﾞｰﾀ
";
CM_ SG_ 2564457441 CECU18DA83E1_DIAG_DATA_EXT2 "ﾃﾞｰﾀ
";
CM_ SG_ 2564457441 CECU18DA83E1_DIAG_DATA_EXT1 "ﾃﾞｰﾀ
";
CM_ SG_ 2564457441 CECU18DA83E1_DIAG_DATA "ﾃﾞｰﾀ
";
CM_ SG_ 2564481286 PBW18DAE106_DIAG_DATA_EXT7 "ﾃﾞｰﾀ
";
CM_ SG_ 2564481286 PBW18DAE106_DIAG_DATA_EXT6 "ﾃﾞｰﾀ
";
CM_ SG_ 2564481286 PBW18DAE106_DIAG_DATA_EXT5 "ﾃﾞｰﾀ
";
CM_ SG_ 2564481286 PBW18DAE106_DIAG_DATA_EXT4 "ﾃﾞｰﾀ
";
CM_ SG_ 2564481286 PBW18DAE106_DIAG_DATA_EXT3 "ﾃﾞｰﾀ
";
CM_ SG_ 2564481286 PBW18DAE106_DIAG_DATA_EXT2 "ﾃﾞｰﾀ
";
CM_ SG_ 2564481286 PBW18DAE106_DIAG_DATA_EXT1 "ﾃﾞｰﾀ
";
CM_ SG_ 2564481286 PBW18DAE106_DIAG_DATA "ﾃﾞｰﾀ
";
CM_ SG_ 2564425441 CECU18DA06E1_DIAG_DATA_EXT7 "ﾃﾞｰﾀ
";
CM_ SG_ 2564425441 CECU18DA06E1_DIAG_DATA_EXT6 "ﾃﾞｰﾀ
";
CM_ SG_ 2564425441 CECU18DA06E1_DIAG_DATA_EXT5 "ﾃﾞｰﾀ
";
CM_ SG_ 2564425441 CECU18DA06E1_DIAG_DATA_EXT4 "ﾃﾞｰﾀ
";
CM_ SG_ 2564425441 CECU18DA06E1_DIAG_DATA_EXT3 "ﾃﾞｰﾀ
";
CM_ SG_ 2564425441 CECU18DA06E1_DIAG_DATA_EXT2 "ﾃﾞｰﾀ
";
CM_ SG_ 2564425441 CECU18DA06E1_DIAG_DATA_EXT1 "ﾃﾞｰﾀ
";
CM_ SG_ 2564425441 CECU18DA06E1_DIAG_DATA "ﾃﾞｰﾀ
";
CM_ SG_ 2564481285 SFT18DAE105_DIAG_DATA_EXT7 "ﾃﾞｰﾀ
";
CM_ SG_ 2564481285 SFT18DAE105_DIAG_DATA_EXT6 "ﾃﾞｰﾀ
";
CM_ SG_ 2564481285 SFT18DAE105_DIAG_DATA_EXT5 "ﾃﾞｰﾀ
";
CM_ SG_ 2564481285 SFT18DAE105_DIAG_DATA_EXT4 "ﾃﾞｰﾀ
";
CM_ SG_ 2564481285 SFT18DAE105_DIAG_DATA_EXT3 "ﾃﾞｰﾀ
";
CM_ SG_ 2564481285 SFT18DAE105_DIAG_DATA_EXT2 "ﾃﾞｰﾀ
";
CM_ SG_ 2564481285 SFT18DAE105_DIAG_DATA_EXT1 "ﾃﾞｰﾀ
";
CM_ SG_ 2564481285 SFT18DAE105_DIAG_DATA "ﾃﾞｰﾀ
";
CM_ SG_ 2564425185 CECU18DA05E1_DIAG_DATA_EXT7 "ﾃﾞｰﾀ
";
CM_ SG_ 2564425185 CECU18DA05E1_DIAG_DATA_EXT6 "ﾃﾞｰﾀ
";
CM_ SG_ 2564425185 CECU18DA05E1_DIAG_DATA_EXT5 "ﾃﾞｰﾀ
";
CM_ SG_ 2564425185 CECU18DA05E1_DIAG_DATA_EXT4 "ﾃﾞｰﾀ
";
CM_ SG_ 2564425185 CECU18DA05E1_DIAG_DATA_EXT3 "ﾃﾞｰﾀ
";
CM_ SG_ 2564425185 CECU18DA05E1_DIAG_DATA_EXT2 "ﾃﾞｰﾀ
";
CM_ SG_ 2564425185 CECU18DA05E1_DIAG_DATA_EXT1 "ﾃﾞｰﾀ
";
CM_ SG_ 2564425185 CECU18DA05E1_DIAG_DATA "ﾃﾞｰﾀ
";
CM_ SG_ 2564481372 MGR18DAE15C_DIAG_DATA_EXT7 "ﾃﾞｰﾀ
";
CM_ SG_ 2564481372 MGR18DAE15C_DIAG_DATA_EXT6 "ﾃﾞｰﾀ
";
CM_ SG_ 2564481372 MGR18DAE15C_DIAG_DATA_EXT5 "ﾃﾞｰﾀ
";
CM_ SG_ 2564481372 MGR18DAE15C_DIAG_DATA_EXT4 "ﾃﾞｰﾀ
";
CM_ SG_ 2564481372 MGR18DAE15C_DIAG_DATA_EXT3 "ﾃﾞｰﾀ
";
CM_ SG_ 2564481372 MGR18DAE15C_DIAG_DATA_EXT2 "ﾃﾞｰﾀ
";
CM_ SG_ 2564481372 MGR18DAE15C_DIAG_DATA_EXT1 "ﾃﾞｰﾀ
";
CM_ SG_ 2564481372 MGR18DAE15C_DIAG_DATA "ﾃﾞｰﾀ
";
CM_ SG_ 2564447457 CECU18DA5CE1_DIAG_DATA_EXT7 "ﾃﾞｰﾀ
";
CM_ SG_ 2564447457 CECU18DA5CE1_DIAG_DATA_EXT6 "ﾃﾞｰﾀ
";
CM_ SG_ 2564447457 CECU18DA5CE1_DIAG_DATA_EXT5 "ﾃﾞｰﾀ
";
CM_ SG_ 2564447457 CECU18DA5CE1_DIAG_DATA_EXT4 "ﾃﾞｰﾀ
";
CM_ SG_ 2564447457 CECU18DA5CE1_DIAG_DATA_EXT3 "ﾃﾞｰﾀ
";
CM_ SG_ 2564447457 CECU18DA5CE1_DIAG_DATA_EXT2 "ﾃﾞｰﾀ
";
CM_ SG_ 2564447457 CECU18DA5CE1_DIAG_DATA_EXT1 "ﾃﾞｰﾀ
";
CM_ SG_ 2564447457 CECU18DA5CE1_DIAG_DATA "ﾃﾞｰﾀ
";
CM_ SG_ 2564481371 MGF18DAE15B_DIAG_DATA_EXT7 "ﾃﾞｰﾀ
";
CM_ SG_ 2564481371 MGF18DAE15B_DIAG_DATA_EXT6 "ﾃﾞｰﾀ
";
CM_ SG_ 2564481371 MGF18DAE15B_DIAG_DATA_EXT5 "ﾃﾞｰﾀ
";
CM_ SG_ 2564481371 MGF18DAE15B_DIAG_DATA_EXT4 "ﾃﾞｰﾀ
";
CM_ SG_ 2564481371 MGF18DAE15B_DIAG_DATA_EXT3 "ﾃﾞｰﾀ
";
CM_ SG_ 2564481371 MGF18DAE15B_DIAG_DATA_EXT2 "ﾃﾞｰﾀ
";
CM_ SG_ 2564481371 MGF18DAE15B_DIAG_DATA_EXT1 "ﾃﾞｰﾀ
";
CM_ SG_ 2564481371 MGF18DAE15B_DIAG_DATA "ﾃﾞｰﾀ
";
CM_ SG_ 2564447201 CECU18DA5BE1_DIAG_DATA_EXT7 "ﾃﾞｰﾀ
";
CM_ SG_ 2564447201 CECU18DA5BE1_DIAG_DATA_EXT6 "ﾃﾞｰﾀ
";
CM_ SG_ 2564447201 CECU18DA5BE1_DIAG_DATA_EXT5 "ﾃﾞｰﾀ
";
CM_ SG_ 2564447201 CECU18DA5BE1_DIAG_DATA_EXT4 "ﾃﾞｰﾀ
";
CM_ SG_ 2564447201 CECU18DA5BE1_DIAG_DATA_EXT3 "ﾃﾞｰﾀ
";
CM_ SG_ 2564447201 CECU18DA5BE1_DIAG_DATA_EXT2 "ﾃﾞｰﾀ
";
CM_ SG_ 2564447201 CECU18DA5BE1_DIAG_DATA_EXT1 "ﾃﾞｰﾀ
";
CM_ SG_ 2564447201 CECU18DA5BE1_DIAG_DATA "ﾃﾞｰﾀ
";
CM_ SG_ 2564481476 BMU18DAE1C4_DIAG_DATA_EXT7 "ﾃﾞｰﾀ
";
CM_ SG_ 2564481476 BMU18DAE1C4_DIAG_DATA_EXT6 "ﾃﾞｰﾀ
";
CM_ SG_ 2564481476 BMU18DAE1C4_DIAG_DATA_EXT5 "ﾃﾞｰﾀ
";
CM_ SG_ 2564481476 BMU18DAE1C4_DIAG_DATA_EXT4 "ﾃﾞｰﾀ
";
CM_ SG_ 2564481476 BMU18DAE1C4_DIAG_DATA_EXT3 "ﾃﾞｰﾀ
";
CM_ SG_ 2564481476 BMU18DAE1C4_DIAG_DATA_EXT2 "ﾃﾞｰﾀ
";
CM_ SG_ 2564481476 BMU18DAE1C4_DIAG_DATA_EXT1 "ﾃﾞｰﾀ
";
CM_ SG_ 2564481476 BMU18DAE1C4_DIAG_DATA "ﾃﾞｰﾀ
";
CM_ SG_ 2564474081 CECU18DAC4E1_DIAG_DATA_EXT7 "ﾃﾞｰﾀ
";
CM_ SG_ 2564474081 CECU18DAC4E1_DIAG_DATA_EXT6 "ﾃﾞｰﾀ
";
CM_ SG_ 2564474081 CECU18DAC4E1_DIAG_DATA_EXT5 "ﾃﾞｰﾀ
";
CM_ SG_ 2564474081 CECU18DAC4E1_DIAG_DATA_EXT4 "ﾃﾞｰﾀ
";
CM_ SG_ 2564474081 CECU18DAC4E1_DIAG_DATA_EXT3 "ﾃﾞｰﾀ
";
CM_ SG_ 2564474081 CECU18DAC4E1_DIAG_DATA_EXT2 "ﾃﾞｰﾀ
";
CM_ SG_ 2564474081 CECU18DAC4E1_DIAG_DATA_EXT1 "ﾃﾞｰﾀ
";
CM_ SG_ 2564474081 CECU18DAC4E1_DIAG_DATA "ﾃﾞｰﾀ
";
CM_ SG_ 2564481215 SCA18DAE0BF_DIAG_DATA_EXT7 "ﾃﾞｰﾀ
";
CM_ SG_ 2564481215 SCA18DAE0BF_DIAG_DATA_EXT6 "ﾃﾞｰﾀ
";
CM_ SG_ 2564481215 SCA18DAE0BF_DIAG_DATA_EXT5 "ﾃﾞｰﾀ
";
CM_ SG_ 2564481215 SCA18DAE0BF_DIAG_DATA_EXT4 "ﾃﾞｰﾀ
";
CM_ SG_ 2564481215 SCA18DAE0BF_DIAG_DATA_EXT3 "ﾃﾞｰﾀ
";
CM_ SG_ 2564481215 SCA18DAE0BF_DIAG_DATA_EXT2 "ﾃﾞｰﾀ
";
CM_ SG_ 2564481215 SCA18DAE0BF_DIAG_DATA_EXT1 "ﾃﾞｰﾀ
";
CM_ SG_ 2564481215 SCA18DAE0BF_DIAG_DATA "ﾃﾞｰﾀ
";
CM_ SG_ 2564472800 DNT18DABFE0_DIAG_DATA_EXT7 "ﾃﾞｰﾀ
";
CM_ SG_ 2564472800 DNT18DABFE0_DIAG_DATA_EXT6 "ﾃﾞｰﾀ
";
CM_ SG_ 2564472800 DNT18DABFE0_DIAG_DATA_EXT5 "ﾃﾞｰﾀ
";
CM_ SG_ 2564472800 DNT18DABFE0_DIAG_DATA_EXT4 "ﾃﾞｰﾀ
";
CM_ SG_ 2564472800 DNT18DABFE0_DIAG_DATA_EXT3 "ﾃﾞｰﾀ
";
CM_ SG_ 2564472800 DNT18DABFE0_DIAG_DATA_EXT2 "ﾃﾞｰﾀ
";
CM_ SG_ 2564472800 DNT18DABFE0_DIAG_DATA_EXT1 "ﾃﾞｰﾀ
";
CM_ SG_ 2564472800 DNT18DABFE0_DIAG_DATA "ﾃﾞｰﾀ
";
CM_ SG_ 2564481216 ADAS18DAE0C0_DIAG_DATA_EXT7 "ﾃﾞｰﾀ
";
CM_ SG_ 2564481216 ADAS18DAE0C0_DIAG_DATA_EXT6 "ﾃﾞｰﾀ
";
CM_ SG_ 2564481216 ADAS18DAE0C0_DIAG_DATA_EXT5 "ﾃﾞｰﾀ
";
CM_ SG_ 2564481216 ADAS18DAE0C0_DIAG_DATA_EXT4 "ﾃﾞｰﾀ
";
CM_ SG_ 2564481216 ADAS18DAE0C0_DIAG_DATA_EXT3 "ﾃﾞｰﾀ
";
CM_ SG_ 2564481216 ADAS18DAE0C0_DIAG_DATA_EXT2 "ﾃﾞｰﾀ
";
CM_ SG_ 2564481216 ADAS18DAE0C0_DIAG_DATA_EXT1 "ﾃﾞｰﾀ
";
CM_ SG_ 2564481216 ADAS18DAE0C0_DIAG_DATA "ﾃﾞｰﾀ
";
CM_ SG_ 2564473056 DNT18DAC0E0_DIAG_DATA_EXT7 "ﾃﾞｰﾀ
";
CM_ SG_ 2564473056 DNT18DAC0E0_DIAG_DATA_EXT6 "ﾃﾞｰﾀ
";
CM_ SG_ 2564473056 DNT18DAC0E0_DIAG_DATA_EXT5 "ﾃﾞｰﾀ
";
CM_ SG_ 2564473056 DNT18DAC0E0_DIAG_DATA_EXT4 "ﾃﾞｰﾀ
";
CM_ SG_ 2564473056 DNT18DAC0E0_DIAG_DATA_EXT3 "ﾃﾞｰﾀ
";
CM_ SG_ 2564473056 DNT18DAC0E0_DIAG_DATA_EXT2 "ﾃﾞｰﾀ
";
CM_ SG_ 2564473056 DNT18DAC0E0_DIAG_DATA_EXT1 "ﾃﾞｰﾀ
";
CM_ SG_ 2564473056 DNT18DAC0E0_DIAG_DATA "ﾃﾞｰﾀ
";
CM_ SG_ 2564481472 ADAS18DAE1C0_DIAG_DATA_EXT7 "ﾃﾞｰﾀ
";
CM_ SG_ 2564481472 ADAS18DAE1C0_DIAG_DATA_EXT6 "ﾃﾞｰﾀ
";
CM_ SG_ 2564481472 ADAS18DAE1C0_DIAG_DATA_EXT5 "ﾃﾞｰﾀ
";
CM_ SG_ 2564481472 ADAS18DAE1C0_DIAG_DATA_EXT4 "ﾃﾞｰﾀ
";
CM_ SG_ 2564481472 ADAS18DAE1C0_DIAG_DATA_EXT3 "ﾃﾞｰﾀ
";
CM_ SG_ 2564481472 ADAS18DAE1C0_DIAG_DATA_EXT2 "ﾃﾞｰﾀ
";
CM_ SG_ 2564481472 ADAS18DAE1C0_DIAG_DATA_EXT1 "ﾃﾞｰﾀ
";
CM_ SG_ 2564481472 ADAS18DAE1C0_DIAG_DATA "ﾃﾞｰﾀ
";
CM_ SG_ 2564473057 CECU18DAC0E1_DIAG_DATA_EXT7 "ﾃﾞｰﾀ
";
CM_ SG_ 2564473057 CECU18DAC0E1_DIAG_DATA_EXT6 "ﾃﾞｰﾀ
";
CM_ SG_ 2564473057 CECU18DAC0E1_DIAG_DATA_EXT5 "ﾃﾞｰﾀ
";
CM_ SG_ 2564473057 CECU18DAC0E1_DIAG_DATA_EXT4 "ﾃﾞｰﾀ
";
CM_ SG_ 2564473057 CECU18DAC0E1_DIAG_DATA_EXT3 "ﾃﾞｰﾀ
";
CM_ SG_ 2564473057 CECU18DAC0E1_DIAG_DATA_EXT2 "ﾃﾞｰﾀ
";
CM_ SG_ 2564473057 CECU18DAC0E1_DIAG_DATA_EXT1 "ﾃﾞｰﾀ
";
CM_ SG_ 2564473057 CECU18DAC0E1_DIAG_DATA "ﾃﾞｰﾀ
";
CM_ SG_ 2564487618 IAVAS18DAF9C2_DIAG_DATA "ﾃﾞｰﾀ
";
CM_ SG_ 2564481474 IAVAS18DAE1C2_DIAG_DATA_EXT7 "ﾃﾞｰﾀ
";
CM_ SG_ 2564481474 IAVAS18DAE1C2_DIAG_DATA_EXT6 "ﾃﾞｰﾀ
";
CM_ SG_ 2564481474 IAVAS18DAE1C2_DIAG_DATA_EXT5 "ﾃﾞｰﾀ
";
CM_ SG_ 2564481474 IAVAS18DAE1C2_DIAG_DATA_EXT4 "ﾃﾞｰﾀ
";
CM_ SG_ 2564481474 IAVAS18DAE1C2_DIAG_DATA_EXT3 "ﾃﾞｰﾀ
";
CM_ SG_ 2564481474 IAVAS18DAE1C2_DIAG_DATA_EXT2 "ﾃﾞｰﾀ
";
CM_ SG_ 2564481474 IAVAS18DAE1C2_DIAG_DATA_EXT1 "ﾃﾞｰﾀ
";
CM_ SG_ 2564481474 IAVAS18DAE1C2_DIAG_DATA "ﾃﾞｰﾀ
";
CM_ SG_ 2564473569 CECU18DAC2E1_DIAG_DATA_EXT7 "ﾃﾞｰﾀ
";
CM_ SG_ 2564473569 CECU18DAC2E1_DIAG_DATA_EXT6 "ﾃﾞｰﾀ
";
CM_ SG_ 2564473569 CECU18DAC2E1_DIAG_DATA_EXT5 "ﾃﾞｰﾀ
";
CM_ SG_ 2564473569 CECU18DAC2E1_DIAG_DATA_EXT4 "ﾃﾞｰﾀ
";
CM_ SG_ 2564473569 CECU18DAC2E1_DIAG_DATA_EXT3 "ﾃﾞｰﾀ
";
CM_ SG_ 2564473569 CECU18DAC2E1_DIAG_DATA_EXT2 "ﾃﾞｰﾀ
";
CM_ SG_ 2564473569 CECU18DAC2E1_DIAG_DATA_EXT1 "ﾃﾞｰﾀ
";
CM_ SG_ 2564473569 CECU18DAC2E1_DIAG_DATA "ﾃﾞｰﾀ
";
CM_ SG_ 2564481218 IAVAS18DAE0C2_DIAG_DATA "ﾃﾞｰﾀ
";
CM_ SG_ 2564473568 DNT18DAC2E0_DIAG_DATA "ﾃﾞｰﾀ
";
BA_DEF_  "DBCConverterVersion" STRING ;
BA_DEF_  "Manufacturer" STRING ;
BA_DEF_  "BusType" STRING ;
BA_DEF_ BU_  "DiagNode" ENUM  "No","Yes";
BA_DEF_ BU_  "ILUsed" ENUM  "No","Yes";
BA_DEF_ BU_  "NodeLayerModules" STRING ;
BA_DEF_ SG_  "Fhi_SignalComment" STRING ;
BA_DEF_ SG_  "GenSigInactiveValue" INT 0 10000;
BA_DEF_ SG_  "GenSigStartValue" FLOAT 0 100000000000;
BA_DEF_ SG_  "GenSigSendType" ENUM  "Cyclic","OnWrite","OnWriteWithRepetition","OnChange","OnChangeWithRepetition","IfActive","IfActiveWithRepetition","NoSigSendType";
BA_DEF_ BO_  "MsgRoutingId" STRING ;
BA_DEF_ BO_  "DiagResponse" ENUM  "No","Yes";
BA_DEF_ BO_  "DiagRequest" ENUM  "No","Yes";
BA_DEF_ BO_  "DiagState" ENUM  "No","Yes";
BA_DEF_ BO_  "GenMsgILSupport" ENUM  "No","Yes";
BA_DEF_ BO_  "GenMsgNrOfRepetition" INT 0 999999;
BA_DEF_ BO_  "GenMsgDelayTime" INT 0 1000;
BA_DEF_ BO_  "GenMsgCycleTimeFast" INT 0 10000;
BA_DEF_ BO_  "GenMsgCycleTime" INT 0 10000;
BA_DEF_ BO_  "GenMsgSendType" ENUM  "Cyclic","NotUsed","NotUsed","NotUsed","NotUsed","Cyclic","NotUsed","IfActive","NoMsgSendType";
BA_DEF_ BO_  "CANFD_BRS" ENUM  "0","1";
BA_DEF_ BO_  "VFrameFormat" ENUM  "StandardCAN","ExtendedCAN","reserved","reserved","reserved","reserved","reserved","reserved","reserved","reserved","reserved","reserved","reserved","reserved","StandardCAN_FD","ExtendedCAN_FD";
BA_DEF_DEF_  "DBCConverterVersion" "2.0";
BA_DEF_DEF_  "Manufacturer" "FHI";
BA_DEF_DEF_  "BusType" "";
BA_DEF_DEF_  "DiagNode" "No";
BA_DEF_DEF_  "ILUsed" "Yes";
BA_DEF_DEF_  "NodeLayerModules" "CANoeILNLSubaru.dll";
BA_DEF_DEF_  "Fhi_SignalComment" "";
BA_DEF_DEF_  "GenSigInactiveValue" 0;
BA_DEF_DEF_  "GenSigStartValue" 0;
BA_DEF_DEF_  "GenSigSendType" "NoSigSendType";
BA_DEF_DEF_  "MsgRoutingId" "";
BA_DEF_DEF_  "DiagResponse" "No";
BA_DEF_DEF_  "DiagRequest" "No";
BA_DEF_DEF_  "DiagState" "No";
BA_DEF_DEF_  "GenMsgILSupport" "Yes";
BA_DEF_DEF_  "GenMsgNrOfRepetition" 0;
BA_DEF_DEF_  "GenMsgDelayTime" 0;
BA_DEF_DEF_  "GenMsgCycleTimeFast" 0;
BA_DEF_DEF_  "GenMsgCycleTime" 0;
BA_DEF_DEF_  "GenMsgSendType" "Cyclic";
BA_DEF_DEF_  "CANFD_BRS" "1";
BA_DEF_DEF_  "VFrameFormat" "StandardCAN";
BA_ "BusType" "CAN FD";
BA_ "DiagNode" BU_ IAVAS 1;
BA_ "DiagNode" BU_ ADAS 1;
BA_ "DiagNode" BU_ ADAS_GW 1;
BA_ "DiagNode" BU_ BEV 1;
BA_ "DiagNode" BU_ BEV_GW 1;
BA_ "DiagNode" BU_ LCT 1;
BA_ "DiagNode" BU_ STA 1;
BA_ "DiagNode" BU_ ABG 1;
BA_ "DiagNode" BU_ EPS 1;
BA_ "DiagNode" BU_ IPMS 1;
BA_ "DiagNode" BU_ BST 1;
BA_ "DiagNode" BU_ VDC 1;
BA_ "DiagNode" BU_ C_ECU 1;
BA_ "DiagNode" BU_ C_ECU_GW 1;
BA_ "GenMsgCycleTime" BO_ 1370 1000;
BA_ "VFrameFormat" BO_ 1370 14;
BA_ "GenMsgCycleTime" BO_ 1606 1000;
BA_ "GenMsgDelayTime" BO_ 1606 50;
BA_ "GenMsgCycleTimeFast" BO_ 1606 50;
BA_ "GenMsgNrOfRepetition" BO_ 1606 2;
BA_ "MsgRoutingId" BO_ 1606 "278 ";
BA_ "VFrameFormat" BO_ 1606 14;
BA_ "GenMsgCycleTime" BO_ 967 100;
BA_ "GenMsgDelayTime" BO_ 967 50;
BA_ "GenMsgCycleTimeFast" BO_ 967 50;
BA_ "GenMsgNrOfRepetition" BO_ 967 2;
BA_ "MsgRoutingId" BO_ 967 "277 ";
BA_ "VFrameFormat" BO_ 967 14;
BA_ "GenMsgCycleTime" BO_ 966 100;
BA_ "GenMsgDelayTime" BO_ 966 50;
BA_ "GenMsgCycleTimeFast" BO_ 966 50;
BA_ "GenMsgNrOfRepetition" BO_ 966 2;
BA_ "MsgRoutingId" BO_ 966 "276 ";
BA_ "VFrameFormat" BO_ 966 14;
BA_ "GenMsgCycleTime" BO_ 965 100;
BA_ "GenMsgDelayTime" BO_ 965 50;
BA_ "GenMsgCycleTimeFast" BO_ 965 50;
BA_ "GenMsgNrOfRepetition" BO_ 965 2;
BA_ "MsgRoutingId" BO_ 965 "275 ";
BA_ "VFrameFormat" BO_ 965 14;
BA_ "GenMsgCycleTime" BO_ 964 100;
BA_ "GenMsgDelayTime" BO_ 964 50;
BA_ "GenMsgCycleTimeFast" BO_ 964 50;
BA_ "GenMsgNrOfRepetition" BO_ 964 2;
BA_ "MsgRoutingId" BO_ 964 "274 ";
BA_ "VFrameFormat" BO_ 964 14;
BA_ "GenMsgCycleTime" BO_ 554 50;
BA_ "MsgRoutingId" BO_ 554 "273 ";
BA_ "VFrameFormat" BO_ 554 14;
BA_ "GenMsgCycleTime" BO_ 807 100;
BA_ "GenMsgDelayTime" BO_ 807 50;
BA_ "GenMsgCycleTimeFast" BO_ 807 50;
BA_ "GenMsgNrOfRepetition" BO_ 807 2;
BA_ "VFrameFormat" BO_ 807 14;
BA_ "GenMsgCycleTime" BO_ 806 100;
BA_ "GenMsgDelayTime" BO_ 806 50;
BA_ "GenMsgCycleTimeFast" BO_ 806 50;
BA_ "GenMsgNrOfRepetition" BO_ 806 2;
BA_ "MsgRoutingId" BO_ 806 "272 ";
BA_ "VFrameFormat" BO_ 806 14;
BA_ "GenMsgCycleTime" BO_ 805 100;
BA_ "GenMsgDelayTime" BO_ 805 20;
BA_ "GenMsgCycleTimeFast" BO_ 805 50;
BA_ "GenMsgNrOfRepetition" BO_ 805 2;
BA_ "MsgRoutingId" BO_ 805 "271 ";
BA_ "VFrameFormat" BO_ 805 14;
BA_ "GenMsgCycleTime" BO_ 804 100;
BA_ "GenMsgDelayTime" BO_ 804 50;
BA_ "GenMsgCycleTimeFast" BO_ 804 50;
BA_ "GenMsgNrOfRepetition" BO_ 804 2;
BA_ "MsgRoutingId" BO_ 804 "270 ";
BA_ "VFrameFormat" BO_ 804 14;
BA_ "GenMsgCycleTime" BO_ 803 100;
BA_ "GenMsgDelayTime" BO_ 803 50;
BA_ "GenMsgCycleTimeFast" BO_ 803 50;
BA_ "GenMsgNrOfRepetition" BO_ 803 2;
BA_ "MsgRoutingId" BO_ 803 "269 ";
BA_ "VFrameFormat" BO_ 803 14;
BA_ "GenMsgCycleTime" BO_ 802 100;
BA_ "GenMsgDelayTime" BO_ 802 50;
BA_ "GenMsgCycleTimeFast" BO_ 802 50;
BA_ "GenMsgNrOfRepetition" BO_ 802 2;
BA_ "MsgRoutingId" BO_ 802 "268 ";
BA_ "VFrameFormat" BO_ 802 14;
BA_ "GenMsgCycleTime" BO_ 801 100;
BA_ "GenMsgDelayTime" BO_ 801 50;
BA_ "GenMsgCycleTimeFast" BO_ 801 50;
BA_ "GenMsgNrOfRepetition" BO_ 801 2;
BA_ "MsgRoutingId" BO_ 801 "267 ";
BA_ "VFrameFormat" BO_ 801 14;
BA_ "GenMsgCycleTime" BO_ 571 50;
BA_ "VFrameFormat" BO_ 571 14;
BA_ "GenMsgCycleTime" BO_ 556 50;
BA_ "MsgRoutingId" BO_ 556 "266 ";
BA_ "VFrameFormat" BO_ 556 14;
BA_ "GenMsgCycleTime" BO_ 546 50;
BA_ "VFrameFormat" BO_ 546 14;
BA_ "GenMsgCycleTime" BO_ 545 50;
BA_ "MsgRoutingId" BO_ 545 "265 ";
BA_ "VFrameFormat" BO_ 545 14;
BA_ "GenMsgCycleTime" BO_ 1352 1000;
BA_ "VFrameFormat" BO_ 1352 14;
BA_ "GenMsgCycleTime" BO_ 1746 1000;
BA_ "MsgRoutingId" BO_ 1746 "264 ";
BA_ "VFrameFormat" BO_ 1746 14;
BA_ "GenMsgCycleTime" BO_ 1369 1000;
BA_ "VFrameFormat" BO_ 1369 14;
BA_ "GenMsgCycleTime" BO_ 1375 1000;
BA_ "VFrameFormat" BO_ 1375 14;
BA_ "GenMsgCycleTime" BO_ 1374 1000;
BA_ "VFrameFormat" BO_ 1374 14;
BA_ "GenMsgCycleTime" BO_ 916 100;
BA_ "GenMsgDelayTime" BO_ 916 10;
BA_ "GenMsgCycleTimeFast" BO_ 916 20;
BA_ "GenMsgNrOfRepetition" BO_ 916 3;
BA_ "MsgRoutingId" BO_ 916 "260 ";
BA_ "VFrameFormat" BO_ 916 14;
BA_ "GenMsgCycleTime" BO_ 911 100;
BA_ "VFrameFormat" BO_ 911 14;
BA_ "GenMsgCycleTime" BO_ 910 100;
BA_ "VFrameFormat" BO_ 910 14;
BA_ "GenMsgCycleTime" BO_ 909 100;
BA_ "VFrameFormat" BO_ 909 14;
BA_ "GenMsgCycleTime" BO_ 908 100;
BA_ "VFrameFormat" BO_ 908 14;
BA_ "GenMsgCycleTime" BO_ 905 100;
BA_ "VFrameFormat" BO_ 905 14;
BA_ "GenMsgCycleTime" BO_ 904 100;
BA_ "VFrameFormat" BO_ 904 14;
BA_ "GenMsgCycleTime" BO_ 903 100;
BA_ "VFrameFormat" BO_ 903 14;
BA_ "GenMsgCycleTime" BO_ 902 100;
BA_ "VFrameFormat" BO_ 902 14;
BA_ "GenMsgCycleTime" BO_ 901 100;
BA_ "VFrameFormat" BO_ 901 14;
BA_ "GenMsgCycleTime" BO_ 900 100;
BA_ "VFrameFormat" BO_ 900 14;
BA_ "GenMsgCycleTime" BO_ 899 100;
BA_ "VFrameFormat" BO_ 899 14;
BA_ "GenMsgCycleTime" BO_ 898 100;
BA_ "VFrameFormat" BO_ 898 14;
BA_ "GenMsgSendType" BO_ 2564481052 8;
BA_ "GenMsgNrOfRepetition" BO_ 2564481052 1;
BA_ "DiagRequest" BO_ 2564481052 1;
BA_ "GenMsgILSupport" BO_ 2564481052 0;
BA_ "MsgRoutingId" BO_ 2564481052 "255 ";
BA_ "VFrameFormat" BO_ 2564481052 1;
BA_ "GenMsgSendType" BO_ 2564431072 8;
BA_ "GenMsgNrOfRepetition" BO_ 2564431072 1;
BA_ "DiagRequest" BO_ 2564431072 1;
BA_ "GenMsgILSupport" BO_ 2564431072 0;
BA_ "MsgRoutingId" BO_ 2564431072 "254 ";
BA_ "VFrameFormat" BO_ 2564431072 1;
BA_ "GenMsgCycleTime" BO_ 1702 1000;
BA_ "VFrameFormat" BO_ 1702 14;
BA_ "GenMsgCycleTime" BO_ 264 20;
BA_ "VFrameFormat" BO_ 264 14;
BA_ "GenMsgSendType" BO_ 2564481353 8;
BA_ "GenMsgNrOfRepetition" BO_ 2564481353 1;
BA_ "DiagResponse" BO_ 2564481353 1;
BA_ "GenMsgILSupport" BO_ 2564481353 0;
BA_ "VFrameFormat" BO_ 2564481353 15;
BA_ "GenMsgSendType" BO_ 2564442593 8;
BA_ "GenMsgNrOfRepetition" BO_ 2564442593 1;
BA_ "DiagRequest" BO_ 2564442593 1;
BA_ "GenMsgILSupport" BO_ 2564442593 0;
BA_ "VFrameFormat" BO_ 2564442593 15;
BA_ "GenMsgCycleTime" BO_ 1687 1000;
BA_ "GenMsgDelayTime" BO_ 1687 10;
BA_ "GenMsgCycleTimeFast" BO_ 1687 20;
BA_ "GenMsgNrOfRepetition" BO_ 1687 50;
BA_ "VFrameFormat" BO_ 1687 14;
BA_ "GenMsgCycleTime" BO_ 1686 1000;
BA_ "VFrameFormat" BO_ 1686 14;
BA_ "GenMsgCycleTime" BO_ 1685 1000;
BA_ "MsgRoutingId" BO_ 1685 "219 ";
BA_ "VFrameFormat" BO_ 1685 14;
BA_ "GenMsgCycleTime" BO_ 1304 1000;
BA_ "GenMsgDelayTime" BO_ 1304 10;
BA_ "GenMsgNrOfRepetition" BO_ 1304 1;
BA_ "VFrameFormat" BO_ 1304 14;
BA_ "GenMsgCycleTime" BO_ 1541 1000;
BA_ "GenMsgDelayTime" BO_ 1541 10;
BA_ "GenMsgNrOfRepetition" BO_ 1541 1;
BA_ "VFrameFormat" BO_ 1541 14;
BA_ "GenMsgCycleTime" BO_ 1540 1000;
BA_ "VFrameFormat" BO_ 1540 14;
BA_ "GenMsgCycleTime" BO_ 1537 1000;
BA_ "GenMsgCycleTimeFast" BO_ 1537 10;
BA_ "GenMsgNrOfRepetition" BO_ 1537 5;
BA_ "MsgRoutingId" BO_ 1537 "214 ";
BA_ "VFrameFormat" BO_ 1537 14;
BA_ "GenMsgCycleTime" BO_ 543 50;
BA_ "VFrameFormat" BO_ 543 14;
BA_ "GenMsgCycleTime" BO_ 495 30;
BA_ "MsgRoutingId" BO_ 495 "213 ";
BA_ "GenMsgILSupport" BO_ 495 0;
BA_ "VFrameFormat" BO_ 495 14;
BA_ "GenMsgCycleTime" BO_ 494 30;
BA_ "MsgRoutingId" BO_ 494 "212 ";
BA_ "GenMsgILSupport" BO_ 494 0;
BA_ "VFrameFormat" BO_ 494 14;
BA_ "GenMsgCycleTime" BO_ 267 20;
BA_ "MsgRoutingId" BO_ 267 "211 ";
BA_ "GenMsgILSupport" BO_ 267 0;
BA_ "VFrameFormat" BO_ 267 14;
BA_ "GenMsgCycleTime" BO_ 117 10;
BA_ "MsgRoutingId" BO_ 117 "210 ";
BA_ "GenMsgILSupport" BO_ 117 0;
BA_ "VFrameFormat" BO_ 117 14;
BA_ "GenMsgCycleTime" BO_ 116 10;
BA_ "MsgRoutingId" BO_ 116 "209 ";
BA_ "GenMsgILSupport" BO_ 116 0;
BA_ "VFrameFormat" BO_ 116 14;
BA_ "GenMsgSendType" BO_ 2041 8;
BA_ "GenMsgNrOfRepetition" BO_ 2041 1;
BA_ "MsgRoutingId" BO_ 2041 "208 ";
BA_ "GenMsgSendType" BO_ 2033 8;
BA_ "GenMsgNrOfRepetition" BO_ 2033 1;
BA_ "MsgRoutingId" BO_ 2033 "207 ";
BA_ "GenMsgILSupport" BO_ 2033 0;
BA_ "GenMsgSendType" BO_ 1803 8;
BA_ "GenMsgNrOfRepetition" BO_ 1803 1;
BA_ "MsgRoutingId" BO_ 1803 "206 ";
BA_ "GenMsgSendType" BO_ 1802 8;
BA_ "GenMsgNrOfRepetition" BO_ 1802 1;
BA_ "MsgRoutingId" BO_ 1802 "205 ";
BA_ "GenMsgSendType" BO_ 2564481410 8;
BA_ "GenMsgNrOfRepetition" BO_ 2564481410 1;
BA_ "DiagResponse" BO_ 2564481410 1;
BA_ "GenMsgILSupport" BO_ 2564481410 0;
BA_ "VFrameFormat" BO_ 2564481410 15;
BA_ "GenMsgSendType" BO_ 2564457185 8;
BA_ "GenMsgNrOfRepetition" BO_ 2564457185 1;
BA_ "DiagRequest" BO_ 2564457185 1;
BA_ "GenMsgILSupport" BO_ 2564457185 0;
BA_ "VFrameFormat" BO_ 2564457185 15;
BA_ "GenMsgSendType" BO_ 2564481411 8;
BA_ "GenMsgNrOfRepetition" BO_ 2564481411 1;
BA_ "DiagResponse" BO_ 2564481411 1;
BA_ "GenMsgILSupport" BO_ 2564481411 0;
BA_ "VFrameFormat" BO_ 2564481411 15;
BA_ "GenMsgSendType" BO_ 2564457441 8;
BA_ "GenMsgNrOfRepetition" BO_ 2564457441 1;
BA_ "DiagRequest" BO_ 2564457441 1;
BA_ "GenMsgILSupport" BO_ 2564457441 0;
BA_ "VFrameFormat" BO_ 2564457441 15;
BA_ "GenMsgSendType" BO_ 2564481286 8;
BA_ "GenMsgNrOfRepetition" BO_ 2564481286 1;
BA_ "DiagResponse" BO_ 2564481286 1;
BA_ "GenMsgILSupport" BO_ 2564481286 0;
BA_ "VFrameFormat" BO_ 2564481286 15;
BA_ "GenMsgSendType" BO_ 2564425441 8;
BA_ "GenMsgNrOfRepetition" BO_ 2564425441 1;
BA_ "DiagRequest" BO_ 2564425441 1;
BA_ "GenMsgILSupport" BO_ 2564425441 0;
BA_ "VFrameFormat" BO_ 2564425441 15;
BA_ "GenMsgSendType" BO_ 2564481285 8;
BA_ "GenMsgNrOfRepetition" BO_ 2564481285 1;
BA_ "DiagResponse" BO_ 2564481285 1;
BA_ "GenMsgILSupport" BO_ 2564481285 0;
BA_ "VFrameFormat" BO_ 2564481285 15;
BA_ "GenMsgSendType" BO_ 2564425185 8;
BA_ "GenMsgNrOfRepetition" BO_ 2564425185 1;
BA_ "DiagRequest" BO_ 2564425185 1;
BA_ "GenMsgILSupport" BO_ 2564425185 0;
BA_ "VFrameFormat" BO_ 2564425185 15;
BA_ "GenMsgSendType" BO_ 2564481372 8;
BA_ "GenMsgNrOfRepetition" BO_ 2564481372 1;
BA_ "DiagResponse" BO_ 2564481372 1;
BA_ "GenMsgILSupport" BO_ 2564481372 0;
BA_ "VFrameFormat" BO_ 2564481372 15;
BA_ "GenMsgSendType" BO_ 2564447457 8;
BA_ "GenMsgNrOfRepetition" BO_ 2564447457 1;
BA_ "DiagRequest" BO_ 2564447457 1;
BA_ "GenMsgILSupport" BO_ 2564447457 0;
BA_ "VFrameFormat" BO_ 2564447457 15;
BA_ "GenMsgSendType" BO_ 2564481371 8;
BA_ "GenMsgNrOfRepetition" BO_ 2564481371 1;
BA_ "DiagResponse" BO_ 2564481371 1;
BA_ "GenMsgILSupport" BO_ 2564481371 0;
BA_ "VFrameFormat" BO_ 2564481371 15;
BA_ "GenMsgSendType" BO_ 2564447201 8;
BA_ "GenMsgNrOfRepetition" BO_ 2564447201 1;
BA_ "DiagRequest" BO_ 2564447201 1;
BA_ "GenMsgILSupport" BO_ 2564447201 0;
BA_ "VFrameFormat" BO_ 2564447201 15;
BA_ "GenMsgSendType" BO_ 2564481476 8;
BA_ "GenMsgNrOfRepetition" BO_ 2564481476 1;
BA_ "DiagResponse" BO_ 2564481476 1;
BA_ "GenMsgILSupport" BO_ 2564481476 0;
BA_ "VFrameFormat" BO_ 2564481476 15;
BA_ "GenMsgSendType" BO_ 2564474081 8;
BA_ "GenMsgNrOfRepetition" BO_ 2564474081 1;
BA_ "DiagRequest" BO_ 2564474081 1;
BA_ "GenMsgILSupport" BO_ 2564474081 0;
BA_ "VFrameFormat" BO_ 2564474081 15;
BA_ "GenMsgSendType" BO_ 2564481215 8;
BA_ "GenMsgNrOfRepetition" BO_ 2564481215 1;
BA_ "DiagResponse" BO_ 2564481215 1;
BA_ "GenMsgILSupport" BO_ 2564481215 0;
BA_ "MsgRoutingId" BO_ 2564481215 "202 ";
BA_ "VFrameFormat" BO_ 2564481215 15;
BA_ "GenMsgSendType" BO_ 2564472800 8;
BA_ "GenMsgNrOfRepetition" BO_ 2564472800 1;
BA_ "DiagRequest" BO_ 2564472800 1;
BA_ "GenMsgILSupport" BO_ 2564472800 0;
BA_ "MsgRoutingId" BO_ 2564472800 "201 ";
BA_ "VFrameFormat" BO_ 2564472800 15;
BA_ "GenMsgSendType" BO_ 2564481216 8;
BA_ "GenMsgNrOfRepetition" BO_ 2564481216 1;
BA_ "DiagResponse" BO_ 2564481216 1;
BA_ "GenMsgILSupport" BO_ 2564481216 0;
BA_ "MsgRoutingId" BO_ 2564481216 "200 ";
BA_ "VFrameFormat" BO_ 2564481216 15;
BA_ "GenMsgSendType" BO_ 2564473056 8;
BA_ "GenMsgNrOfRepetition" BO_ 2564473056 1;
BA_ "DiagResponse" BO_ 2564473056 1;
BA_ "GenMsgILSupport" BO_ 2564473056 0;
BA_ "MsgRoutingId" BO_ 2564473056 "199 ";
BA_ "VFrameFormat" BO_ 2564473056 15;
BA_ "GenMsgSendType" BO_ 2564481472 8;
BA_ "GenMsgNrOfRepetition" BO_ 2564481472 1;
BA_ "DiagResponse" BO_ 2564481472 1;
BA_ "GenMsgILSupport" BO_ 2564481472 0;
BA_ "VFrameFormat" BO_ 2564481472 15;
BA_ "GenMsgSendType" BO_ 2564473057 8;
BA_ "GenMsgNrOfRepetition" BO_ 2564473057 1;
BA_ "DiagRequest" BO_ 2564473057 1;
BA_ "GenMsgILSupport" BO_ 2564473057 0;
BA_ "VFrameFormat" BO_ 2564473057 15;
BA_ "GenMsgSendType" BO_ 2564487618 8;
BA_ "GenMsgNrOfRepetition" BO_ 2564487618 1;
BA_ "DiagResponse" BO_ 2564487618 1;
BA_ "GenMsgILSupport" BO_ 2564487618 0;
BA_ "VFrameFormat" BO_ 2564487618 1;
BA_ "GenMsgSendType" BO_ 2564473593 8;
BA_ "GenMsgNrOfRepetition" BO_ 2564473593 1;
BA_ "DiagRequest" BO_ 2564473593 1;
BA_ "GenMsgILSupport" BO_ 2564473593 0;
BA_ "VFrameFormat" BO_ 2564473593 1;
BA_ "GenMsgSendType" BO_ 2564481474 8;
BA_ "GenMsgNrOfRepetition" BO_ 2564481474 1;
BA_ "DiagResponse" BO_ 2564481474 1;
BA_ "GenMsgILSupport" BO_ 2564481474 0;
BA_ "VFrameFormat" BO_ 2564481474 15;
BA_ "GenMsgSendType" BO_ 2564473569 8;
BA_ "GenMsgNrOfRepetition" BO_ 2564473569 1;
BA_ "DiagRequest" BO_ 2564473569 1;
BA_ "GenMsgILSupport" BO_ 2564473569 0;
BA_ "VFrameFormat" BO_ 2564473569 15;
BA_ "VFrameFormat" BO_ 2564481218 1;
BA_ "GenMsgSendType" BO_ 2564481218 8;
BA_ "GenMsgNrOfRepetition" BO_ 2564481218 1;
BA_ "DiagResponse" BO_ 2564481218 1;
BA_ "GenMsgILSupport" BO_ 2564481218 0;
BA_ "MsgRoutingId" BO_ 2564481218 "198 ";
BA_ "VFrameFormat" BO_ 2564473568 1;
BA_ "GenMsgSendType" BO_ 2564473568 8;
BA_ "GenMsgNrOfRepetition" BO_ 2564473568 1;
BA_ "DiagRequest" BO_ 2564473568 1;
BA_ "GenMsgILSupport" BO_ 2564473568 0;
BA_ "MsgRoutingId" BO_ 2564473568 "197 ";
BA_ "GenSigStartValue" SG_ 807 EYE327_6_1_EDR_STATUS_ACSF_C 5;
BA_ "GenSigStartValue" SG_ 807 EYE327_6_4_EDR_STATUS_MRM 5;
BA_ "GenSigStartValue" SG_ 807 EYE327_5_2_EDR_STATUS_FCTB 6;
BA_ "GenSigStartValue" SG_ 807 EYE327_5_6_EDR_STATUS_ACSF_B1 4;
BA_ "GenSigStartValue" SG_ 807 EYE327_4_2_EDR_STATUS_PCB_EYECAM 4;
BA_ "GenSigStartValue" SG_ 807 EYE327_4_6_EDR_STATUS_PCB_MCAM 4;
BA_ "GenSigStartValue" SG_ 807 EYE327_3_0_EDR_STATUS_CC 4;
BA_ "GenSigStartValue" SG_ 807 EYE327_3_3_EDR_STATUS_ACC 4;
BA_ "GenSigStartValue" SG_ 807 EYE327_3_6_EDR_STATUS_AEBS 4;
BA_ "GenSigStartValue" SG_ 807 EYE327_2_2_EDR_STATUS_ESF_ELK 5;
BA_ "GenSigStartValue" SG_ 807 EYE327_2_5_EDR_STATUS_CSF_LDP 5;
BA_ "GenSigStartValue" SG_ 807 EYE327_1_4_EDR_STATUS_LDWS 5;
BA_ "GenSigStartValue" SG_ 807 EYE327_1_7_EDR_STATUS_ESF_AES 5;
BA_ "GenSigStartValue" SG_ 806 EYE326_5_0_TIME 16777215;
BA_ "GenSigStartValue" SG_ 806 EYE326_3_0_YEAR 127;
BA_ "GenSigStartValue" SG_ 806 EYE326_3_7_MONTH 15;
BA_ "GenSigStartValue" SG_ 805 EYE325_2_0_RAB_OFF 1;
BA_ "GenSigStartValue" SG_ 805 EYE325_2_1_SONAR_OFF 1;
BA_ "GenSigStartValue" SG_ 805 EYE325_2_6_RAB_DISABLE 1;
BA_ "GenSigStartValue" SG_ 805 EYE325_2_7_SONAR_DISABLE 1;
BA_ "GenSigStartValue" SG_ 805 EYE325_1_7_SONAR_NO_DISP 1;
BA_ "GenSigStartValue" SG_ 803 EYE323_7_0_ISA_OFFSET_CURR 10;
BA_ "GenSigStartValue" SG_ 803 EYE323_6_1_LDW_ON_OFF_SET 1;
BA_ "GenSigStartValue" SG_ 803 EYE323_5_3_FCW_ON_OFF_SET 1;
BA_ "GenSigStartValue" SG_ 801 EYE321_4_2_SRVD_LASTMEM_ST_REQ 1;
BA_ "GenSigStartValue" SG_ 801 EYE321_1_4_PRECRASH_BRAKE_OFF 1;
BA_ "GenSigStartValue" SG_ 801 EYE321_1_5_LANE_DEPARTURE_OFF 1;
BA_ "GenSigStartValue" SG_ 571 EYE23B_1_0_TRQDWN_FORCE_LIMIT 255;
BA_ "GenSigStartValue" SG_ 556 EYE22C_5_0_TRQDWN_FORCE_LIMIT 255;
BA_ "Fhi_SignalComment" SG_ 556 EYE22C_5_0_TRQDWN_FORCE_LIMIT "※

ｶﾞｿﾘﾝ車＝“トルクダウン指示”を送信

HEV車＝“駆動力制限値指示”を送信

";
BA_ "Fhi_SignalComment" SG_ 556 EYE22C_2_0_TGT_SPD_TRQ_FORCE "※

ｶﾞｿﾘﾝ車：“目標トルク”を送信

HEV車：“目標駆動力”を送信

";
BA_ "GenSigStartValue" SG_ 545 EYE221_5_0_TRQDWN_FORCE_LIMIT 255;
BA_ "Fhi_SignalComment" SG_ 545 EYE221_5_0_TRQDWN_FORCE_LIMIT "※

ｶﾞｿﾘﾝ車＝“トルクダウン指示”を送信

HEV車＝“駆動力制限値指示”を送信

";
BA_ "GenSigStartValue" SG_ 545 EYE221_4_2_FORCED_CANCEL_ACC 1;
BA_ "Fhi_SignalComment" SG_ 545 EYE221_2_0_TGT_SPD_TRQ_FORCE "※

ｶﾞｿﾘﾝ車：“目標トルク”を送信

HEV車：“目標駆動力”を送信

";
BA_ "GenSigStartValue" SG_ 1746 LCT6D2_5_0_HDMAP_RELEASE_SEASON 15;
BA_ "GenSigStartValue" SG_ 1746 LCT6D2_5_4_HDMAP_RELEASE_REV 15;
BA_ "GenSigStartValue" SG_ 1746 LCT6D2_4_0_HDMAP_RELEASE_YEAR 255;
BA_ "GenSigStartValue" SG_ 1746 LCT6D2_3_0_ISAMAP_RELEASE_SEASON 15;
BA_ "GenSigStartValue" SG_ 1746 LCT6D2_3_4_ISAMAP_RELEASE_REV 15;
BA_ "GenSigStartValue" SG_ 1746 LCT6D2_2_0_ISAMAP_RELEASE_YEAR 255;
BA_ "GenSigSendType" SG_ 2564481052 LCT18DAE01C_DIAG_DATA 2;
BA_ "GenSigSendType" SG_ 2564431072 DNT18DA1CE0_DIAG_DATA 2;
BA_ "Fhi_SignalComment" SG_ 264 ADAS108_1_6_VRU_DET_STATE "-

";
BA_ "Fhi_SignalComment" SG_ 264 ADAS108_1_4_VRU_DET_STATE_ABG "-

";
BA_ "GenSigSendType" SG_ 2564481353 OBC18DAE149_DIAG_DATA_EXT7 2;
BA_ "GenSigSendType" SG_ 2564481353 OBC18DAE149_DIAG_DATA_EXT6 2;
BA_ "GenSigSendType" SG_ 2564481353 OBC18DAE149_DIAG_DATA_EXT5 2;
BA_ "GenSigSendType" SG_ 2564481353 OBC18DAE149_DIAG_DATA_EXT4 2;
BA_ "GenSigSendType" SG_ 2564481353 OBC18DAE149_DIAG_DATA_EXT3 2;
BA_ "GenSigSendType" SG_ 2564481353 OBC18DAE149_DIAG_DATA_EXT2 2;
BA_ "GenSigSendType" SG_ 2564481353 OBC18DAE149_DIAG_DATA_EXT1 2;
BA_ "GenSigSendType" SG_ 2564481353 OBC18DAE149_DIAG_DATA 2;
BA_ "GenSigSendType" SG_ 2564442593 CECU18DA49E1_DIAG_DATA_EXT7 2;
BA_ "GenSigSendType" SG_ 2564442593 CECU18DA49E1_DIAG_DATA_EXT6 2;
BA_ "GenSigSendType" SG_ 2564442593 CECU18DA49E1_DIAG_DATA_EXT5 2;
BA_ "GenSigSendType" SG_ 2564442593 CECU18DA49E1_DIAG_DATA_EXT4 2;
BA_ "GenSigSendType" SG_ 2564442593 CECU18DA49E1_DIAG_DATA_EXT3 2;
BA_ "GenSigSendType" SG_ 2564442593 CECU18DA49E1_DIAG_DATA_EXT2 2;
BA_ "GenSigSendType" SG_ 2564442593 CECU18DA49E1_DIAG_DATA_EXT1 2;
BA_ "GenSigSendType" SG_ 2564442593 CECU18DA49E1_DIAG_DATA 2;
BA_ "GenSigSendType" SG_ 1541 BEV605_3_0_IGBHLDRQ 3;
BA_ "GenSigSendType" SG_ 1541 BEV605_3_2_ILK 3;
BA_ "GenSigSendType" SG_ 1541 BEV605_3_3_HVSYSNG 3;
BA_ "GenSigStartValue" SG_ 116 BEV074_3_0_RANGE_POS 6;
BA_ "GenSigSendType" SG_ 2041 ABG7F9_7_0_DATA 2;
BA_ "GenSigSendType" SG_ 2033 ABG7F1_7_0_DATA 2;
BA_ "GenSigSendType" SG_ 1803 VDC70B_7_0_DATA 2;
BA_ "GenSigSendType" SG_ 1802 VDC70A_7_0_DATA 2;
BA_ "GenSigSendType" SG_ 2564481410 FCRL18DAE182_DIAG_DATA_EXT7 2;
BA_ "GenSigSendType" SG_ 2564481410 FCRL18DAE182_DIAG_DATA_EXT6 2;
BA_ "GenSigSendType" SG_ 2564481410 FCRL18DAE182_DIAG_DATA_EXT5 2;
BA_ "GenSigSendType" SG_ 2564481410 FCRL18DAE182_DIAG_DATA_EXT4 2;
BA_ "GenSigSendType" SG_ 2564481410 FCRL18DAE182_DIAG_DATA_EXT3 2;
BA_ "GenSigSendType" SG_ 2564481410 FCRL18DAE182_DIAG_DATA_EXT2 2;
BA_ "GenSigSendType" SG_ 2564481410 FCRL18DAE182_DIAG_DATA_EXT1 2;
BA_ "GenSigSendType" SG_ 2564481410 FCRL18DAE182_DIAG_DATA 2;
BA_ "GenSigSendType" SG_ 2564457185 CECU18DA82E1_DIAG_DATA_EXT7 2;
BA_ "GenSigSendType" SG_ 2564457185 CECU18DA82E1_DIAG_DATA_EXT6 2;
BA_ "GenSigSendType" SG_ 2564457185 CECU18DA82E1_DIAG_DATA_EXT5 2;
BA_ "GenSigSendType" SG_ 2564457185 CECU18DA82E1_DIAG_DATA_EXT4 2;
BA_ "GenSigSendType" SG_ 2564457185 CECU18DA82E1_DIAG_DATA_EXT3 2;
BA_ "GenSigSendType" SG_ 2564457185 CECU18DA82E1_DIAG_DATA_EXT2 2;
BA_ "GenSigSendType" SG_ 2564457185 CECU18DA82E1_DIAG_DATA_EXT1 2;
BA_ "GenSigSendType" SG_ 2564457185 CECU18DA82E1_DIAG_DATA 2;
BA_ "GenSigSendType" SG_ 2564481411 FCRR18DAE183_DIAG_DATA_EXT7 2;
BA_ "GenSigSendType" SG_ 2564481411 FCRR18DAE183_DIAG_DATA_EXT6 2;
BA_ "GenSigSendType" SG_ 2564481411 FCRR18DAE183_DIAG_DATA_EXT5 2;
BA_ "GenSigSendType" SG_ 2564481411 FCRR18DAE183_DIAG_DATA_EXT4 2;
BA_ "GenSigSendType" SG_ 2564481411 FCRR18DAE183_DIAG_DATA_EXT3 2;
BA_ "GenSigSendType" SG_ 2564481411 FCRR18DAE183_DIAG_DATA_EXT2 2;
BA_ "GenSigSendType" SG_ 2564481411 FCRR18DAE183_DIAG_DATA_EXT1 2;
BA_ "GenSigSendType" SG_ 2564481411 FCRR18DAE183_DIAG_DATA 2;
BA_ "GenSigSendType" SG_ 2564457441 CECU18DA83E1_DIAG_DATA_EXT7 2;
BA_ "GenSigSendType" SG_ 2564457441 CECU18DA83E1_DIAG_DATA_EXT6 2;
BA_ "GenSigSendType" SG_ 2564457441 CECU18DA83E1_DIAG_DATA_EXT5 2;
BA_ "GenSigSendType" SG_ 2564457441 CECU18DA83E1_DIAG_DATA_EXT4 2;
BA_ "GenSigSendType" SG_ 2564457441 CECU18DA83E1_DIAG_DATA_EXT3 2;
BA_ "GenSigSendType" SG_ 2564457441 CECU18DA83E1_DIAG_DATA_EXT2 2;
BA_ "GenSigSendType" SG_ 2564457441 CECU18DA83E1_DIAG_DATA_EXT1 2;
BA_ "GenSigSendType" SG_ 2564457441 CECU18DA83E1_DIAG_DATA 2;
BA_ "GenSigSendType" SG_ 2564481286 PBW18DAE106_DIAG_DATA_EXT7 2;
BA_ "GenSigSendType" SG_ 2564481286 PBW18DAE106_DIAG_DATA_EXT6 2;
BA_ "GenSigSendType" SG_ 2564481286 PBW18DAE106_DIAG_DATA_EXT5 2;
BA_ "GenSigSendType" SG_ 2564481286 PBW18DAE106_DIAG_DATA_EXT4 2;
BA_ "GenSigSendType" SG_ 2564481286 PBW18DAE106_DIAG_DATA_EXT3 2;
BA_ "GenSigSendType" SG_ 2564481286 PBW18DAE106_DIAG_DATA_EXT2 2;
BA_ "GenSigSendType" SG_ 2564481286 PBW18DAE106_DIAG_DATA_EXT1 2;
BA_ "GenSigSendType" SG_ 2564481286 PBW18DAE106_DIAG_DATA 2;
BA_ "GenSigSendType" SG_ 2564425441 CECU18DA06E1_DIAG_DATA_EXT7 2;
BA_ "GenSigSendType" SG_ 2564425441 CECU18DA06E1_DIAG_DATA_EXT6 2;
BA_ "GenSigSendType" SG_ 2564425441 CECU18DA06E1_DIAG_DATA_EXT5 2;
BA_ "GenSigSendType" SG_ 2564425441 CECU18DA06E1_DIAG_DATA_EXT4 2;
BA_ "GenSigSendType" SG_ 2564425441 CECU18DA06E1_DIAG_DATA_EXT3 2;
BA_ "GenSigSendType" SG_ 2564425441 CECU18DA06E1_DIAG_DATA_EXT2 2;
BA_ "GenSigSendType" SG_ 2564425441 CECU18DA06E1_DIAG_DATA_EXT1 2;
BA_ "GenSigSendType" SG_ 2564425441 CECU18DA06E1_DIAG_DATA 2;
BA_ "GenSigSendType" SG_ 2564481285 SFT18DAE105_DIAG_DATA_EXT7 2;
BA_ "GenSigSendType" SG_ 2564481285 SFT18DAE105_DIAG_DATA_EXT6 2;
BA_ "GenSigSendType" SG_ 2564481285 SFT18DAE105_DIAG_DATA_EXT5 2;
BA_ "GenSigSendType" SG_ 2564481285 SFT18DAE105_DIAG_DATA_EXT4 2;
BA_ "GenSigSendType" SG_ 2564481285 SFT18DAE105_DIAG_DATA_EXT3 2;
BA_ "GenSigSendType" SG_ 2564481285 SFT18DAE105_DIAG_DATA_EXT2 2;
BA_ "GenSigSendType" SG_ 2564481285 SFT18DAE105_DIAG_DATA_EXT1 2;
BA_ "GenSigSendType" SG_ 2564481285 SFT18DAE105_DIAG_DATA 2;
BA_ "GenSigSendType" SG_ 2564425185 CECU18DA05E1_DIAG_DATA_EXT7 2;
BA_ "GenSigSendType" SG_ 2564425185 CECU18DA05E1_DIAG_DATA_EXT6 2;
BA_ "GenSigSendType" SG_ 2564425185 CECU18DA05E1_DIAG_DATA_EXT5 2;
BA_ "GenSigSendType" SG_ 2564425185 CECU18DA05E1_DIAG_DATA_EXT4 2;
BA_ "GenSigSendType" SG_ 2564425185 CECU18DA05E1_DIAG_DATA_EXT3 2;
BA_ "GenSigSendType" SG_ 2564425185 CECU18DA05E1_DIAG_DATA_EXT2 2;
BA_ "GenSigSendType" SG_ 2564425185 CECU18DA05E1_DIAG_DATA_EXT1 2;
BA_ "GenSigSendType" SG_ 2564425185 CECU18DA05E1_DIAG_DATA 2;
BA_ "GenSigSendType" SG_ 2564481372 MGR18DAE15C_DIAG_DATA_EXT7 2;
BA_ "GenSigSendType" SG_ 2564481372 MGR18DAE15C_DIAG_DATA_EXT6 2;
BA_ "GenSigSendType" SG_ 2564481372 MGR18DAE15C_DIAG_DATA_EXT5 2;
BA_ "GenSigSendType" SG_ 2564481372 MGR18DAE15C_DIAG_DATA_EXT4 2;
BA_ "GenSigSendType" SG_ 2564481372 MGR18DAE15C_DIAG_DATA_EXT3 2;
BA_ "GenSigSendType" SG_ 2564481372 MGR18DAE15C_DIAG_DATA_EXT2 2;
BA_ "GenSigSendType" SG_ 2564481372 MGR18DAE15C_DIAG_DATA_EXT1 2;
BA_ "GenSigSendType" SG_ 2564481372 MGR18DAE15C_DIAG_DATA 2;
BA_ "GenSigSendType" SG_ 2564447457 CECU18DA5CE1_DIAG_DATA_EXT7 2;
BA_ "GenSigSendType" SG_ 2564447457 CECU18DA5CE1_DIAG_DATA_EXT6 2;
BA_ "GenSigSendType" SG_ 2564447457 CECU18DA5CE1_DIAG_DATA_EXT5 2;
BA_ "GenSigSendType" SG_ 2564447457 CECU18DA5CE1_DIAG_DATA_EXT4 2;
BA_ "GenSigSendType" SG_ 2564447457 CECU18DA5CE1_DIAG_DATA_EXT3 2;
BA_ "GenSigSendType" SG_ 2564447457 CECU18DA5CE1_DIAG_DATA_EXT2 2;
BA_ "GenSigSendType" SG_ 2564447457 CECU18DA5CE1_DIAG_DATA_EXT1 2;
BA_ "GenSigSendType" SG_ 2564447457 CECU18DA5CE1_DIAG_DATA 2;
BA_ "GenSigSendType" SG_ 2564481371 MGF18DAE15B_DIAG_DATA_EXT7 2;
BA_ "GenSigSendType" SG_ 2564481371 MGF18DAE15B_DIAG_DATA_EXT6 2;
BA_ "GenSigSendType" SG_ 2564481371 MGF18DAE15B_DIAG_DATA_EXT5 2;
BA_ "GenSigSendType" SG_ 2564481371 MGF18DAE15B_DIAG_DATA_EXT4 2;
BA_ "GenSigSendType" SG_ 2564481371 MGF18DAE15B_DIAG_DATA_EXT3 2;
BA_ "GenSigSendType" SG_ 2564481371 MGF18DAE15B_DIAG_DATA_EXT2 2;
BA_ "GenSigSendType" SG_ 2564481371 MGF18DAE15B_DIAG_DATA_EXT1 2;
BA_ "GenSigSendType" SG_ 2564481371 MGF18DAE15B_DIAG_DATA 2;
BA_ "GenSigSendType" SG_ 2564447201 CECU18DA5BE1_DIAG_DATA_EXT7 2;
BA_ "GenSigSendType" SG_ 2564447201 CECU18DA5BE1_DIAG_DATA_EXT6 2;
BA_ "GenSigSendType" SG_ 2564447201 CECU18DA5BE1_DIAG_DATA_EXT5 2;
BA_ "GenSigSendType" SG_ 2564447201 CECU18DA5BE1_DIAG_DATA_EXT4 2;
BA_ "GenSigSendType" SG_ 2564447201 CECU18DA5BE1_DIAG_DATA_EXT3 2;
BA_ "GenSigSendType" SG_ 2564447201 CECU18DA5BE1_DIAG_DATA_EXT2 2;
BA_ "GenSigSendType" SG_ 2564447201 CECU18DA5BE1_DIAG_DATA_EXT1 2;
BA_ "GenSigSendType" SG_ 2564447201 CECU18DA5BE1_DIAG_DATA 2;
BA_ "GenSigSendType" SG_ 2564481476 BMU18DAE1C4_DIAG_DATA_EXT7 2;
BA_ "GenSigSendType" SG_ 2564481476 BMU18DAE1C4_DIAG_DATA_EXT6 2;
BA_ "GenSigSendType" SG_ 2564481476 BMU18DAE1C4_DIAG_DATA_EXT5 2;
BA_ "GenSigSendType" SG_ 2564481476 BMU18DAE1C4_DIAG_DATA_EXT4 2;
BA_ "GenSigSendType" SG_ 2564481476 BMU18DAE1C4_DIAG_DATA_EXT3 2;
BA_ "GenSigSendType" SG_ 2564481476 BMU18DAE1C4_DIAG_DATA_EXT2 2;
BA_ "GenSigSendType" SG_ 2564481476 BMU18DAE1C4_DIAG_DATA_EXT1 2;
BA_ "GenSigSendType" SG_ 2564481476 BMU18DAE1C4_DIAG_DATA 2;
BA_ "GenSigSendType" SG_ 2564474081 CECU18DAC4E1_DIAG_DATA_EXT7 2;
BA_ "GenSigSendType" SG_ 2564474081 CECU18DAC4E1_DIAG_DATA_EXT6 2;
BA_ "GenSigSendType" SG_ 2564474081 CECU18DAC4E1_DIAG_DATA_EXT5 2;
BA_ "GenSigSendType" SG_ 2564474081 CECU18DAC4E1_DIAG_DATA_EXT4 2;
BA_ "GenSigSendType" SG_ 2564474081 CECU18DAC4E1_DIAG_DATA_EXT3 2;
BA_ "GenSigSendType" SG_ 2564474081 CECU18DAC4E1_DIAG_DATA_EXT2 2;
BA_ "GenSigSendType" SG_ 2564474081 CECU18DAC4E1_DIAG_DATA_EXT1 2;
BA_ "GenSigSendType" SG_ 2564474081 CECU18DAC4E1_DIAG_DATA 2;
BA_ "GenSigSendType" SG_ 2564481215 SCA18DAE0BF_DIAG_DATA_EXT7 2;
BA_ "GenSigSendType" SG_ 2564481215 SCA18DAE0BF_DIAG_DATA_EXT6 2;
BA_ "GenSigSendType" SG_ 2564481215 SCA18DAE0BF_DIAG_DATA_EXT5 2;
BA_ "GenSigSendType" SG_ 2564481215 SCA18DAE0BF_DIAG_DATA_EXT4 2;
BA_ "GenSigSendType" SG_ 2564481215 SCA18DAE0BF_DIAG_DATA_EXT3 2;
BA_ "GenSigSendType" SG_ 2564481215 SCA18DAE0BF_DIAG_DATA_EXT2 2;
BA_ "GenSigSendType" SG_ 2564481215 SCA18DAE0BF_DIAG_DATA_EXT1 2;
BA_ "GenSigSendType" SG_ 2564481215 SCA18DAE0BF_DIAG_DATA 2;
BA_ "GenSigSendType" SG_ 2564472800 DNT18DABFE0_DIAG_DATA_EXT7 2;
BA_ "GenSigSendType" SG_ 2564472800 DNT18DABFE0_DIAG_DATA_EXT6 2;
BA_ "GenSigSendType" SG_ 2564472800 DNT18DABFE0_DIAG_DATA_EXT5 2;
BA_ "GenSigSendType" SG_ 2564472800 DNT18DABFE0_DIAG_DATA_EXT4 2;
BA_ "GenSigSendType" SG_ 2564472800 DNT18DABFE0_DIAG_DATA_EXT3 2;
BA_ "GenSigSendType" SG_ 2564472800 DNT18DABFE0_DIAG_DATA_EXT2 2;
BA_ "GenSigSendType" SG_ 2564472800 DNT18DABFE0_DIAG_DATA_EXT1 2;
BA_ "GenSigSendType" SG_ 2564472800 DNT18DABFE0_DIAG_DATA 2;
BA_ "GenSigSendType" SG_ 2564481216 ADAS18DAE0C0_DIAG_DATA_EXT7 2;
BA_ "GenSigSendType" SG_ 2564481216 ADAS18DAE0C0_DIAG_DATA_EXT6 2;
BA_ "GenSigSendType" SG_ 2564481216 ADAS18DAE0C0_DIAG_DATA_EXT5 2;
BA_ "GenSigSendType" SG_ 2564481216 ADAS18DAE0C0_DIAG_DATA_EXT4 2;
BA_ "GenSigSendType" SG_ 2564481216 ADAS18DAE0C0_DIAG_DATA_EXT3 2;
BA_ "GenSigSendType" SG_ 2564481216 ADAS18DAE0C0_DIAG_DATA_EXT2 2;
BA_ "GenSigSendType" SG_ 2564481216 ADAS18DAE0C0_DIAG_DATA_EXT1 2;
BA_ "GenSigSendType" SG_ 2564481216 ADAS18DAE0C0_DIAG_DATA 2;
BA_ "GenSigSendType" SG_ 2564473056 DNT18DAC0E0_DIAG_DATA_EXT7 2;
BA_ "GenSigSendType" SG_ 2564473056 DNT18DAC0E0_DIAG_DATA_EXT6 2;
BA_ "GenSigSendType" SG_ 2564473056 DNT18DAC0E0_DIAG_DATA_EXT5 2;
BA_ "GenSigSendType" SG_ 2564473056 DNT18DAC0E0_DIAG_DATA_EXT4 2;
BA_ "GenSigSendType" SG_ 2564473056 DNT18DAC0E0_DIAG_DATA_EXT3 2;
BA_ "GenSigSendType" SG_ 2564473056 DNT18DAC0E0_DIAG_DATA_EXT2 2;
BA_ "GenSigSendType" SG_ 2564473056 DNT18DAC0E0_DIAG_DATA_EXT1 2;
BA_ "GenSigSendType" SG_ 2564473056 DNT18DAC0E0_DIAG_DATA 2;
BA_ "GenSigSendType" SG_ 2564481472 ADAS18DAE1C0_DIAG_DATA_EXT7 2;
BA_ "GenSigSendType" SG_ 2564481472 ADAS18DAE1C0_DIAG_DATA_EXT6 2;
BA_ "GenSigSendType" SG_ 2564481472 ADAS18DAE1C0_DIAG_DATA_EXT5 2;
BA_ "GenSigSendType" SG_ 2564481472 ADAS18DAE1C0_DIAG_DATA_EXT4 2;
BA_ "GenSigSendType" SG_ 2564481472 ADAS18DAE1C0_DIAG_DATA_EXT3 2;
BA_ "GenSigSendType" SG_ 2564481472 ADAS18DAE1C0_DIAG_DATA_EXT2 2;
BA_ "GenSigSendType" SG_ 2564481472 ADAS18DAE1C0_DIAG_DATA_EXT1 2;
BA_ "GenSigSendType" SG_ 2564481472 ADAS18DAE1C0_DIAG_DATA 2;
BA_ "GenSigSendType" SG_ 2564473057 CECU18DAC0E1_DIAG_DATA_EXT7 2;
BA_ "GenSigSendType" SG_ 2564473057 CECU18DAC0E1_DIAG_DATA_EXT6 2;
BA_ "GenSigSendType" SG_ 2564473057 CECU18DAC0E1_DIAG_DATA_EXT5 2;
BA_ "GenSigSendType" SG_ 2564473057 CECU18DAC0E1_DIAG_DATA_EXT4 2;
BA_ "GenSigSendType" SG_ 2564473057 CECU18DAC0E1_DIAG_DATA_EXT3 2;
BA_ "GenSigSendType" SG_ 2564473057 CECU18DAC0E1_DIAG_DATA_EXT2 2;
BA_ "GenSigSendType" SG_ 2564473057 CECU18DAC0E1_DIAG_DATA_EXT1 2;
BA_ "GenSigSendType" SG_ 2564473057 CECU18DAC0E1_DIAG_DATA 2;
BA_ "GenSigSendType" SG_ 2564487618 IAVAS18DAF9C2_DIAG_DATA 2;
BA_ "GenSigSendType" SG_ 2564481474 IAVAS18DAE1C2_DIAG_DATA_EXT7 2;
BA_ "GenSigSendType" SG_ 2564481474 IAVAS18DAE1C2_DIAG_DATA_EXT6 2;
BA_ "GenSigSendType" SG_ 2564481474 IAVAS18DAE1C2_DIAG_DATA_EXT5 2;
BA_ "GenSigSendType" SG_ 2564481474 IAVAS18DAE1C2_DIAG_DATA_EXT4 2;
BA_ "GenSigSendType" SG_ 2564481474 IAVAS18DAE1C2_DIAG_DATA_EXT3 2;
BA_ "GenSigSendType" SG_ 2564481474 IAVAS18DAE1C2_DIAG_DATA_EXT2 2;
BA_ "GenSigSendType" SG_ 2564481474 IAVAS18DAE1C2_DIAG_DATA_EXT1 2;
BA_ "GenSigSendType" SG_ 2564481474 IAVAS18DAE1C2_DIAG_DATA 2;
BA_ "GenSigSendType" SG_ 2564473569 CECU18DAC2E1_DIAG_DATA_EXT7 2;
BA_ "GenSigSendType" SG_ 2564473569 CECU18DAC2E1_DIAG_DATA_EXT6 2;
BA_ "GenSigSendType" SG_ 2564473569 CECU18DAC2E1_DIAG_DATA_EXT5 2;
BA_ "GenSigSendType" SG_ 2564473569 CECU18DAC2E1_DIAG_DATA_EXT4 2;
BA_ "GenSigSendType" SG_ 2564473569 CECU18DAC2E1_DIAG_DATA_EXT3 2;
BA_ "GenSigSendType" SG_ 2564473569 CECU18DAC2E1_DIAG_DATA_EXT2 2;
BA_ "GenSigSendType" SG_ 2564473569 CECU18DAC2E1_DIAG_DATA_EXT1 2;
BA_ "GenSigSendType" SG_ 2564473569 CECU18DAC2E1_DIAG_DATA 2;
BA_ "GenSigSendType" SG_ 2564481218 IAVAS18DAE0C2_DIAG_DATA 2;
BA_ "GenSigSendType" SG_ 2564473568 DNT18DAC2E0_DIAG_DATA 2;
VAL_ 1606 EYE646_1_4_DEADMAN_NOTIFICATION 3 "予備" 2 "予備" 1 "発信要求" 0 "初期値" ;
VAL_ 967 EYE3C7_7_3_WARN_ESCALATION_REQ 7 "Reserve" 6 "MSB_WARN_5" 5 "MSB_WARN_4" 4 "MSB_WARN_3" 3 "MSB_WARN_2" 2 "MSB_WARN_1" 1 "Standby" 0 "OFF" ;
VAL_ 967 EYE3C7_7_6_AEB_MSB_LINK 3 "MSB_AEB_REQ" 2 "MSB_WARN" 1 "Standby" 0 "OFF" ;
VAL_ 967 EYE3C7_4_0_LKS_DMS_COOPERATION 1 "ON" 0 "OFF" ;
VAL_ 967 EYE3C7_4_1_LKS_ACTIVE 1 "ON" 0 "OFF" ;
VAL_ 967 EYE3C7_2_0_ALC_CONTROL 1 "ON" 0 "OFF" ;
VAL_ 967 EYE3C7_2_1_WINKER_OFF_REQ 1 "ON" 0 "OFF" ;
VAL_ 967 EYE3C7_2_2_HORN_HAZARD_ON_REQ 3 "Horn_On" 2 "HornHazard_On" 1 "Hazard_On" 0 "Off" ;
VAL_ 967 EYE3C7_2_4_DR_UNLOCK_REQ 1 "ドアアンロック要求" 0 "要求なし" ;
VAL_ 967 EYE3C7_2_5_WINKER_ON_REQ 3 "OFF_Request" 2 "Turn_Right_Request" 1 "Turn_Left_Request" 0 "OFF" ;
VAL_ 967 EYE3C7_2_7_MRM_ACTIVE 1 "ON" 0 "OFF" ;
VAL_ 966 EYE3C6_7_7_VEHICLE_L_LANE1 1 "ON" 0 "OFF" ;
VAL_ 966 EYE3C6_6_7_VEHICLE_R_LANE1 1 "ON" 0 "OFF" ;
VAL_ 966 EYE3C6_5_7_VEHICLE_MY_WAY1 1 "ON" 0 "OFF" ;
VAL_ 966 EYE3C6_3_0_RADER_RR 3 "TURN_ON3" 2 "TURN_ON2" 1 "TURN_ON1" 0 "TURN_OFF" ;
VAL_ 966 EYE3C6_3_2_RADER_RL 3 "TURN_ON3" 2 "TURN_ON2" 1 "TURN_ON1" 0 "TURN_OFF" ;
VAL_ 966 EYE3C6_3_4_RADER_FR 3 "No_Definition" 2 "BLINK" 1 "TURN_ON" 0 "TURN_OFF" ;
VAL_ 966 EYE3C6_3_6_RADER_FL 3 "No_Definition" 2 "BLINK" 1 "TURN_ON" 0 "TURN_OFF" ;
VAL_ 966 EYE3C6_2_0_RADER_R 3 "TURN_ON3" 2 "TURN_ON2" 1 "TURN_ON1" 0 "TURN_OFF" ;
VAL_ 966 EYE3C6_2_2_MY_WAY_LANE_CAR_COLOR 3 "TURN_AMBER" 2 "TURN_LIGHT_TJA" 1 "TURN_LIGHT" 0 "TURN_DARK" ;
VAL_ 966 EYE3C6_2_4_TARGET_CAR 7 "No_Definition" 6 "No_Definition" 5 "No_Definition" 4 "No_Definition" 3 "LEFT_LANE" 2 "RIGHT_LANE" 1 "OWN_LANE" 0 "OFF" ;
VAL_ 966 EYE3C6_2_7_ALC_STS 1 "ACTIVE" 0 "NOT_ACTIVE" ;
VAL_ 966 EYE3C6_1_4_L_LANE_CAR_COLOR 3 "TURN_AMBER" 2 "TURN_LIGHT_TJA" 1 "TURN_LIGHT" 0 "TURN_DARK" ;
VAL_ 966 EYE3C6_1_6_R_LANE_CAR_COLOR 3 "TURN_AMBER" 2 "TURN_LIGHT_TJA" 1 "TURN_LIGHT" 0 "TURN_DARK" ;
VAL_ 965 EYE3C5_7_0_GSR_AEBS_FUNC_INFO 1 "Requirement" 0 "No requirement" ;
VAL_ 965 EYE3C5_7_1_CSTM_CRV_ADJUST 3 "HARD" 2 "NORMAL" 1 "SOFT" 0 "OFF" ;
VAL_ 965 EYE3C5_7_3_BRAKE_HAPTIC_CURR 3 "BUZZER OFF/BREAK OFF" 2 "BUZZER OFF/BREAK ON" 1 "BUZZER ON/BREAK OFF" 0 "BUZZER ON/BREAK ON" ;
VAL_ 965 EYE3C5_7_5_SAFETY_MODE_FUNC_INFO 1 "Requirement" 0 "No requirement" ;
VAL_ 965 EYE3C5_7_6_SAFETY_MODE_CURR 1 "enable" 0 "disable" ;
VAL_ 965 EYE3C5_7_7_GSR_DDAW_FUNC_INFO 1 "Requirement" 0 "No requirement" ;
VAL_ 965 EYE3C5_6_0_IND_SAFETY_MODE 1 "TURN_ON" 0 "TURN_OFF" ;
VAL_ 965 EYE3C5_6_1_ALC_ACTIVE_L 1 "TURN_ON" 0 "TURN_OFF" ;
VAL_ 965 EYE3C5_6_2_FLASHING_IND_SAFETY 1 "Blinking" 0 "Nomally indicate" ;
VAL_ 965 EYE3C5_6_3_OVERTAKE_FUNC_INFO 1 "Requirement" 0 "No requirement" ;
VAL_ 965 EYE3C5_6_4_CRV_ADJUST_FUNC_INFO 1 "Requirement" 0 "No requirement" ;
VAL_ 965 EYE3C5_6_5_STRG_TOUCHSENSOR_WRNG 1 "TURN_ON" 0 "TURN_OFF" ;
VAL_ 965 EYE3C5_6_6_ALC_ACTIVE_R 1 "TURN_ON" 0 "TURN_OFF" ;
VAL_ 965 EYE3C5_6_7_CSTM_GSR_ISA 1 "Requirement" 0 "No requirement" ;
VAL_ 965 EYE3C5_5_0_LANE_COLOR_R 3 "BLUE" 2 "No_Definition" 1 "GRAY" 0 "OFF" ;
VAL_ 965 EYE3C5_5_2_LINE_LANE_R 3 "No_Definition" 2 "WHITE" 1 "GRAY" 0 "OFF" ;
VAL_ 965 EYE3C5_5_4_LANE_COLOR_L 3 "BLUE" 2 "No_Definition" 1 "GRAY" 0 "OFF" ;
VAL_ 965 EYE3C5_5_6_LINE_LANE_L 3 "No_Definition" 2 "WHITE" 1 "GRAY" 0 "OFF" ;
VAL_ 965 EYE3C5_4_4_ROAD_SHAPE_DIRECTION 1 "LEFT" 0 "RIGHT" ;
VAL_ 965 EYE3C5_4_5_CSTM_GSR_ELKS 1 "Requirement" 0 "No requirement" ;
VAL_ 965 EYE3C5_4_6_MY_WAY_COLOR 3 "BLUE" 2 "No_Definition" 1 "GRAY" 0 "OFF" ;
VAL_ 965 EYE3C5_3_0_AD_DRV_ICON 3 "No_Definition" 2 "BLUE" 1 "WHITE" 0 "TURN_OFF" ;
VAL_ 965 EYE3C5_3_2_AUTO_HANDLE_ICON 3 "No_Definition" 2 "BLINK" 1 "TURN_ON" 0 "TURN_OFF" ;
VAL_ 965 EYE3C5_3_4_WITH_HANDS_ICON 1 "ON" 0 "OFF" ;
VAL_ 965 EYE3C5_3_5_STRG_HAPTIC_WRNG 1 "TURN_ON" 0 "TURN_OFF" ;
VAL_ 965 EYE3C5_3_6_BRK_HPTC_FUNC_INFO 1 "Requirement" 0 "No requirement" ;
VAL_ 965 EYE3C5_3_7_SPECIAL_DISP_INFO 1 "Requirement" 0 "No requirement" ;
VAL_ 965 EYE3C5_2_0_SLOWDWN_CURVE_ICON 7 "No_Definition" 6 "BLINK③" 5 "TURN_ON③" 4 "BLINK②" 3 "TURN_ON②" 2 "BLINK①" 1 "TURN_ON①" 0 "TURN_OFF" ;
VAL_ 965 EYE3C5_2_3_FLASHING_IND 1 "BLINK" 0 "TURN_ON" ;
VAL_ 965 EYE3C5_2_4_ATTENTION_TOLLGATE 3 "No_Definition" 2 "BLINK" 1 "TURN_ON" 0 "TURN_OFF" ;
VAL_ 965 EYE3C5_2_6_MAPLOCATOR_IND 3 "No_Definition" 2 "FAIL_ON" 1 "TURN_ON" 0 "TURN_OFF" ;
VAL_ 965 EYE3C5_1_4_ISA_FAIL_IND 1 "TURN_ON" 0 "TURN_OFF" ;
VAL_ 965 EYE3C5_1_5_SLWF_OFF_IND 1 "TURN_ON" 0 "TURN_OFF" ;
VAL_ 965 EYE3C5_1_6_CSTM_SLWF_SET 1 "ON" 0 "OFF" ;
VAL_ 965 EYE3C5_1_7_CSTM_TSR_SOUND_SET 1 "ON" 0 "OFF" ;
VAL_ 964 EYE3C4_7_0_PCR_FAIL_OFF_IND 3 "No_Definition" 2 "FAIL" 1 "HALT/Customize OFF" 0 "NORMAL" ;
VAL_ 964 EYE3C4_7_2_AES_FAIL_OFF_IND 3 "No_Definition" 2 "FAIL" 1 "HALT/Customize OFF" 0 "NORMAL" ;
VAL_ 964 EYE3C4_7_4_LDP_FAIL_OFF_IND 3 "No_Definition" 2 "FAIL" 1 "HALT/Customize OFF" 0 "NORMAL" ;
VAL_ 964 EYE3C4_7_6_ELK_FAIL_OFF_IND 3 "No_Definition" 2 "FAIL" 1 "HALT/Customize OFF" 0 "NORMAL" ;
VAL_ 964 EYE3C4_6_0_MCAM_SYS_FAIL_HALT 3 "No_Definition" 2 "FAIL" 1 "HALT" 0 "NORMAL" ;
VAL_ 964 EYE3C4_6_2_MCAM_FUNC_INFO 1 "ON" 0 "OFF" ;
VAL_ 964 EYE3C4_6_3_EYE_DRV_ACTION_REQ 7 "No_Definition" 6 "No_Definition" 5 "No_Definition" 4 "restriction2" 3 "restriction1" 2 "permission" 1 "Prohibition" 0 "No Requirement" ;
VAL_ 964 EYE3C4_6_6_LDW_SND_OFF_FAIL_IND 3 "No_Definition" 2 "FAIL" 1 "OFF" 0 "TURN OFF" ;
VAL_ 964 EYE3C4_5_0_EAM_GREEN 3 "PATTERN3" 2 "PATTERN2" 1 "PATTERN1" 0 "TURN_OFF" ;
VAL_ 964 EYE3C4_5_2_EAM_BLUE 3 "PATTERN3" 2 "PATTERN2" 1 "PATTERN1" 0 "TURN_OFF" ;
VAL_ 964 EYE3C4_5_4_EAM_GREEN_2 3 "No_Definition" 2 "BLINK" 1 "ON" 0 "OFF" ;
VAL_ 964 EYE3C4_5_6_FCW_SND_OFF_FAIL_IND 3 "No_Definition" 2 "FAIL" 1 "OFF" 0 "TURN OFF" ;
VAL_ 964 EYE3C4_4_0_EAM_YELLOW 15 "No Definition" 14 "No_Definition" 13 "No_Definition" 12 "No_Definition" 11 "No_Definition" 10 "No_Definition" 9 "No_Definition" 8 "No_Definition" 7 "PATTERN⑦" 6 "PATTERN⑥" 5 "PATTERN⑤" 4 "PATTERN④" 3 "PATTERN③" 2 "PATTERN②" 1 "PATTERN①" 0 "TURN_OFF" ;
VAL_ 964 EYE3C4_4_4_EAM_RED 15 "No Definition" 14 "No_Definition" 13 "No_Definition" 12 "No_Definition" 11 "No_Definition" 10 "No_Definition" 9 "No_Definition" 8 "No_Definition" 7 "PATTERN⑦" 6 "PATTERN⑥" 5 "PATTERN⑤" 4 "PATTERN④" 3 "PATTERN③" 2 "PATTERN②" 1 "PATTERN①" 0 "TURN_OFF" ;
VAL_ 964 EYE3C4_3_0_CODE_NO_BUZZER 255 "Pattern255" 90 "Pattern90" 89 "Pattern89" 88 "Pattern88" 87 "Pattern87" 86 "Pattern86" 84 "Pattern84" 83 "Pattern83" 82 "Pattern82" 81 "Pattern81" 80 "Pattern80" 79 "Pattern79" 78 "Pattern78" 77 "Pattern77" 76 "Pattern76" 75 "Pattern75" 74 "Pattern74" 73 "Pattern73" 72 "Pattern72" 71 "Pattern71" 70 "Pattern70" 69 "Pattern69" 68 "Pattern68" 67 "Pattern67" 66 "Pattern66" 65 "Pattern65" 64 "Pattern64" 63 "Pattern63" 62 "Pattern62" 61 "Pattern61" 60 "Pattern60" 59 "Pattern59" 49 "Pattern49" 48 "Pattern48" 47 "Pattern47" 46 "Pattern46" 45 "Pattern45" 44 "Pattern44" 43 "Pattern43" 42 "Pattern42" 41 "Pattern41" 40 "Pattern40" 39 "Pattern39" 38 "Pattern38" 37 "Pattern37" 36 "Pattern36" 35 "Pattern35" 34 "Pattern34" 33 "Pattern33" 32 "Pattern32" 31 "Pattern31" 30 "Pattern30" 29 "Pattern29" 28 "Pattern28" 27 "Pattern27" 26 "Pattern26" 25 "Pattern25" 24 "Pattern24" 23 "Pattern23" 22 "Pattern22" 21 "Pattern21" 20 "Pattern20" 19 "Pattern19" 18 "Pattern18" 17 "Pattern17" 16 "Pattern16" 15 "Pattern15" 14 "Pattern14" 13 "Pattern13" 12 "Pattern12" 11 "Pattern11" 10 "Pattern10" 9 "Pattern9" 8 "Pattern8" 7 "Pattern7" 6 "Pattern6" 5 "Pattern5" 4 "Pattern4" 3 "Pattern3" 2 "Pattern2" 1 "Pattern1" 0 "OFF" ;
VAL_ 964 EYE3C4_2_0_CODE_WARN 255 "Pattern255" 166 "Pattern166" 165 "Pattern165" 164 "Pattern164" 163 "Pattern163" 162 "Pattern162" 161 "Pattern161" 160 "Pattern160" 159 "Pattern159" 158 "Pattern158" 157 "Pattern157" 156 "Pattern156" 155 "Pattern155" 154 "Pattern154" 153 "Pattern153" 152 "Pattern152" 151 "Pattern151" 150 "Pattern150" 149 "Pattern149" 148 "Pattern148" 147 "Pattern147" 146 "Pattern146" 145 "Pattern145" 144 "Pattern144" 90 "Pattern90" 89 "Pattern89" 88 "Pattern88" 87 "Pattern87" 86 "Pattern86" 85 "Pattern85" 84 "Pattern84" 83 "Pattern83" 82 "Pattern82" 81 "Pattern81" 80 "Pattern80" 79 "Pattern79" 78 "Pattern78" 77 "Pattern77" 76 "Pattern76" 75 "Pattern75" 74 "Pattern74" 73 "Pattern73" 72 "Pattern72" 71 "Pattern71" 70 "Pattern70" 69 "Pattern69" 68 "Pattern68" 67 "Pattern67" 66 "Pattern66" 65 "Pattern65" 64 "Pattern64" 63 "Pattern63" 62 "Pattern62" 61 "Pattern61" 60 "Pattern60" 59 "Pattern59" 58 "Pattern58" 57 "Pattern57" 56 "Pattern56" 55 "Pattern55" 54 "Pattern54" 53 "Pattern53" 52 "Pattern52" 51 "Pattern51" 50 "Pattern50" 49 "Pattern49" 48 "Pattern48" 47 "Pattern47" 46 "Pattern46" 45 "Pattern45" 44 "Pattern44" 43 "Pattern43" 42 "Pattern42" 41 "Pattern41" 40 "Pattern40" 39 "Pattern39" 38 "Pattern38" 37 "Pattern37" 36 "Pattern36" 35 "Pattern35" 34 "Pattern34" 33 "Pattern33" 32 "Pattern32" 31 "Pattern31" 30 "Pattern30" 29 "Pattern29" 28 "Pattern28" 27 "Pattern27" 26 "Pattern26" 25 "Pattern25" 24 "Pattern24" 23 "Pattern23" 22 "Pattern22" 21 "Pattern21" 20 "Pattern20" 19 "Pattern19" 18 "Pattern18" 17 "Pattern17" 16 "Pattern16" 15 "Pattern15" 14 "Pattern14" 13 "Pattern13" 12 "Pattern12" 11 "Pattern11" 10 "Pattern10" 9 "Pattern9" 8 "Pattern8" 7 "Pattern7" 6 "Pattern6" 5 "Pattern5" 4 "Pattern4" 3 "Pattern3" 2 "Pattern2" 1 "Pattern1" 0 "OFF" ;
VAL_ 964 EYE3C4_1_5_SNR_DRV_ACTION_REQ 7 "No_Definition" 6 "No_Definition" 5 "No_Definition" 4 "Restriction2" 3 "Restriction1" 2 "Permission" 1 "Prohibition" 0 "No Requirement" ;
VAL_ 554 EYE22A_2_0_PERMIT_ADB 1 "Hi" 0 "Lo" ;
VAL_ 554 EYE22A_2_1_HBA_MODE 1 "Hi" 0 "Lo" ;
VAL_ 554 EYE22A_2_2_PROCEEDING 1 "Hi" 0 "Lo" ;
VAL_ 554 EYE22A_2_3_ONCOMING 1 "ON" 0 "OFF" ;
VAL_ 554 EYE22A_2_4_OBJ_LEFTMOST 1 "ONCOMING" 0 "NOT_ONCOMING" ;
VAL_ 554 EYE22A_2_5_OBJ_RIGHTMOST 1 "ONCOMING" 0 "NOT_ONCOMING" ;
VAL_ 554 EYE22A_2_6_SENSITIVITY_SETTING 1 "Sensitivity_Setting" 0 "Normal" ;
VAL_ 554 EYE22A_2_7_AHL_DATAFAIL_FLG 1 "Turn_ON" 0 "Turn_OFF" ;
VAL_ 554 EYE22A_1_4_FAIL 1 "FAIL" 0 "OFF" ;
VAL_ 554 EYE22A_1_5_INIT_END 1 "ON" 0 "OFF" ;
VAL_ 554 EYE22A_1_6_HALT 1 "HALT" 0 "OFF" ;
VAL_ 807 EYE327_6_1_EDR_STATUS_ACSF_C 7 "No_Definition" 6 "no equiped" 5 "HALT" 4 "FAIL" 3 "Off" 2 "Active_Right" 1 "Active_Left" 0 "Stand-By" ;
VAL_ 807 EYE327_6_4_EDR_STATUS_MRM 15 "No_Definition" 14 "No_Definition" 13 "No_Definition" 12 "No_Definition" 11 "No_Definition" 10 "No_Definition" 9 "No_Definition" 8 "No_Definition" 7 "No_Definition" 6 "no equiped" 5 "HALT" 4 "FAIL" 3 "OFF" 2 "Engaged_Warinig" 1 "Engaged_Contorol" 0 "On but not engaged" ;
VAL_ 807 EYE327_5_2_EDR_STATUS_FCTB 15 "No_Definition" 14 "No_Definition" 13 "No_Definition" 12 "No_Definition" 11 "No_Definition" 10 "no equiped" 9 "Warning but Non-engaged" 8 "Warning but Non-engaged_Right" 7 "Warning but Non-engaged_Left" 6 "HALT" 5 "FAIL" 4 "Deactivated" 3 "Engaged" 2 "Engaged_Right" 1 "Engaged_Left" 0 "On but Non-engaged" ;
VAL_ 807 EYE327_5_6_EDR_STATUS_ACSF_B1 7 "No_Definition" 6 "No_Definition" 5 "no equiped" 4 "HALT" 3 "FAIL" 2 "Off" 1 "Active" 0 "Stand-By" ;
VAL_ 807 EYE327_4_2_EDR_STATUS_PCB_EYECAM 15 "No_Definition" 14 "No_Definition" 13 "No_Definition" 12 "No_Definition" 11 "No_Definition" 10 "No_Definition" 9 "No_Definition" 8 "No_Definition" 7 "No_Definition" 6 "no equiped" 5 "Warning but Non-engaged" 4 "HALT" 3 "FAIL" 2 "Deactivated" 1 "Engaged" 0 "On but Non-engaged" ;
VAL_ 807 EYE327_4_6_EDR_STATUS_PCB_MCAM 15 "No_Definition" 14 "No_Definition" 13 "No_Definition" 12 "No_Definition" 11 "No_Definition" 10 "No_Definition" 9 "No_Definition" 8 "No_Definition" 7 "No_Definition" 6 "no equiped" 5 "Warning but Non-engaged" 4 "HALT" 3 "FAIL" 2 "Deactivated" 1 "Engaged" 0 "On but Non-engaged" ;
VAL_ 807 EYE327_3_0_EDR_STATUS_CC 7 "No_Definition" 6 "No_Definition" 5 "no equiped" 4 "HALT" 3 "FAIL" 2 "Off" 1 "Engaged" 0 "Non-engaged" ;
VAL_ 807 EYE327_3_3_EDR_STATUS_ACC 7 "No_Definition" 6 "No_Definition" 5 "no equiped" 4 "HALT" 3 "FAIL" 2 "Off" 1 "Engaged" 0 "Non-engaged" ;
VAL_ 807 EYE327_3_6_EDR_STATUS_AEBS 15 "No_Definition" 14 "No_Definition" 13 "No_Definition" 12 "No_Definition" 11 "No_Definition" 10 "No_Definition" 9 "No_Definition" 8 "No_Definition" 7 "No_Definition" 6 "no equiped" 5 "Warning but Non-engaged" 4 "HALT" 3 "FAIL" 2 "Deactivated" 1 "Engaged" 0 "On but Non-engaged" ;
VAL_ 807 EYE327_2_2_EDR_STATUS_ESF_ELK 7 "No_Definition" 6 "no equiped" 5 "HALT" 4 "FAIL" 3 "OFF" 2 "Engaged_Right" 1 "Engaged_Left" 0 "On but not engaged" ;
VAL_ 807 EYE327_2_5_EDR_STATUS_CSF_LDP 7 "No_Definition" 6 "no equiped" 5 "HALT" 4 "FAIL" 3 "OFF" 2 "Engaged_Right" 1 "Engaged_Left" 0 "On but not engaged" ;
VAL_ 807 EYE327_1_4_EDR_STATUS_LDWS 7 "No_Definition" 6 "no equiped" 5 "HALT" 4 "FAIL" 3 "OFF" 2 "On?Warning right" 1 "On?Warning left" 0 "On but not warning" ;
VAL_ 807 EYE327_1_7_EDR_STATUS_ESF_AES 7 "No_Definition" 6 "no equiped" 5 "HALT" 4 "FAIL" 3 "OFF" 2 "Engaged_Right" 1 "Engaged_Left" 0 "On but not engaged" ;
VAL_ 806 EYE326_2_0_MRM_OPE_ST 1 "ON" 0 "OFF" ;
VAL_ 806 EYE326_2_1_DRIVER_TORQUE_STATE 3 "LEVEL_3" 2 "LEVEL_2" 1 "LEVEL_1" 0 "OFF" ;
VAL_ 806 EYE326_2_3_DRIVER_ACCEL_STATE 3 "LEVEL_3" 2 "LEVEL_2" 1 "LEVEL_1" 0 "OFF" ;
VAL_ 806 EYE326_1_4_SYS_ST 1 "ON" 0 "OFF" ;
VAL_ 806 EYE326_1_5_TAKE_OVR_REQ 3 "ON(Type3)" 2 "ON(Type2)" 1 "ON(Type1)" 0 "OFF" ;
VAL_ 806 EYE326_1_7_OVERRIDE 1 "ON" 0 "OFF" ;
VAL_ 805 EYE325_6_5_SONAR_DISP_INT 1 "DISP_INT_ON" 0 "DISP_INT_OFF" ;
VAL_ 805 EYE325_5_0_SONAR_R_L_CORNER_4LVL 7 "No_Definition" 6 "No_Definition" 5 "No_Definition" 4 "MOST_NEAR" 3 "NEAR" 2 "MIDDLE" 1 "FAR" 0 "CLEAR" ;
VAL_ 805 EYE325_5_3_SONAR_R_R_CORNER_4LVL 7 "No_Definition" 6 "No_Definition" 5 "No_Definition" 4 "MOST_NEAR" 3 "NEAR" 2 "MIDDLE" 1 "FAR" 0 "CLEAR" ;
VAL_ 805 EYE325_4_0_SONAR_R_CENTER 7 "No_Definition" 6 "No_Definition" 5 "No_Definition" 4 "MOST_NEAR" 3 "NEAR" 2 "MIDDLE" 1 "FAR" 0 "CLEAR" ;
VAL_ 805 EYE325_4_3_SONAR_LEVEL 7 "No_Definition" 6 "FAR" 5 "FIRST_BRAKE" 4 "SECOND_BRAKE" 3 "MOST_NEAR" 2 "NEAR" 1 "MIDDLE" 0 "OFF" ;
VAL_ 805 EYE325_4_6_RAB_WARNING 3 "RAB_Interrupt_3" 2 "RAB_Interrupt_2" 1 "RAB_Interrupt_1" 0 "OFF" ;
VAL_ 805 EYE325_3_0_SONAR_R_L_CORNER 3 "NEAR" 2 "MIDDLE" 1 "FAR" 0 "CLEAR" ;
VAL_ 805 EYE325_3_2_SONAR_R_R_CORNER 3 "NEAR" 2 "MIDDLE" 1 "FAR" 0 "CLEAR" ;
VAL_ 805 EYE325_3_4_SONAR_R_L_SIDE 3 "NEAR" 2 "MIDDLE" 1 "FAR" 0 "CLEAR" ;
VAL_ 805 EYE325_3_6_SONAR_R_R_SIDE 3 "NEAR" 2 "MIDDLE" 1 "FAR" 0 "CLEAR" ;
VAL_ 805 EYE325_2_0_RAB_OFF 1 "RAB_OFF" 0 "RAB_ON" ;
VAL_ 805 EYE325_2_1_SONAR_OFF 1 "SONAR_OFF" 0 "SONAR_ON" ;
VAL_ 805 EYE325_2_2_SONAR_SYS_HALT 3 "No_Definition" 2 "HALT_2" 1 "HALT_1" 0 "NO_HALT" ;
VAL_ 805 EYE325_2_4_SONAR_SYS_FAIL 3 "No_Definition" 2 "FAIL_2" 1 "FAIL_1" 0 "NO_FAIL" ;
VAL_ 805 EYE325_2_6_RAB_DISABLE 1 "ON" 0 "OFF" ;
VAL_ 805 EYE325_2_7_SONAR_DISABLE 1 "ON" 0 "OFF" ;
VAL_ 805 EYE325_1_4_CSTM_RAB_SET 1 "ON" 0 "OFF" ;
VAL_ 805 EYE325_1_5_CSTM_CLR_SNR_SET 1 "ON" 0 "OFF" ;
VAL_ 805 EYE325_1_6_RAB 1 "ON" 0 "OFF" ;
VAL_ 805 EYE325_1_7_SONAR_NO_DISP 1 "ON" 0 "OFF" ;
VAL_ 804 EYE324_7_5_TSR_MODE_DISP 3 "TURN_ON_BLUE" 2 "TURN_ON_GREEN" 1 "TURN_ON_WHITE" 0 "TURN_OFF" ;
VAL_ 804 EYE324_7_7_ICON_IND 1 "TURN_ON" 0 "TURN_OFF" ;
VAL_ 804 EYE324_6_0_COMPLEMENTARY_IND_C 15 "Reserved" 14 "Reserved" 13 "Reserved" 12 "Reserved" 11 "Reserved" 10 "Reserved" 9 "Reserved" 8 "Reserved" 7 "Reserved" 6 "Arrow Right" 5 "Arrow Left" 4 "Time" 3 "Snow/Ice" 2 "Wet road" 1 "Auxiliary sign" 0 "Not indicate" ;
VAL_ 804 EYE324_6_4_COMPLEMENTARY_IND_D 15 "Reserved" 14 "Reserved" 13 "Reserved" 12 "Reserved" 11 "Reserved" 10 "Reserved" 9 "Reserved" 8 "Reserved" 7 "Reserved" 6 "Arrow Right" 5 "Arrow Left" 4 "Time" 3 "Snow/Ice" 2 "Wet road" 1 "Auxiliary sign" 0 "Not indicate" ;
VAL_ 804 EYE324_4_0_TRAFFIC_SIGN_B 31 "Reserved" 30 "Reserved" 29 "Reserved" 28 "Reserved" 27 "Reserved" 26 "Reserved" 25 "Reserved" 24 "One-Way(up)" 23 "One-Way(right)" 22 "No Passing(RHD)" 21 "No entry (DOM)" 20 "Pause (DOM)" 19 "No overtaking (DOM)" 18 "Preferred road" 17 "Road closure" 16 "Forward precedence road" 15 "Pause" 14 "No entry" 13 "Cancel no overtaking" 12 "No overtaking" 11 "Residential Zone" 10 "One-way(left)" 9 "GiveWay" 8 "Reserved" 7 "Release speed limit(mile)" 6 "Release speed limit(km)" 5 "Full release" 4 "Speed limit design(Sweden)" 3 "Speed limit unknown" 2 "Not applying sign recog." 1 "Limited speed (EU/AU/JP)" 0 "Not indicate" ;
VAL_ 804 EYE324_4_5_FLASHING_IND_B 1 "Blinking" 0 "Nomally indicate" ;
VAL_ 804 EYE324_4_6_FRAME_COLOR_B 3 "No_Definition" 2 "GREEN" 1 "WHITE" 0 "OFF" ;
VAL_ 804 EYE324_2_0_TRAFFIC_SIGN_A 31 "Reserved" 30 "Reserved" 29 "Reserved" 28 "Reserved" 27 "Reserved" 26 "Reserved" 25 "Reserved" 24 "One-Way(up)" 23 "One-Way(right)" 22 "No Passing(RHD)" 21 "No entry (DOM)" 20 "Pause (DOM)" 19 "No overtaking (DOM)" 18 "Preferred road" 17 "Road closure" 16 "Forward precedence road" 15 "Pause" 14 "No entry" 13 "Cancel no overtaking" 12 "No overtaking" 11 "Residential Zone" 10 "One-way" 9 "GiveWay" 8 "Reserved" 7 "Release speed limit(mile)" 6 "Release speed limit(km)" 5 "Full release" 4 "Speed limit design(Sweden)" 3 "Speed limit unknown" 2 "Not applying sign recog." 1 "Limited speed (EU/AU/JP)" 0 "Not indicate" ;
VAL_ 804 EYE324_2_5_FLASHING_IND_A 1 "Blinking" 0 "Nomally indicate" ;
VAL_ 804 EYE324_2_6_FRAME_COLOR_A 3 "No_Definition" 2 "GREEN" 1 "WHITE" 0 "OFF" ;
VAL_ 804 EYE324_1_4_FLASHING_IND_D 1 "Blinking" 0 "Nomally indicate" ;
VAL_ 804 EYE324_1_5_FLASHING_IND_C 1 "Blinking" 0 "Nomally indicate" ;
VAL_ 804 EYE324_1_6_ICON_COLOR 3 "No_Definition" 2 "BLUE" 1 "GREEN" 0 "WHITE" ;
VAL_ 803 EYE323_7_5_SLIF_FUNC_INFO 1 "Requirement" 0 "No requirement" ;
VAL_ 803 EYE323_7_6_ISA_FUNC_INFO 1 "Requirement" 0 "No requirement" ;
VAL_ 803 EYE323_7_7_ISA_CUSTOMIZE_CURR 1 "ISA enable" 0 "ISA disable" ;
VAL_ 803 EYE323_6_0_LDW_OFFSW_INFO 1 "requirement" 0 "No requirement" ;
VAL_ 803 EYE323_6_1_LDW_ON_OFF_SET 1 "enable" 0 "disable" ;
VAL_ 803 EYE323_6_2_CSTM_DDAW_WARN_SET 1 "ON" 0 "OFF" ;
VAL_ 803 EYE323_6_3_IACC_FUNC_INFO 1 "Requirement" 0 "No requirement" ;
VAL_ 803 EYE323_6_5_CSTM_LDW_TIMING_SET 1 "LATE" 0 "EARLY" ;
VAL_ 803 EYE323_6_6_CSTM_LDW_TIMING 1 "Requirement" 0 "No requirement" ;
VAL_ 803 EYE323_6_7_SLOWDOWNL_FUNC_INFO 1 "Requirement" 0 "No requirement" ;
VAL_ 803 EYE323_5_0_CNG_GRN_CONT_CURR 1 "enable" 0 "disable" ;
VAL_ 803 EYE323_5_1_TRAFFIC_FUNC_INFO 1 "Requirement" 0 "No requirement" ;
VAL_ 803 EYE323_5_2_FCW_OFFSW_INFO 1 "requirement" 0 "No requirement" ;
VAL_ 803 EYE323_5_3_FCW_ON_OFF_SET 1 "enable" 0 "disable" ;
VAL_ 803 EYE323_5_4_WARNING_SEL_CURR 1 "Vibration" 0 "Sound" ;
VAL_ 803 EYE323_5_5_HAPT_FUNC_INFO 1 "Requirement" 0 "No requirement" ;
VAL_ 803 EYE323_5_6_TOLLGATE_CONT_CURR 1 "enable" 0 "disable" ;
VAL_ 803 EYE323_5_7_CURVE_CONT_CURR 1 "enable" 0 "disable" ;
VAL_ 803 EYE323_4_0_FCTB_ICON_L 3 "No_Definition" 2 "BLINK" 1 "TURN_ON" 0 "TURN_OFF" ;
VAL_ 803 EYE323_4_2_FCTB_ICON_R 3 "No_Definition" 2 "BLINK" 1 "TURN_ON" 0 "TURN_OFF" ;
VAL_ 803 EYE323_4_4_FCW_CONT_CURR 3 "OFF" 2 "FAR" 1 "NEAR" 0 "ON/STD." ;
VAL_ 803 EYE323_4_6_FCW_DISPLAY_SEL 3 "FULL SELECT" 2 "ON/OFF SELECT" 1 "Distance SELECT" 0 "TURN OFF" ;
VAL_ 803 EYE323_3_0_AES_FUNC_INFO 1 "Requirement" 0 "No requirement" ;
VAL_ 803 EYE323_3_1_CSTM_TSR_NO_ENTRY_SET 1 "ON" 0 "OFF" ;
VAL_ 803 EYE323_3_2_CSTM_TSR_STOP_SET 1 "ON" 0 "OFF" ;
VAL_ 803 EYE323_3_3_CSTM_TSR_GIVE_WAY_SET 1 "ON" 0 "OFF" ;
VAL_ 803 EYE323_3_4_WILDERNESS 1 "WILDERNESS" 0 "NOT_WILDERNESS" ;
VAL_ 803 EYE323_3_5_AES_OFF 1 "TURN_ON" 0 "TURN_OFF" ;
VAL_ 803 EYE323_3_6_FCTB_IND 3 "No_Definition" 2 "FAIL_ON" 1 "TURN_ON" 0 "TURN_OFF" ;
VAL_ 803 EYE323_2_0_CSTM_LDW_ALK_B 3 "ALK-B ON /LDW ON" 2 "ALK-B ON /LDW OFF" 1 "ALK-B OFF/LDW ON" 0 "ALK-B OFF/LDW OFF" ;
VAL_ 803 EYE323_2_2_CSTM_P_CR 1 "ON" 0 "OFF" ;
VAL_ 803 EYE323_2_3_SLOWDOWN_FUNC_INFO2 1 "Requirement" 0 "No requirement" ;
VAL_ 803 EYE323_2_4_CID_CODE_WARN 15 "Drowsiness attention" 14 "Eyes on request(3rd/4th)" 13 "Eyes on request(2nd)" 12 "MRM Interruption Vehicle" 11 "MRM Interruption Steering" 10 "MRM Interruption Lane change" 9 "MRM Stop" 8 "Handle steering" 7 "MRM Lane change Left" 6 "MRM Lane change Right" 5 "MRM Road shoulder Evacuation" 4 "B1 no-opr. cancel alarm" 3 "B1 no-opr. warning(long)" 2 "MRM Operation Notice" 1 "PreCrashBreak(1st)/Brake incr. alarm" 0 "No alarm " ;
VAL_ 803 EYE323_1_4_DISP_FOLLOW_FORWARD 1 "ON" 0 "OFF" ;
VAL_ 803 EYE323_1_5_KEEP_LINE_SENTER_ACT 1 "ON" 0 "OFF" ;
VAL_ 803 EYE323_1_6_DDAW_FAIL_OFF 3 "No_Definition" 2 "OFF" 1 "FAIL" 0 "TURN_OFF" ;
VAL_ 802 EYE322_7_0_CSTM_ACC_CONT_SET 3 "Lv.4" 2 "Lv.3" 1 "Lv.2" 0 "Lv.1" ;
VAL_ 802 EYE322_7_2_ELK_OFF_IND 1 "ON" 0 "OFF" ;
VAL_ 802 EYE322_7_3_LIGHT_EAM_YELLOW 3 "TURN_ON" 2 "BLINK_FAST" 1 "NONE" 0 "NONE" ;
VAL_ 802 EYE322_7_5_BROKEN_LINE_L 1 "DASHEDLINE" 0 "SOLIDLINE" ;
VAL_ 802 EYE322_7_6_TJA_ACTIVE 1 "ON" 0 "OFF" ;
VAL_ 802 EYE322_7_7_BROKEN_LINE_R 1 "DASHEDLINE" 0 "SOLIDLINE" ;
VAL_ 802 EYE322_6_0_CSTM_MIS_AT_START 3 "ON(20km/h)/(15mph)" 2 "ON(15km/h)/(10mph)" 1 "ON(10km/h)/(5mph)" 0 "OFF" ;
VAL_ 802 EYE322_6_2_CSTM_ALK_TJA_SET 1 "ON" 0 "OFF" ;
VAL_ 802 EYE322_6_3_CSTM_LANE_SET 1 "LEFT" 0 "RIGHT" ;
VAL_ 802 EYE322_6_4_LDP_OFF_IND 1 "TURN_ON" 0 "TURN_OFF" ;
VAL_ 802 EYE322_6_5_INDICATOR_MODE_L 3 "NONE" 2 "BLINK" 1 "TURN_ON" 0 "TURN_OFF" ;
VAL_ 802 EYE322_6_7_CSTM_ELK_SET 1 "ON" 0 "OFF" ;
VAL_ 802 EYE322_5_0_CSTM_MIS_AT_BACK 1 "ACTIVE" 0 "NON_ACTIVE" ;
VAL_ 802 EYE322_5_1_CSTM_ALK_TJA 1 "ACTIVE" 0 "NON_ACTIVE" ;
VAL_ 802 EYE322_5_2_CSTM_SAS 1 "ACTIVE" 0 "NON_ACTIVE" ;
VAL_ 802 EYE322_5_3_CSTM_HBA 1 "ACTIVE" 0 "NON_ACTIVE" ;
VAL_ 802 EYE322_5_4_CSTM_ACC_CONT 1 "ACTIVE" 0 "NON_ACTIVE" ;
VAL_ 802 EYE322_5_5_CSTM_LANE 1 "ACTIVE" 0 "NON_ACTIVE" ;
VAL_ 802 EYE322_5_6_LDW_SOUND_OFF_IND 1 "TURN_ON" 0 "TURN_OFF" ;
VAL_ 802 EYE322_5_7_CSTM_ELK_SET 1 "CSTM_ELK_ON" 0 "CSTM_ELK_OFF" ;
VAL_ 802 EYE322_4_0_CODE_WARN 31 "No_Definition" 30 "WARN_ALK_No_Steering_CONT(Only_Buzzer)" 29 "No_Definition" 28 "WARN_LKSA(No_Steering_CONT_Long)" 27 "ALK_Cancel(Only_Buzzer)" 26 "ACC_Cancel(Only_Buzzer)" 25 "Catch/Lost_Buzzer" 24 "Buzzer(No_Display)" 23 "No_Definition" 22 "No_Definition" 21 "No_Definition" 20 "Long Intervention(ALKB)" 19 "Blue Traffic Light Alert" 18 "WARN_ALK_System_Limit" 17 "No_Definition" 16 "WARN_ELK_Left" 15 "WARN_ELK_Right" 14 "Forward_Start_INFO" 13 "WARN_Lane_Sway" 12 "WARN_Lane_Departure(LDW/LDP) Left" 11 "WARN_Lane_Departure(LDW/LDP) Right" 10 "No_Definition" 9 "PreCrash_BRK(Stop_Warning)" 8 "WARN_Red_Signal" 7 "No_Definition" 6 "No_Definition" 5 "AfterPreCrash_BRK(Stopping)" 4 "AT_Accidental_Backward_Start(FMW)" 3 "AT_Accidental_Backward_Start(Speed_Limit_Warning)" 2 "PreCrash_BRK(First)" 1 "PreCrash_BRK(Second)" 0 "No_Warning" ;
VAL_ 802 EYE322_4_5_CSTM_GSR 1 "Requirement" 0 "No Requirement" ;
VAL_ 802 EYE322_3_0_LANE_L 3 "No_Definition" 2 "BLINK" 1 "TURN_ON" 0 "TURN_OFF" ;
VAL_ 802 EYE322_3_2_LANE_R 3 "No_Definition" 2 "BLINK" 1 "TURN_ON" 0 "TURN_OFF" ;
VAL_ 802 EYE322_3_4_LANE_L_COLOR 3 "AMBER" 2 "OTHER" 1 "WHITE" 0 "SUB" ;
VAL_ 802 EYE322_3_6_LANE_R_COLOR 3 "AMBER" 2 "OTHER" 1 "WHITE" 0 "SUB" ;
VAL_ 802 EYE322_2_0_FCW_OFF_IND 1 "TURN_ON" 0 "TURN_OFF" ;
VAL_ 802 EYE322_2_1_MOV_EYESIGHT_SCREEN 1 "DISP_EYE" 0 "OFF" ;
VAL_ 802 EYE322_2_2_ALK_ICON 3 "BLINK_GREEN" 2 "TURN_ON_GREEN" 1 "TURN_ON_WHITE" 0 "TURN_OFF" ;
VAL_ 802 EYE322_2_4_INDICATOR_CTRL_REQ 1 "ON" 0 "OFF" ;
VAL_ 802 EYE322_2_5_INDICATOR_MODE_R 3 "NONE" 2 "BLINK" 1 "TURN_ON" 0 "TURN_OFF" ;
VAL_ 802 EYE322_2_7_LIMITER_BACK_SPEED 1 "ON" 0 "OFF" ;
VAL_ 802 EYE322_1_4_CODE_NO_BUZZER 7 "WARN_LKSA(No_Steering_CONT_Long)" 6 "AfterPreCrash_BRK(Running)" 5 "Driver_Over_Ride" 4 "MT_Put_In_Gear_Request" 3 "MT_Shift_Down_Request" 2 "MT_Shift_Up_Request" 1 "WARN_LKSA(No_Steering_CONT)" 0 "No_Warning" ;
VAL_ 802 EYE322_1_7_DISTWARN_DMS 1 "ON" 0 "OFF" ;
VAL_ 801 EYE321_7_0_INFO_DIST_FORWARD 15 "75 ≦ x" 14 "70 ≦ x < 75" 13 "65 ≦ x < 70" 12 "60 ≦ x < 65" 11 "55 ≦ x < 60" 10 "50 ≦ x < 55" 9 "45 ≦ x < 50" 8 "40 ≦ x < 45" 7 "35 ≦ x < 40" 6 "30 ≦ x < 35" 5 "25 ≦ x < 30" 4 "20 ≦ x < 25" 3 "15 ≦ x < 20" 2 "10 ≦ x < 15" 1 "5 ≦ x < 10" 0 "0 ≦ x < 5" ;
VAL_ 801 EYE321_7_4_INFO_KEEP_STOP 1 "TURN_ON" 0 "TURN_OFF" ;
VAL_ 801 EYE321_7_5_INFO_READY 1 "TURN_ON" 0 "TURN_OFF" ;
VAL_ 801 EYE321_7_6_INFO_SET_CC 1 "TURN_ON" 0 "TURN_OFF" ;
VAL_ 801 EYE321_7_7_INFO_OFF 1 "TURN_ON" 0 "TURN_OFF" ;
VAL_ 801 EYE321_6_0_FAIL_EYESIGHT 1 "FAIL" 0 "NORMAL" ;
VAL_ 801 EYE321_6_1_MOV_EYESIGHT_SCREEN 1 "DISP_EYE" 0 "OFF" ;
VAL_ 801 EYE321_6_2_IND_VEHICLE 1 "TURN_ON" 0 "TURN_OFF" ;
VAL_ 801 EYE321_6_3_BRAKELAMP_VEHICLE 1 "TURN_ON" 0 "TURN_OFF" ;
VAL_ 801 EYE321_6_4_IND_FORWARD_VECL 1 "TURN_ON" 0 "TURN_OFF" ;
VAL_ 801 EYE321_6_5_BRAKELAMP_FORWARD 1 "TURN_ON" 0 "TURN_OFF" ;
VAL_ 801 EYE321_6_6_CC_OR_LIM_SON 1 "SET" 0 "Non-SET" ;
VAL_ 801 EYE321_6_7_TEMP_OFF_STATE 1 "Temp OFF State" 0 "Normal State" ;
VAL_ 801 EYE321_4_0_ACC_MODE 3 "No_Definition" 2 "SAS" 1 "CC" 0 "ACC" ;
VAL_ 801 EYE321_4_2_SRVD_LASTMEM_ST_REQ 1 "LASTMEM_STARTUP_REQ" 0 "ON_STARTUP_REQ" ;
VAL_ 801 EYE321_4_3_INFO_MAIN_CC 3 "TURN_ON_BLUE or BLINK_GREEN" 2 "TURN_ON_GREEN" 1 "TURN_ON_WHITE" 0 "TURN_OFF" ;
VAL_ 801 EYE321_4_5_TRAFFIC_LIGHT 7 "No_Definition" 6 "No_Definition" 5 "BLINK_BLUE" 4 "TURN_ON_BLUE" 3 "BLINK_RED" 2 "TURN_ON_RED" 1 "TURN_ON_DISP" 0 "TURN_OFF" ;
VAL_ 801 EYE321_3_0_CODE_HALT 7 "HALT_NOTICE" 6 "No_Definition" 5 "No_Definition" 4 "HALT_E3" 3 "HALT_E2" 2 "HALT_E1-2" 1 "HALT_E1-1" 0 "No HALT" ;
VAL_ 801 EYE321_3_3_ELK_EQUIP 1 "EQUIP_ELK" 0 "NOT_EQUIP_ELK" ;
VAL_ 801 EYE321_3_4_SET_DIST 7 "No_Definition" 6 "No_Definition" 5 "No_Definition" 4 "Distance(4)" 3 "Distance(3)" 2 "Distance(2)" 1 "Distance(1)" 0 "No_Display" ;
VAL_ 801 EYE321_3_7_TJA 1 "ON" 0 "OFF" ;
VAL_ 801 EYE321_2_0_ACC_CANCEL_OR_CSTM 15 "No_Definition" 14 "No_Definition" 13 "No_Definition" 12 "No_Definition" 11 "Pattern11" 10 "Pattern10" 9 "Pattern9" 8 "Pattern8" 7 "Pattern7" 6 "Pattern6" 5 "Pattern5" 4 "Pattern4" 3 "Pattern3" 2 "Pattern2" 1 "Pattern1" 0 "OFF" ;
VAL_ 801 EYE321_2_4_ALK_CANCEL_OR_CSTM 7 "Lka_Cancel_DMS_Undetected" 6 "No_Definition" 5 "Lka_Cancel_Speed_High" 4 "Lka_Cancel_Speed_Low" 3 "Lka_Cancel_Other" 2 "Lka_Cancel_No_Steering_CONT" 1 "Lka_Cancel_Curve" 0 "No_Display" ;
VAL_ 801 EYE321_2_7_ALK_CANCEL_DISP_TYPE 1 "ALK-Bｷｬﾝｾﾙ時" 0 "ALK-Cｷｬﾝｾﾙ時" ;
VAL_ 801 EYE321_1_4_PRECRASH_BRAKE_OFF 1 "TURN_ON" 0 "TURN_OFF" ;
VAL_ 801 EYE321_1_5_LANE_DEPARTURE_OFF 1 "TURN_ON" 0 "TURN_OFF" ;
VAL_ 801 EYE321_1_6_MET_AD_DRV_ASS 1 "ON" 0 "OFF" ;
VAL_ 801 EYE321_1_7_ALC_EQUIP 1 "ON" 0 "OFF" ;
VAL_ 556 EYE22C_7_0_COMMANDSW_CC 7 "MSA_SW_ON" 6 "CANCEL_SW_ON" 5 "DISTANCE_SW_ON" 4 "RES/+_SW_ON" 3 "LKS_SW_ON" 2 "SET/-_SW_ON" 1 "CRUISE_MAIN_SW_ON" 0 "ALL_SW_OFF" ;
VAL_ 556 EYE22C_7_3_MODE_CC 1 "CC" 0 "ACC" ;
VAL_ 556 EYE22C_7_4_CC_SETLAMP_INFO 1 "ON" 0 "OFF" ;
VAL_ 556 EYE22C_7_5_MSA_CNT_STS_EGI_HEV 1 "During control" 0 "Uncontrolled" ;
VAL_ 556 EYE22C_7_6_SET_MSA 1 "SET" 0 "Non-SET" ;
VAL_ 556 EYE22C_7_7_SET_CC 1 "SET" 0 "Non-SET" ;
VAL_ 556 EYE22C_4_0_BLIPPING_INHI 1 "ON" 0 "OFF" ;
VAL_ 556 EYE22C_4_4_ACTIVE_BRAKE_ACC 1 "ACTIVE" 0 "PASSIVE" ;
VAL_ 556 EYE22C_4_5_REQ_FMW 1 "REQ" 0 "NON_REQ" ;
VAL_ 556 EYE22C_4_6_FLG_BEFORE_RESERVE 1 "Keep Stop&Before Reseve" 0 "Not Keep Stop" ;
VAL_ 556 EYE22C_4_7_REQ_TARGET_TORQUE 1 "TORQUE" 0 "FORCE" ;
VAL_ 556 EYE22C_1_4_FLG_ADAPTIVE_CC 1 "ADAPTIVE_CC" 0 "OTHER" ;
VAL_ 556 EYE22C_1_5_MAIN_CC 1 "ON" 0 "OFF" ;
VAL_ 556 EYE22C_1_6_FLG_EYESIGHT_VERSION 1 "Ver.4" 0 "Ver.3" ;
VAL_ 556 EYE22C_1_7_FAIL_EYESIGHT 1 "FAIL" 0 "NORMAL" ;
VAL_ 546 EYE222_4_5_AEB_2ND_BRK_ACT 1 "ACTIVE" 0 "NON_ACTIVE" ;
VAL_ 546 EYE222_3_5_REQ_TARGET_RPM_CVT 1 "REQ" 0 "NON_REQ" ;
VAL_ 546 EYE222_3_6_STATE_BRAKE_ACC 1 "ACTIVE" 0 "PASSIVE" ;
VAL_ 546 EYE222_3_7_COOPERATE_EYE_ISS 1 "ACTIVE" 0 "NON_ACTIVE" ;
VAL_ 546 EYE222_1_4_MSA_CONT_STATUS_TCU 1 "control" 0 "NON_Control" ;
VAL_ 546 EYE222_1_7_FAIL_EYESIGHT 1 "FAIL" 0 "NORMAL" ;
VAL_ 545 EYE221_7_0_COMMANDSW_CC 7 "MSAｽｲｯﾁON" 6 "ｷｬﾝｾﾙｽｲｯﾁON" 5 "RES/＋（深）ｽｲｯﾁON" 4 "RES/＋（浅）ｽｲｯﾁON" 3 "SET/－（深）ｽｲｯﾁON" 2 "SET/－（浅）ｽｲｯﾁON" 1 "CRUISEﾒｲﾝｽｲｯﾁON" 0 "ｸﾙｺﾝｽｲｯﾁALL OFF" ;
VAL_ 545 EYE221_7_3_MODE_CC 1 "CC" 0 "ACC" ;
VAL_ 545 EYE221_7_4_MSA_CNT_STS_EGI_HEV 2 "override" 1 "control" 0 "NON_Control" ;
VAL_ 545 EYE221_7_6_EQUIP_MSA 1 "EQUIP_MSA" 0 "NOT_EQUIP_MSA" ;
VAL_ 545 EYE221_7_7_INHIBIT_FUEL_CUT 1 "FUELCUT_NG" 0 "FUELCUT_OK" ;
VAL_ 545 EYE221_4_0_STATE_TRACKING 1 "TRACKING" 0 "NON_TRACKING" ;
VAL_ 545 EYE221_4_1_STATE_LSF 1 "LSF" 0 "NON_LSF" ;
VAL_ 545 EYE221_4_2_FORCED_CANCEL_ACC 1 "CANCEL" 0 "NON_CANCEL" ;
VAL_ 545 EYE221_4_3_BRAKE_TYPE 1 "ACTIVE_BOOSTER" 0 "VDC" ;
VAL_ 545 EYE221_4_4_ACTIVE_BRAKE_ACC 1 "ACTIVE" 0 "PASSIVE" ;
VAL_ 545 EYE221_4_5_REQ_FMW 1 "REQ" 0 "NON_REQ" ;
VAL_ 545 EYE221_4_6_FLG_BEFORE_RESERVE 1 "Keep Stop&Before Reseve" 0 "Not Keep Stop" ;
VAL_ 545 EYE221_1_4_FLG_ADAPTIVE_CC 1 "ADAPTIVE_CC" 0 "OTHER" ;
VAL_ 545 EYE221_1_5_CANCEL_SW_INFO 1 "ACTIVE" 0 "NON_ACTIVE" ;
VAL_ 545 EYE221_1_6_FLG_EYESIGHT_VERSION 1 "Ver.4" 0 "Ver.3" ;
VAL_ 545 EYE221_1_7_FAIL_EYESIGHT 1 "FAIL" 0 "NORMAL" ;
VAL_ 1746 LCT6D2_5_0_HDMAP_RELEASE_SEASON 4 "4" 3 "3" 2 "2" 1 "1" ;
VAL_ 1746 LCT6D2_1_5_ADASMAP_FLAG 1 "ON" 0 "OFF" ;
VAL_ 1746 LCT6D2_1_6_HDMAP_FLAG 1 "ON" 0 "OFF" ;
VAL_ 1746 LCT6D2_1_7_GSRISA_FLAG 1 "ON" 0 "OFF" ;
VAL_ 916 ADAS394_2_2_STRGECU_FAIL 1 "DETECT" 0 "NON_DETECT" ;
VAL_ 916 ADAS394_2_1_STRGHTR_OPEN_FAIL 1 "DETECT" 0 "NON_DETECT" ;
VAL_ 916 ADAS394_2_0_STRGHTR_SHORT_FAIL 1 "DETECT" 0 "NON_DETECT" ;
VAL_ 916 ADAS394_1_7_COMM_STRGECU 1 "Fail" 0 "Normal" ;
VAL_ 916 ADAS394_1_4_STRGHTR_STATE 3 "Reserve" 2 "LOW" 1 "HIGH" 0 "OFF" ;
VAL_ 1304 BEV518_1_4_ActiveWakeUpBit 1 "active wakeup" 0 "passive wakeup" ;
VAL_ 1541 BEV605_3_0_IGBHLDRQ 1 "保持要求あり" 0 "保持要求なし" ;
VAL_ 1541 BEV605_3_2_ILK 1 "ILK検知" 0 "ILK未検知" ;
VAL_ 1541 BEV605_3_3_HVSYSNG 1 "使用不可" 0 "使用可能" ;
VAL_ 1537 BEV601_2_0_IMBSTS 1 "セット" 0 "アンセット" ;
VAL_ 1537 BEV601_2_1_RDYNGSTS 3 "未定義" 2 "不可(異常)" 1 "不可" 0 "OFF" ;
VAL_ 1537 BEV601_1_4_CDEVANS 1 "ON" 0 "OFF" ;
VAL_ 495 BEV1EF_6_0_RRMOTROT_BK 3 "FS固定値" 2 "FSバックアップ値(符号無し)" 1 "FSバックアップ値" 0 "センサ値" ;
VAL_ 495 BEV1EF_6_2_FRMOTROT_BK 3 "FS固定値" 2 "FSバックアップ値(符号無し)" 1 "FSバックアップ値" 0 "センサ値" ;
VAL_ 267 BEV10B_6_7_SPEC8 1 "PERMIT" 0 "INHIBIT" ;
VAL_ 267 BEV10B_6_6_SPEC7 1 "PERMIT" 0 "INHIBIT" ;
VAL_ 267 BEV10B_6_5_SPEC6 1 "PERMIT" 0 "INHIBIT" ;
VAL_ 267 BEV10B_6_4_SPEC5 1 "PERMIT" 0 "INHIBIT" ;
VAL_ 267 BEV10B_6_3_SPEC4 1 "PERMIT" 0 "INHIBIT" ;
VAL_ 267 BEV10B_6_2_SPEC3 1 "PERMIT" 0 "INHIBIT" ;
VAL_ 267 BEV10B_6_1_SPEC2 1 "PERMIT" 0 "INHIBIT" ;
VAL_ 267 BEV10B_6_0_SPEC1 1 "PERMIT" 0 "INHIBIT" ;
VAL_ 267 BEV10B_5_2_DENO 1 "PERMIT" 0 "INHIBIT" ;
VAL_ 267 BEV10B_5_1_PROHIBIT_INC 1 "INHIBIT" 0 "PERMIT" ;
VAL_ 267 BEV10B_5_0_PERMIT_INC 1 "PERMIT" 0 "INHIBIT" ;
VAL_ 267 BEV10B_3_2_OBDRDY 1 "OBDReady-ON" 0 "OBDReady-OFF" ;
VAL_ 267 BEV10B_3_0_DRVRDY 3 "Undefine" 2 "Turn_ON" 1 "Flash" 0 "Turn_Off" ;
VAL_ 116 BEV074_7_0_LVPWRDWN 3 "抑制レベル3" 2 "抑制レベル2" 1 "抑制レベル1" 0 "抑制要求なし" ;
VAL_ 116 BEV074_7_6_CHRCONSTA 1 "Connected" 0 "NotConnected" ;
VAL_ 116 BEV074_7_7_VEHICLE_IGN 1 "ON" 0 "OFF" ;
VAL_ 116 BEV074_6_0_EV_CAU 3 "Undefine" 2 "Flash" 1 "Turn_On" 0 "Turn_Off" ;
VAL_ 116 BEV074_6_2_BEV_OBD_CAU 7 "Undefine" 6 "Undefine" 5 "Undefine" 4 "Initial_Check" 3 "Flash_3Hz" 2 "Flash_1Hz" 1 "Turn_On" 0 "Turn_Off" ;
VAL_ 116 BEV074_6_5_SIDRIVE_DISP 7 "PreS#" 6 "S#_TADAN" 5 "X(DEEP SNOW・MUD)" 4 "X(SNOW･DIRT)" 3 "S" 2 "I" 1 "S#" 0 "TURN_OFF" ;
VAL_ 116 BEV074_5_0_ACCHG_STATE 1 "充電実施中" 0 "充電未実施" ;
VAL_ 116 BEV074_5_1_DCCHG_STATE 1 "DC充電実施中" 0 "DC充電未実施" ;
VAL_ 116 BEV074_5_2_RANGE_DG 1 "異常" 0 "正常" ;
VAL_ 116 BEV074_5_3_ACCP_DG 1 "ON" 0 "OFF" ;
VAL_ 116 BEV074_5_4_REZ_SPD_BK 3 "FS固定値" 2 "FSバックアップ値(符号無し)" 1 "FSバックアップ値" 0 "センサ値" ;
VAL_ 116 BEV074_5_6_OBDRDY 1 "Ready-ON" 0 "Ready-OFF" ;
VAL_ 116 BEV074_5_7_FHVB 1 "ON" 0 "OFF" ;
VAL_ 116 BEV074_3_0_RANGE_POS 7 "未定義" 6 "blank" 5 "未定義" 4 "B" 3 "D" 2 "N" 1 "R" 0 "P" ;
VAL_ 116 BEV074_3_3_DRVRDY 3 "Undefine" 2 "Turn_ON" 1 "Flash" 0 "Turn_Off" ;
VAL_ 116 BEV074_3_5_HVSYSTS 3 "停止処理中" 2 "起動処理中" 1 "起動" 0 "停止" ;
VAL_ 116 BEV074_1_4_RANGE_DG2 1 "異常" 0 "正常" ;
VAL_ 116 BEV074_1_5_REZ_SPD_BK 5 "FS固定値" 4 "RrFSバックアップ値(符号無し)" 3 "FrFSバックアップ値(符号無し)" 2 "Rrセンサ値" 1 "Frセンサ値" 0 "FrRrセンサ値" ;
